VERSION ""

NS_ :

BS_:

BU_: FBD_HL IPB_App1 FBD_HM FBD_HR FBD_Miko FBD_MM FBD_Trunk FBD_VL FBD_VM FBD_VR Diagnosetool_CAN_FD_IPB_41

BO_ 352 StatusCPDData3FBD_Miko: 64 FBD_Miko
 SG_ StatusCPDData3FBD_Miko_MsgCounte : 0|8@1+ (1.0,0) [0|252] "" IPB_App1
 SG_ StatusCPDData3FBD_Miko_LinkID : 8|8@1+ (1.0,0) [0|252] "" IPB_App1
 SG_ StatusCPDData3FBD_Miko_AGCValue : 16|8@1+ (1.0,0) [0|252] "" IPB_App1
 SG_ StatusCPDData3FBD_Miko_Channel : 24|8@1+ (1.0,0) [0|252] "" IPB_App1
 SG_ StatusCPDData3FBD_Miko_CIRData00 : 32|8@1+ (1.0,0) [0|255] "" IPB_App1
 SG_ StatusCPDData3FBD_Miko_CIRData01 : 40|8@1+ (1.0,0) [0|255] "" IPB_App1
 SG_ StatusCPDData3FBD_Miko_CIRData02 : 48|8@1+ (1.0,0) [0|255] "" IPB_App1
 SG_ StatusCPDData3FBD_Miko_CIRData03 : 56|8@1+ (1.0,0) [0|255] "" IPB_App1
 SG_ StatusCPDData3FBD_Miko_CIRData04 : 64|8@1+ (1.0,0) [0|255] "" IPB_App1
 SG_ StatusCPDData3FBD_Miko_CIRData05 : 72|8@1+ (1.0,0) [0|255] "" IPB_App1
 SG_ StatusCPDData3FBD_Miko_CIRData06 : 80|8@1+ (1.0,0) [0|255] "" IPB_App1
 SG_ StatusCPDData3FBD_Miko_CIRData07 : 88|8@1+ (1.0,0) [0|255] "" IPB_App1
 SG_ StatusCPDData3FBD_Miko_CIRData08 : 96|8@1+ (1.0,0) [0|255] "" IPB_App1
 SG_ StatusCPDData3FBD_Miko_CIRData09 : 104|8@1+ (1.0,0) [0|255] "" IPB_App1
 SG_ StatusCPDData3FBD_Miko_CIRData10 : 112|8@1+ (1.0,0) [0|255] "" IPB_App1
 SG_ StatusCPDData3FBD_Miko_CIRData11 : 120|8@1+ (1.0,0) [0|255] "" IPB_App1
 SG_ StatusCPDData3FBD_Miko_CIRData12 : 128|8@1+ (1.0,0) [0|255] "" IPB_App1
 SG_ StatusCPDData3FBD_Miko_CIRData13 : 136|8@1+ (1.0,0) [0|255] "" IPB_App1
 SG_ StatusCPDData3FBD_Miko_CIRData14 : 144|8@1+ (1.0,0) [0|255] "" IPB_App1
 SG_ StatusCPDData3FBD_Miko_CIRData15 : 152|8@1+ (1.0,0) [0|255] "" IPB_App1
 SG_ StatusCPDData3FBD_Miko_CIRData16 : 160|8@1+ (1.0,0) [0|255] "" IPB_App1
 SG_ StatusCPDData3FBD_Miko_CIRData17 : 168|8@1+ (1.0,0) [0|255] "" IPB_App1
 SG_ StatusCPDData3FBD_Miko_CIRData18 : 176|8@1+ (1.0,0) [0|255] "" IPB_App1
 SG_ StatusCPDData3FBD_Miko_CIRData19 : 184|8@1+ (1.0,0) [0|255] "" IPB_App1
 SG_ StatusCPDData3FBD_Miko_CIRData20 : 192|8@1+ (1.0,0) [0|255] "" IPB_App1
 SG_ StatusCPDData3FBD_Miko_CIRData21 : 200|8@1+ (1.0,0) [0|255] "" IPB_App1
 SG_ StatusCPDData3FBD_Miko_CIRData22 : 208|8@1+ (1.0,0) [0|255] "" IPB_App1
 SG_ StatusCPDData3FBD_Miko_CIRData23 : 216|8@1+ (1.0,0) [0|255] "" IPB_App1
 SG_ StatusCPDData3FBD_Miko_CIRData24 : 224|8@1+ (1.0,0) [0|255] "" IPB_App1
 SG_ StatusCPDData3FBD_Miko_CIRData25 : 232|8@1+ (1.0,0) [0|255] "" IPB_App1
 SG_ StatusCPDData3FBD_Miko_CIRData26 : 240|8@1+ (1.0,0) [0|255] "" IPB_App1
 SG_ StatusCPDData3FBD_Miko_CIRData27 : 248|8@1+ (1.0,0) [0|255] "" IPB_App1
 SG_ StatusCPDData3FBD_Miko_CIRData28 : 256|8@1+ (1.0,0) [0|255] "" IPB_App1
 SG_ StatusCPDData3FBD_Miko_CIRData29 : 264|8@1+ (1.0,0) [0|255] "" IPB_App1
 SG_ StatusCPDData3FBD_Miko_CIRData30 : 272|8@1+ (1.0,0) [0|255] "" IPB_App1
 SG_ StatusCPDData3FBD_Miko_CIRData31 : 280|8@1+ (1.0,0) [0|255] "" IPB_App1
 SG_ StatusCPDData3FBD_Miko_CIRData32 : 288|8@1+ (1.0,0) [0|255] "" IPB_App1
 SG_ StatusCPDData3FBD_Miko_CIRData33 : 296|8@1+ (1.0,0) [0|255] "" IPB_App1
 SG_ StatusCPDData3FBD_Miko_CIRData34 : 304|8@1+ (1.0,0) [0|255] "" IPB_App1
 SG_ StatusCPDData3FBD_Miko_CIRData35 : 312|8@1+ (1.0,0) [0|255] "" IPB_App1
 SG_ StatusCPDData3FBD_Miko_CIRData36 : 320|8@1+ (1.0,0) [0|255] "" IPB_App1
 SG_ StatusCPDData3FBD_Miko_CIRData37 : 328|8@1+ (1.0,0) [0|255] "" IPB_App1
 SG_ StatusCPDData3FBD_Miko_CIRData38 : 336|8@1+ (1.0,0) [0|255] "" IPB_App1
 SG_ StatusCPDData3FBD_Miko_CIRData39 : 344|8@1+ (1.0,0) [0|255] "" IPB_App1
 SG_ StatusCPDData3FBD_Miko_CIRData40 : 352|8@1+ (1.0,0) [0|255] "" IPB_App1
 SG_ StatusCPDData3FBD_Miko_CIRData41 : 360|8@1+ (1.0,0) [0|255] "" IPB_App1
 SG_ StatusCPDData3FBD_Miko_CIRData42 : 368|8@1+ (1.0,0) [0|255] "" IPB_App1
 SG_ StatusCPDData3FBD_Miko_CIRData43 : 376|8@1+ (1.0,0) [0|255] "" IPB_App1
 SG_ StatusCPDData3FBD_Miko_CIRData44 : 384|8@1+ (1.0,0) [0|255] "" IPB_App1
 SG_ StatusCPDData3FBD_Miko_CIRData45 : 392|8@1+ (1.0,0) [0|255] "" IPB_App1
 SG_ StatusCPDData3FBD_Miko_CIRData46 : 400|8@1+ (1.0,0) [0|255] "" IPB_App1
 SG_ StatusCPDData3FBD_Miko_CIRData47 : 408|8@1+ (1.0,0) [0|255] "" IPB_App1
 SG_ StatusCPDData3FBD_Miko_CIRData48 : 416|8@1+ (1.0,0) [0|255] "" IPB_App1
 SG_ StatusCPDData3FBD_Miko_CIRData49 : 424|8@1+ (1.0,0) [0|255] "" IPB_App1
 SG_ StatusCPDData3FBD_Miko_CIRData50 : 432|8@1+ (1.0,0) [0|255] "" IPB_App1
 SG_ StatusCPDData3FBD_Miko_CIRData51 : 440|8@1+ (1.0,0) [0|255] "" IPB_App1
 SG_ StatusCPDData3FBD_Miko_CIRData52 : 448|8@1+ (1.0,0) [0|255] "" IPB_App1
 SG_ StatusCPDData3FBD_Miko_CIRData53 : 456|8@1+ (1.0,0) [0|255] "" IPB_App1
 SG_ StatusCPDData3FBD_Miko_CIRData54 : 464|8@1+ (1.0,0) [0|255] "" IPB_App1
 SG_ StatusCPDData3FBD_Miko_CIRData55 : 472|8@1+ (1.0,0) [0|255] "" IPB_App1
 SG_ StatusCPDData3FBD_Miko_CIRData56 : 480|8@1+ (1.0,0) [0|255] "" IPB_App1
 SG_ StatusCPDData3FBD_Miko_CIRData57 : 488|8@1+ (1.0,0) [0|255] "" IPB_App1
 SG_ StatusCPDData3FBD_Miko_CIRData58 : 496|8@1+ (1.0,0) [0|255] "" IPB_App1
 SG_ StatusCPDData3FBD_Miko_CIRData59 : 504|8@1+ (1.0,0) [0|255] "" IPB_App1

BO_ 835 StatusCPDData3FBD_MM: 64 FBD_MM
 SG_ StatusCPDData3FBD_MM_MsgCounter : 0|8@1+ (1.0,0) [0|252] "" IPB_App1
 SG_ StatusCPDData3FBD_MM_LinkID : 8|8@1+ (1.0,0) [0|252] "" IPB_App1
 SG_ StatusCPDData3FBD_MM_AGCValue : 16|8@1+ (1.0,0) [0|252] "" IPB_App1
 SG_ StatusCPDData3FBD_MM_Channel : 24|8@1+ (1.0,0) [0|252] "" IPB_App1
 SG_ StatusCPDData3FBD_MM_CIRData00 : 32|8@1+ (1.0,0) [0|255] "" IPB_App1
 SG_ StatusCPDData3FBD_MM_CIRData01 : 40|8@1+ (1.0,0) [0|255] "" IPB_App1
 SG_ StatusCPDData3FBD_MM_CIRData02 : 48|8@1+ (1.0,0) [0|255] "" IPB_App1
 SG_ StatusCPDData3FBD_MM_CIRData03 : 56|8@1+ (1.0,0) [0|255] "" IPB_App1
 SG_ StatusCPDData3FBD_MM_CIRData04 : 64|8@1+ (1.0,0) [0|255] "" IPB_App1
 SG_ StatusCPDData3FBD_MM_CIRData05 : 72|8@1+ (1.0,0) [0|255] "" IPB_App1
 SG_ StatusCPDData3FBD_MM_CIRData06 : 80|8@1+ (1.0,0) [0|255] "" IPB_App1
 SG_ StatusCPDData3FBD_MM_CIRData07 : 88|8@1+ (1.0,0) [0|255] "" IPB_App1
 SG_ StatusCPDData3FBD_MM_CIRData08 : 96|8@1+ (1.0,0) [0|255] "" IPB_App1
 SG_ StatusCPDData3FBD_MM_CIRData09 : 104|8@1+ (1.0,0) [0|255] "" IPB_App1
 SG_ StatusCPDData3FBD_MM_CIRData10 : 112|8@1+ (1.0,0) [0|255] "" IPB_App1
 SG_ StatusCPDData3FBD_MM_CIRData11 : 120|8@1+ (1.0,0) [0|255] "" IPB_App1
 SG_ StatusCPDData3FBD_MM_CIRData12 : 128|8@1+ (1.0,0) [0|255] "" IPB_App1
 SG_ StatusCPDData3FBD_MM_CIRData13 : 136|8@1+ (1.0,0) [0|255] "" IPB_App1
 SG_ StatusCPDData3FBD_MM_CIRData14 : 144|8@1+ (1.0,0) [0|255] "" IPB_App1
 SG_ StatusCPDData3FBD_MM_CIRData15 : 152|8@1+ (1.0,0) [0|255] "" IPB_App1
 SG_ StatusCPDData3FBD_MM_CIRData16 : 160|8@1+ (1.0,0) [0|255] "" IPB_App1
 SG_ StatusCPDData3FBD_MM_CIRData17 : 168|8@1+ (1.0,0) [0|255] "" IPB_App1
 SG_ StatusCPDData3FBD_MM_CIRData18 : 176|8@1+ (1.0,0) [0|255] "" IPB_App1
 SG_ StatusCPDData3FBD_MM_CIRData19 : 184|8@1+ (1.0,0) [0|255] "" IPB_App1
 SG_ StatusCPDData3FBD_MM_CIRData20 : 192|8@1+ (1.0,0) [0|255] "" IPB_App1
 SG_ StatusCPDData3FBD_MM_CIRData21 : 200|8@1+ (1.0,0) [0|255] "" IPB_App1
 SG_ StatusCPDData3FBD_MM_CIRData22 : 208|8@1+ (1.0,0) [0|255] "" IPB_App1
 SG_ StatusCPDData3FBD_MM_CIRData23 : 216|8@1+ (1.0,0) [0|255] "" IPB_App1
 SG_ StatusCPDData3FBD_MM_CIRData24 : 224|8@1+ (1.0,0) [0|255] "" IPB_App1
 SG_ StatusCPDData3FBD_MM_CIRData25 : 232|8@1+ (1.0,0) [0|255] "" IPB_App1
 SG_ StatusCPDData3FBD_MM_CIRData26 : 240|8@1+ (1.0,0) [0|255] "" IPB_App1
 SG_ StatusCPDData3FBD_MM_CIRData27 : 248|8@1+ (1.0,0) [0|255] "" IPB_App1
 SG_ StatusCPDData3FBD_MM_CIRData28 : 256|8@1+ (1.0,0) [0|255] "" IPB_App1
 SG_ StatusCPDData3FBD_MM_CIRData29 : 264|8@1+ (1.0,0) [0|255] "" IPB_App1
 SG_ StatusCPDData3FBD_MM_CIRData30 : 272|8@1+ (1.0,0) [0|255] "" IPB_App1
 SG_ StatusCPDData3FBD_MM_CIRData31 : 280|8@1+ (1.0,0) [0|255] "" IPB_App1
 SG_ StatusCPDData3FBD_MM_CIRData32 : 288|8@1+ (1.0,0) [0|255] "" IPB_App1
 SG_ StatusCPDData3FBD_MM_CIRData33 : 296|8@1+ (1.0,0) [0|255] "" IPB_App1
 SG_ StatusCPDData3FBD_MM_CIRData34 : 304|8@1+ (1.0,0) [0|255] "" IPB_App1
 SG_ StatusCPDData3FBD_MM_CIRData35 : 312|8@1+ (1.0,0) [0|255] "" IPB_App1
 SG_ StatusCPDData3FBD_MM_CIRData36 : 320|8@1+ (1.0,0) [0|255] "" IPB_App1
 SG_ StatusCPDData3FBD_MM_CIRData37 : 328|8@1+ (1.0,0) [0|255] "" IPB_App1
 SG_ StatusCPDData3FBD_MM_CIRData38 : 336|8@1+ (1.0,0) [0|255] "" IPB_App1
 SG_ StatusCPDData3FBD_MM_CIRData39 : 344|8@1+ (1.0,0) [0|255] "" IPB_App1
 SG_ StatusCPDData3FBD_MM_CIRData40 : 352|8@1+ (1.0,0) [0|255] "" IPB_App1
 SG_ StatusCPDData3FBD_MM_CIRData41 : 360|8@1+ (1.0,0) [0|255] "" IPB_App1
 SG_ StatusCPDData3FBD_MM_CIRData42 : 368|8@1+ (1.0,0) [0|255] "" IPB_App1
 SG_ StatusCPDData3FBD_MM_CIRData43 : 376|8@1+ (1.0,0) [0|255] "" IPB_App1
 SG_ StatusCPDData3FBD_MM_CIRData44 : 384|8@1+ (1.0,0) [0|255] "" IPB_App1
 SG_ StatusCPDData3FBD_MM_CIRData45 : 392|8@1+ (1.0,0) [0|255] "" IPB_App1
 SG_ StatusCPDData3FBD_MM_CIRData46 : 400|8@1+ (1.0,0) [0|255] "" IPB_App1
 SG_ StatusCPDData3FBD_MM_CIRData47 : 408|8@1+ (1.0,0) [0|255] "" IPB_App1
 SG_ StatusCPDData3FBD_MM_CIRData48 : 416|8@1+ (1.0,0) [0|255] "" IPB_App1
 SG_ StatusCPDData3FBD_MM_CIRData49 : 424|8@1+ (1.0,0) [0|255] "" IPB_App1
 SG_ StatusCPDData3FBD_MM_CIRData50 : 432|8@1+ (1.0,0) [0|255] "" IPB_App1
 SG_ StatusCPDData3FBD_MM_CIRData51 : 440|8@1+ (1.0,0) [0|255] "" IPB_App1
 SG_ StatusCPDData3FBD_MM_CIRData52 : 448|8@1+ (1.0,0) [0|255] "" IPB_App1
 SG_ StatusCPDData3FBD_MM_CIRData53 : 456|8@1+ (1.0,0) [0|255] "" IPB_App1
 SG_ StatusCPDData3FBD_MM_CIRData54 : 464|8@1+ (1.0,0) [0|255] "" IPB_App1
 SG_ StatusCPDData3FBD_MM_CIRData55 : 472|8@1+ (1.0,0) [0|255] "" IPB_App1
 SG_ StatusCPDData3FBD_MM_CIRData56 : 480|8@1+ (1.0,0) [0|255] "" IPB_App1
 SG_ StatusCPDData3FBD_MM_CIRData57 : 488|8@1+ (1.0,0) [0|255] "" IPB_App1
 SG_ StatusCPDData3FBD_MM_CIRData58 : 496|8@1+ (1.0,0) [0|255] "" IPB_App1
 SG_ StatusCPDData3FBD_MM_CIRData59 : 504|8@1+ (1.0,0) [0|255] "" IPB_App1

BO_ 353 StatusCPDData3FBD_Trunk: 64 FBD_Trunk
 SG_ StatusCPDData3FBD_Trunk_MsgCount : 0|8@1+ (1.0,0) [0|252] "" IPB_App1
 SG_ StatusCPDData3FBD_Trunk_LinkID : 8|8@1+ (1.0,0) [0|252] "" IPB_App1
 SG_ StatusCPDData3FBD_Trunk_AGCValue : 16|8@1+ (1.0,0) [0|252] "" IPB_App1
 SG_ StatusCPDData3FBD_Trunk_Channel : 24|8@1+ (1.0,0) [0|252] "" IPB_App1
 SG_ StatusCPDData3FBD_Trunk_CIRData0 : 32|8@1+ (1.0,0) [0|255] "" IPB_App1
 SG_ StatusCPDData3FBD_Trunk_CIRDat_2 : 40|8@1+ (1.0,0) [0|255] "" IPB_App1
 SG_ StatusCPDData3FBD_Trunk_CIRDat_3 : 48|8@1+ (1.0,0) [0|255] "" IPB_App1
 SG_ StatusCPDData3FBD_Trunk_CIRDat_4 : 56|8@1+ (1.0,0) [0|255] "" IPB_App1
 SG_ StatusCPDData3FBD_Trunk_CIRDat_5 : 64|8@1+ (1.0,0) [0|255] "" IPB_App1
 SG_ StatusCPDData3FBD_Trunk_CIRDat_6 : 72|8@1+ (1.0,0) [0|255] "" IPB_App1
 SG_ StatusCPDData3FBD_Trunk_CIRDat_7 : 80|8@1+ (1.0,0) [0|255] "" IPB_App1
 SG_ StatusCPDData3FBD_Trunk_CIRDat_8 : 88|8@1+ (1.0,0) [0|255] "" IPB_App1
 SG_ StatusCPDData3FBD_Trunk_CIRDat_9 : 96|8@1+ (1.0,0) [0|255] "" IPB_App1
 SG_ StatusCPDData3FBD_Trunk_CIRDa_10 : 104|8@1+ (1.0,0) [0|255] "" IPB_App1
 SG_ StatusCPDData3FBD_Trunk_CIRData1 : 112|8@1+ (1.0,0) [0|255] "" IPB_App1
 SG_ StatusCPDData3FBD_Trunk_CIRDa_11 : 120|8@1+ (1.0,0) [0|255] "" IPB_App1
 SG_ StatusCPDData3FBD_Trunk_CIRDa_12 : 128|8@1+ (1.0,0) [0|255] "" IPB_App1
 SG_ StatusCPDData3FBD_Trunk_CIRDa_13 : 136|8@1+ (1.0,0) [0|255] "" IPB_App1
 SG_ StatusCPDData3FBD_Trunk_CIRDa_14 : 144|8@1+ (1.0,0) [0|255] "" IPB_App1
 SG_ StatusCPDData3FBD_Trunk_CIRDa_15 : 152|8@1+ (1.0,0) [0|255] "" IPB_App1
 SG_ StatusCPDData3FBD_Trunk_CIRDa_16 : 160|8@1+ (1.0,0) [0|255] "" IPB_App1
 SG_ StatusCPDData3FBD_Trunk_CIRDa_17 : 168|8@1+ (1.0,0) [0|255] "" IPB_App1
 SG_ StatusCPDData3FBD_Trunk_CIRDa_18 : 176|8@1+ (1.0,0) [0|255] "" IPB_App1
 SG_ StatusCPDData3FBD_Trunk_CIRDa_19 : 184|8@1+ (1.0,0) [0|255] "" IPB_App1
 SG_ StatusCPDData3FBD_Trunk_CIRData2 : 192|8@1+ (1.0,0) [0|255] "" IPB_App1
 SG_ StatusCPDData3FBD_Trunk_CIRDa_20 : 200|8@1+ (1.0,0) [0|255] "" IPB_App1
 SG_ StatusCPDData3FBD_Trunk_CIRDa_21 : 208|8@1+ (1.0,0) [0|255] "" IPB_App1
 SG_ StatusCPDData3FBD_Trunk_CIRDa_22 : 216|8@1+ (1.0,0) [0|255] "" IPB_App1
 SG_ StatusCPDData3FBD_Trunk_CIRDa_23 : 224|8@1+ (1.0,0) [0|255] "" IPB_App1
 SG_ StatusCPDData3FBD_Trunk_CIRDa_24 : 232|8@1+ (1.0,0) [0|255] "" IPB_App1
 SG_ StatusCPDData3FBD_Trunk_CIRDa_25 : 240|8@1+ (1.0,0) [0|255] "" IPB_App1
 SG_ StatusCPDData3FBD_Trunk_CIRDa_26 : 248|8@1+ (1.0,0) [0|255] "" IPB_App1
 SG_ StatusCPDData3FBD_Trunk_CIRDa_27 : 256|8@1+ (1.0,0) [0|255] "" IPB_App1
 SG_ StatusCPDData3FBD_Trunk_CIRDa_28 : 264|8@1+ (1.0,0) [0|255] "" IPB_App1
 SG_ StatusCPDData3FBD_Trunk_CIRData3 : 272|8@1+ (1.0,0) [0|255] "" IPB_App1
 SG_ StatusCPDData3FBD_Trunk_CIRDa_29 : 280|8@1+ (1.0,0) [0|255] "" IPB_App1
 SG_ StatusCPDData3FBD_Trunk_CIRDa_30 : 288|8@1+ (1.0,0) [0|255] "" IPB_App1
 SG_ StatusCPDData3FBD_Trunk_CIRDa_31 : 296|8@1+ (1.0,0) [0|255] "" IPB_App1
 SG_ StatusCPDData3FBD_Trunk_CIRDa_32 : 304|8@1+ (1.0,0) [0|255] "" IPB_App1
 SG_ StatusCPDData3FBD_Trunk_CIRDa_33 : 312|8@1+ (1.0,0) [0|255] "" IPB_App1
 SG_ StatusCPDData3FBD_Trunk_CIRDa_34 : 320|8@1+ (1.0,0) [0|255] "" IPB_App1
 SG_ StatusCPDData3FBD_Trunk_CIRDa_35 : 328|8@1+ (1.0,0) [0|255] "" IPB_App1
 SG_ StatusCPDData3FBD_Trunk_CIRDa_36 : 336|8@1+ (1.0,0) [0|255] "" IPB_App1
 SG_ StatusCPDData3FBD_Trunk_CIRDa_37 : 344|8@1+ (1.0,0) [0|255] "" IPB_App1
 SG_ StatusCPDData3FBD_Trunk_CIRData4 : 352|8@1+ (1.0,0) [0|255] "" IPB_App1
 SG_ StatusCPDData3FBD_Trunk_CIRDa_38 : 360|8@1+ (1.0,0) [0|255] "" IPB_App1
 SG_ StatusCPDData3FBD_Trunk_CIRDa_39 : 368|8@1+ (1.0,0) [0|255] "" IPB_App1
 SG_ StatusCPDData3FBD_Trunk_CIRDa_40 : 376|8@1+ (1.0,0) [0|255] "" IPB_App1
 SG_ StatusCPDData3FBD_Trunk_CIRDa_41 : 384|8@1+ (1.0,0) [0|255] "" IPB_App1
 SG_ StatusCPDData3FBD_Trunk_CIRDa_42 : 392|8@1+ (1.0,0) [0|255] "" IPB_App1
 SG_ StatusCPDData3FBD_Trunk_CIRDa_43 : 400|8@1+ (1.0,0) [0|255] "" IPB_App1
 SG_ StatusCPDData3FBD_Trunk_CIRDa_44 : 408|8@1+ (1.0,0) [0|255] "" IPB_App1
 SG_ StatusCPDData3FBD_Trunk_CIRDa_45 : 416|8@1+ (1.0,0) [0|255] "" IPB_App1
 SG_ StatusCPDData3FBD_Trunk_CIRDa_46 : 424|8@1+ (1.0,0) [0|255] "" IPB_App1
 SG_ StatusCPDData3FBD_Trunk_CIRData5 : 432|8@1+ (1.0,0) [0|255] "" IPB_App1
 SG_ StatusCPDData3FBD_Trunk_CIRDa_47 : 440|8@1+ (1.0,0) [0|255] "" IPB_App1
 SG_ StatusCPDData3FBD_Trunk_CIRDa_48 : 448|8@1+ (1.0,0) [0|255] "" IPB_App1
 SG_ StatusCPDData3FBD_Trunk_CIRDa_49 : 456|8@1+ (1.0,0) [0|255] "" IPB_App1
 SG_ StatusCPDData3FBD_Trunk_CIRDa_50 : 464|8@1+ (1.0,0) [0|255] "" IPB_App1
 SG_ StatusCPDData3FBD_Trunk_CIRDa_51 : 472|8@1+ (1.0,0) [0|255] "" IPB_App1
 SG_ StatusCPDData3FBD_Trunk_CIRDa_52 : 480|8@1+ (1.0,0) [0|255] "" IPB_App1
 SG_ StatusCPDData3FBD_Trunk_CIRDa_53 : 488|8@1+ (1.0,0) [0|255] "" IPB_App1
 SG_ StatusCPDData3FBD_Trunk_CIRDa_54 : 496|8@1+ (1.0,0) [0|255] "" IPB_App1
 SG_ StatusCPDData3FBD_Trunk_CIRDa_55 : 504|8@1+ (1.0,0) [0|255] "" IPB_App1

BO_ 354 StatusCPDData3FBD_VL: 64 FBD_VL
 SG_ StatusCPDData3FBD_VL_MsgCounter : 0|8@1+ (1.0,0) [0|252] "" IPB_App1
 SG_ StatusCPDData3FBD_VL_LinkID : 8|8@1+ (1.0,0) [0|252] "" IPB_App1
 SG_ StatusCPDData3FBD_VL_AGCValue : 16|8@1+ (1.0,0) [0|252] "" IPB_App1
 SG_ StatusCPDData3FBD_VL_Channel : 24|8@1+ (1.0,0) [0|252] "" IPB_App1
 SG_ StatusCPDData3FBD_VL_CIRData00 : 32|8@1+ (1.0,0) [0|255] "" IPB_App1
 SG_ StatusCPDData3FBD_VL_CIRData01 : 40|8@1+ (1.0,0) [0|255] "" IPB_App1
 SG_ StatusCPDData3FBD_VL_CIRData02 : 48|8@1+ (1.0,0) [0|255] "" IPB_App1
 SG_ StatusCPDData3FBD_VL_CIRData03 : 56|8@1+ (1.0,0) [0|255] "" IPB_App1
 SG_ StatusCPDData3FBD_VL_CIRData04 : 64|8@1+ (1.0,0) [0|255] "" IPB_App1
 SG_ StatusCPDData3FBD_VL_CIRData05 : 72|8@1+ (1.0,0) [0|255] "" IPB_App1
 SG_ StatusCPDData3FBD_VL_CIRData06 : 80|8@1+ (1.0,0) [0|255] "" IPB_App1
 SG_ StatusCPDData3FBD_VL_CIRData07 : 88|8@1+ (1.0,0) [0|255] "" IPB_App1
 SG_ StatusCPDData3FBD_VL_CIRData08 : 96|8@1+ (1.0,0) [0|255] "" IPB_App1
 SG_ StatusCPDData3FBD_VL_CIRData09 : 104|8@1+ (1.0,0) [0|255] "" IPB_App1
 SG_ StatusCPDData3FBD_VL_CIRData10 : 112|8@1+ (1.0,0) [0|255] "" IPB_App1
 SG_ StatusCPDData3FBD_VL_CIRData11 : 120|8@1+ (1.0,0) [0|255] "" IPB_App1
 SG_ StatusCPDData3FBD_VL_CIRData12 : 128|8@1+ (1.0,0) [0|255] "" IPB_App1
 SG_ StatusCPDData3FBD_VL_CIRData13 : 136|8@1+ (1.0,0) [0|255] "" IPB_App1
 SG_ StatusCPDData3FBD_VL_CIRData14 : 144|8@1+ (1.0,0) [0|255] "" IPB_App1
 SG_ StatusCPDData3FBD_VL_CIRData15 : 152|8@1+ (1.0,0) [0|255] "" IPB_App1
 SG_ StatusCPDData3FBD_VL_CIRData16 : 160|8@1+ (1.0,0) [0|255] "" IPB_App1
 SG_ StatusCPDData3FBD_VL_CIRData17 : 168|8@1+ (1.0,0) [0|255] "" IPB_App1
 SG_ StatusCPDData3FBD_VL_CIRData18 : 176|8@1+ (1.0,0) [0|255] "" IPB_App1
 SG_ StatusCPDData3FBD_VL_CIRData19 : 184|8@1+ (1.0,0) [0|255] "" IPB_App1
 SG_ StatusCPDData3FBD_VL_CIRData20 : 192|8@1+ (1.0,0) [0|255] "" IPB_App1
 SG_ StatusCPDData3FBD_VL_CIRData21 : 200|8@1+ (1.0,0) [0|255] "" IPB_App1
 SG_ StatusCPDData3FBD_VL_CIRData22 : 208|8@1+ (1.0,0) [0|255] "" IPB_App1
 SG_ StatusCPDData3FBD_VL_CIRData23 : 216|8@1+ (1.0,0) [0|255] "" IPB_App1
 SG_ StatusCPDData3FBD_VL_CIRData24 : 224|8@1+ (1.0,0) [0|255] "" IPB_App1
 SG_ StatusCPDData3FBD_VL_CIRData25 : 232|8@1+ (1.0,0) [0|255] "" IPB_App1
 SG_ StatusCPDData3FBD_VL_CIRData26 : 240|8@1+ (1.0,0) [0|255] "" IPB_App1
 SG_ StatusCPDData3FBD_VL_CIRData27 : 248|8@1+ (1.0,0) [0|255] "" IPB_App1
 SG_ StatusCPDData3FBD_VL_CIRData28 : 256|8@1+ (1.0,0) [0|255] "" IPB_App1
 SG_ StatusCPDData3FBD_VL_CIRData29 : 264|8@1+ (1.0,0) [0|255] "" IPB_App1
 SG_ StatusCPDData3FBD_VL_CIRData30 : 272|8@1+ (1.0,0) [0|255] "" IPB_App1
 SG_ StatusCPDData3FBD_VL_CIRData31 : 280|8@1+ (1.0,0) [0|255] "" IPB_App1
 SG_ StatusCPDData3FBD_VL_CIRData32 : 288|8@1+ (1.0,0) [0|255] "" IPB_App1
 SG_ StatusCPDData3FBD_VL_CIRData33 : 296|8@1+ (1.0,0) [0|255] "" IPB_App1
 SG_ StatusCPDData3FBD_VL_CIRData34 : 304|8@1+ (1.0,0) [0|255] "" IPB_App1
 SG_ StatusCPDData3FBD_VL_CIRData35 : 312|8@1+ (1.0,0) [0|255] "" IPB_App1
 SG_ StatusCPDData3FBD_VL_CIRData36 : 320|8@1+ (1.0,0) [0|255] "" IPB_App1
 SG_ StatusCPDData3FBD_VL_CIRData37 : 328|8@1+ (1.0,0) [0|255] "" IPB_App1
 SG_ StatusCPDData3FBD_VL_CIRData38 : 336|8@1+ (1.0,0) [0|255] "" IPB_App1
 SG_ StatusCPDData3FBD_VL_CIRData39 : 344|8@1+ (1.0,0) [0|255] "" IPB_App1
 SG_ StatusCPDData3FBD_VL_CIRData40 : 352|8@1+ (1.0,0) [0|255] "" IPB_App1
 SG_ StatusCPDData3FBD_VL_CIRData41 : 360|8@1+ (1.0,0) [0|255] "" IPB_App1
 SG_ StatusCPDData3FBD_VL_CIRData42 : 368|8@1+ (1.0,0) [0|255] "" IPB_App1
 SG_ StatusCPDData3FBD_VL_CIRData43 : 376|8@1+ (1.0,0) [0|255] "" IPB_App1
 SG_ StatusCPDData3FBD_VL_CIRData44 : 384|8@1+ (1.0,0) [0|255] "" IPB_App1
 SG_ StatusCPDData3FBD_VL_CIRData45 : 392|8@1+ (1.0,0) [0|255] "" IPB_App1
 SG_ StatusCPDData3FBD_VL_CIRData46 : 400|8@1+ (1.0,0) [0|255] "" IPB_App1
 SG_ StatusCPDData3FBD_VL_CIRData47 : 408|8@1+ (1.0,0) [0|255] "" IPB_App1
 SG_ StatusCPDData3FBD_VL_CIRData48 : 416|8@1+ (1.0,0) [0|255] "" IPB_App1
 SG_ StatusCPDData3FBD_VL_CIRData49 : 424|8@1+ (1.0,0) [0|255] "" IPB_App1
 SG_ StatusCPDData3FBD_VL_CIRData50 : 432|8@1+ (1.0,0) [0|255] "" IPB_App1
 SG_ StatusCPDData3FBD_VL_CIRData51 : 440|8@1+ (1.0,0) [0|255] "" IPB_App1
 SG_ StatusCPDData3FBD_VL_CIRData52 : 448|8@1+ (1.0,0) [0|255] "" IPB_App1
 SG_ StatusCPDData3FBD_VL_CIRData53 : 456|8@1+ (1.0,0) [0|255] "" IPB_App1
 SG_ StatusCPDData3FBD_VL_CIRData54 : 464|8@1+ (1.0,0) [0|255] "" IPB_App1
 SG_ StatusCPDData3FBD_VL_CIRData55 : 472|8@1+ (1.0,0) [0|255] "" IPB_App1
 SG_ StatusCPDData3FBD_VL_CIRData56 : 480|8@1+ (1.0,0) [0|255] "" IPB_App1
 SG_ StatusCPDData3FBD_VL_CIRData57 : 488|8@1+ (1.0,0) [0|255] "" IPB_App1
 SG_ StatusCPDData3FBD_VL_CIRData58 : 496|8@1+ (1.0,0) [0|255] "" IPB_App1
 SG_ StatusCPDData3FBD_VL_CIRData59 : 504|8@1+ (1.0,0) [0|255] "" IPB_App1

BO_ 350 StatusCPDData3FBD_VM: 64 FBD_VM
 SG_ StatusCPDData3FBD_VM_MsgCounter : 0|8@1+ (1.0,0) [0|252] "" IPB_App1
 SG_ StatusCPDData3FBD_VM_LinkID : 8|8@1+ (1.0,0) [0|252] "" IPB_App1
 SG_ StatusCPDData3FBD_VM_AGCValue : 16|8@1+ (1.0,0) [0|252] "" IPB_App1
 SG_ StatusCPDData3FBD_VM_Channel : 24|8@1+ (1.0,0) [0|252] "" IPB_App1
 SG_ StatusCPDData3FBD_VM_CIRData00 : 32|8@1+ (1.0,0) [0|255] "" IPB_App1
 SG_ StatusCPDData3FBD_VM_CIRData01 : 40|8@1+ (1.0,0) [0|255] "" IPB_App1
 SG_ StatusCPDData3FBD_VM_CIRData02 : 48|8@1+ (1.0,0) [0|255] "" IPB_App1
 SG_ StatusCPDData3FBD_VM_CIRData03 : 56|8@1+ (1.0,0) [0|255] "" IPB_App1
 SG_ StatusCPDData3FBD_VM_CIRData04 : 64|8@1+ (1.0,0) [0|255] "" IPB_App1
 SG_ StatusCPDData3FBD_VM_CIRData05 : 72|8@1+ (1.0,0) [0|255] "" IPB_App1
 SG_ StatusCPDData3FBD_VM_CIRData06 : 80|8@1+ (1.0,0) [0|255] "" IPB_App1
 SG_ StatusCPDData3FBD_VM_CIRData07 : 88|8@1+ (1.0,0) [0|255] "" IPB_App1
 SG_ StatusCPDData3FBD_VM_CIRData08 : 96|8@1+ (1.0,0) [0|255] "" IPB_App1
 SG_ StatusCPDData3FBD_VM_CIRData09 : 104|8@1+ (1.0,0) [0|255] "" IPB_App1
 SG_ StatusCPDData3FBD_VM_CIRData10 : 112|8@1+ (1.0,0) [0|255] "" IPB_App1
 SG_ StatusCPDData3FBD_VM_CIRData11 : 120|8@1+ (1.0,0) [0|255] "" IPB_App1
 SG_ StatusCPDData3FBD_VM_CIRData12 : 128|8@1+ (1.0,0) [0|255] "" IPB_App1
 SG_ StatusCPDData3FBD_VM_CIRData13 : 136|8@1+ (1.0,0) [0|255] "" IPB_App1
 SG_ StatusCPDData3FBD_VM_CIRData14 : 144|8@1+ (1.0,0) [0|255] "" IPB_App1
 SG_ StatusCPDData3FBD_VM_CIRData15 : 152|8@1+ (1.0,0) [0|255] "" IPB_App1
 SG_ StatusCPDData3FBD_VM_CIRData16 : 160|8@1+ (1.0,0) [0|255] "" IPB_App1
 SG_ StatusCPDData3FBD_VM_CIRData17 : 168|8@1+ (1.0,0) [0|255] "" IPB_App1
 SG_ StatusCPDData3FBD_VM_CIRData18 : 176|8@1+ (1.0,0) [0|255] "" IPB_App1
 SG_ StatusCPDData3FBD_VM_CIRData19 : 184|8@1+ (1.0,0) [0|255] "" IPB_App1
 SG_ StatusCPDData3FBD_VM_CIRData20 : 192|8@1+ (1.0,0) [0|255] "" IPB_App1
 SG_ StatusCPDData3FBD_VM_CIRData21 : 200|8@1+ (1.0,0) [0|255] "" IPB_App1
 SG_ StatusCPDData3FBD_VM_CIRData22 : 208|8@1+ (1.0,0) [0|255] "" IPB_App1
 SG_ StatusCPDData3FBD_VM_CIRData23 : 216|8@1+ (1.0,0) [0|255] "" IPB_App1
 SG_ StatusCPDData3FBD_VM_CIRData24 : 224|8@1+ (1.0,0) [0|255] "" IPB_App1
 SG_ StatusCPDData3FBD_VM_CIRData25 : 232|8@1+ (1.0,0) [0|255] "" IPB_App1
 SG_ StatusCPDData3FBD_VM_CIRData26 : 240|8@1+ (1.0,0) [0|255] "" IPB_App1
 SG_ StatusCPDData3FBD_VM_CIRData27 : 248|8@1+ (1.0,0) [0|255] "" IPB_App1
 SG_ StatusCPDData3FBD_VM_CIRData28 : 256|8@1+ (1.0,0) [0|255] "" IPB_App1
 SG_ StatusCPDData3FBD_VM_CIRData29 : 264|8@1+ (1.0,0) [0|255] "" IPB_App1
 SG_ StatusCPDData3FBD_VM_CIRData30 : 272|8@1+ (1.0,0) [0|255] "" IPB_App1
 SG_ StatusCPDData3FBD_VM_CIRData31 : 280|8@1+ (1.0,0) [0|255] "" IPB_App1
 SG_ StatusCPDData3FBD_VM_CIRData32 : 288|8@1+ (1.0,0) [0|255] "" IPB_App1
 SG_ StatusCPDData3FBD_VM_CIRData33 : 296|8@1+ (1.0,0) [0|255] "" IPB_App1
 SG_ StatusCPDData3FBD_VM_CIRData34 : 304|8@1+ (1.0,0) [0|255] "" IPB_App1
 SG_ StatusCPDData3FBD_VM_CIRData35 : 312|8@1+ (1.0,0) [0|255] "" IPB_App1
 SG_ StatusCPDData3FBD_VM_CIRData36 : 320|8@1+ (1.0,0) [0|255] "" IPB_App1
 SG_ StatusCPDData3FBD_VM_CIRData37 : 328|8@1+ (1.0,0) [0|255] "" IPB_App1
 SG_ StatusCPDData3FBD_VM_CIRData38 : 336|8@1+ (1.0,0) [0|255] "" IPB_App1
 SG_ StatusCPDData3FBD_VM_CIRData39 : 344|8@1+ (1.0,0) [0|255] "" IPB_App1
 SG_ StatusCPDData3FBD_VM_CIRData40 : 352|8@1+ (1.0,0) [0|255] "" IPB_App1
 SG_ StatusCPDData3FBD_VM_CIRData41 : 360|8@1+ (1.0,0) [0|255] "" IPB_App1
 SG_ StatusCPDData3FBD_VM_CIRData42 : 368|8@1+ (1.0,0) [0|255] "" IPB_App1
 SG_ StatusCPDData3FBD_VM_CIRData43 : 376|8@1+ (1.0,0) [0|255] "" IPB_App1
 SG_ StatusCPDData3FBD_VM_CIRData44 : 384|8@1+ (1.0,0) [0|255] "" IPB_App1
 SG_ StatusCPDData3FBD_VM_CIRData45 : 392|8@1+ (1.0,0) [0|255] "" IPB_App1
 SG_ StatusCPDData3FBD_VM_CIRData46 : 400|8@1+ (1.0,0) [0|255] "" IPB_App1
 SG_ StatusCPDData3FBD_VM_CIRData47 : 408|8@1+ (1.0,0) [0|255] "" IPB_App1
 SG_ StatusCPDData3FBD_VM_CIRData48 : 416|8@1+ (1.0,0) [0|255] "" IPB_App1
 SG_ StatusCPDData3FBD_VM_CIRData49 : 424|8@1+ (1.0,0) [0|255] "" IPB_App1
 SG_ StatusCPDData3FBD_VM_CIRData50 : 432|8@1+ (1.0,0) [0|255] "" IPB_App1
 SG_ StatusCPDData3FBD_VM_CIRData51 : 440|8@1+ (1.0,0) [0|255] "" IPB_App1
 SG_ StatusCPDData3FBD_VM_CIRData52 : 448|8@1+ (1.0,0) [0|255] "" IPB_App1
 SG_ StatusCPDData3FBD_VM_CIRData53 : 456|8@1+ (1.0,0) [0|255] "" IPB_App1
 SG_ StatusCPDData3FBD_VM_CIRData54 : 464|8@1+ (1.0,0) [0|255] "" IPB_App1
 SG_ StatusCPDData3FBD_VM_CIRData55 : 472|8@1+ (1.0,0) [0|255] "" IPB_App1
 SG_ StatusCPDData3FBD_VM_CIRData56 : 480|8@1+ (1.0,0) [0|255] "" IPB_App1
 SG_ StatusCPDData3FBD_VM_CIRData57 : 488|8@1+ (1.0,0) [0|255] "" IPB_App1
 SG_ StatusCPDData3FBD_VM_CIRData58 : 496|8@1+ (1.0,0) [0|255] "" IPB_App1
 SG_ StatusCPDData3FBD_VM_CIRData59 : 504|8@1+ (1.0,0) [0|255] "" IPB_App1

BO_ 355 StatusCPDData3FBD_VR: 64 FBD_VR
 SG_ StatusCPDData3FBD_VR_MsgCounter : 0|8@1+ (1.0,0) [0|252] "" IPB_App1
 SG_ StatusCPDData3FBD_VR_LinkID : 8|8@1+ (1.0,0) [0|252] "" IPB_App1
 SG_ StatusCPDData3FBD_VR_AGCValue : 16|8@1+ (1.0,0) [0|252] "" IPB_App1
 SG_ StatusCPDData3FBD_VR_Channel : 24|8@1+ (1.0,0) [0|252] "" IPB_App1
 SG_ StatusCPDData3FBD_VR_CIRData00 : 32|8@1+ (1.0,0) [0|255] "" IPB_App1
 SG_ StatusCPDData3FBD_VR_CIRData01 : 40|8@1+ (1.0,0) [0|255] "" IPB_App1
 SG_ StatusCPDData3FBD_VR_CIRData02 : 48|8@1+ (1.0,0) [0|255] "" IPB_App1
 SG_ StatusCPDData3FBD_VR_CIRData03 : 56|8@1+ (1.0,0) [0|255] "" IPB_App1
 SG_ StatusCPDData3FBD_VR_CIRData04 : 64|8@1+ (1.0,0) [0|255] "" IPB_App1
 SG_ StatusCPDData3FBD_VR_CIRData05 : 72|8@1+ (1.0,0) [0|255] "" IPB_App1
 SG_ StatusCPDData3FBD_VR_CIRData06 : 80|8@1+ (1.0,0) [0|255] "" IPB_App1
 SG_ StatusCPDData3FBD_VR_CIRData07 : 88|8@1+ (1.0,0) [0|255] "" IPB_App1
 SG_ StatusCPDData3FBD_VR_CIRData08 : 96|8@1+ (1.0,0) [0|255] "" IPB_App1
 SG_ StatusCPDData3FBD_VR_CIRData09 : 104|8@1+ (1.0,0) [0|255] "" IPB_App1
 SG_ StatusCPDData3FBD_VR_CIRData10 : 112|8@1+ (1.0,0) [0|255] "" IPB_App1
 SG_ StatusCPDData3FBD_VR_CIRData11 : 120|8@1+ (1.0,0) [0|255] "" IPB_App1
 SG_ StatusCPDData3FBD_VR_CIRData12 : 128|8@1+ (1.0,0) [0|255] "" IPB_App1
 SG_ StatusCPDData3FBD_VR_CIRData13 : 136|8@1+ (1.0,0) [0|255] "" IPB_App1
 SG_ StatusCPDData3FBD_VR_CIRData14 : 144|8@1+ (1.0,0) [0|255] "" IPB_App1
 SG_ StatusCPDData3FBD_VR_CIRData15 : 152|8@1+ (1.0,0) [0|255] "" IPB_App1
 SG_ StatusCPDData3FBD_VR_CIRData16 : 160|8@1+ (1.0,0) [0|255] "" IPB_App1
 SG_ StatusCPDData3FBD_VR_CIRData17 : 168|8@1+ (1.0,0) [0|255] "" IPB_App1
 SG_ StatusCPDData3FBD_VR_CIRData18 : 176|8@1+ (1.0,0) [0|255] "" IPB_App1
 SG_ StatusCPDData3FBD_VR_CIRData19 : 184|8@1+ (1.0,0) [0|255] "" IPB_App1
 SG_ StatusCPDData3FBD_VR_CIRData20 : 192|8@1+ (1.0,0) [0|255] "" IPB_App1
 SG_ StatusCPDData3FBD_VR_CIRData21 : 200|8@1+ (1.0,0) [0|255] "" IPB_App1
 SG_ StatusCPDData3FBD_VR_CIRData22 : 208|8@1+ (1.0,0) [0|255] "" IPB_App1
 SG_ StatusCPDData3FBD_VR_CIRData23 : 216|8@1+ (1.0,0) [0|255] "" IPB_App1
 SG_ StatusCPDData3FBD_VR_CIRData24 : 224|8@1+ (1.0,0) [0|255] "" IPB_App1
 SG_ StatusCPDData3FBD_VR_CIRData25 : 232|8@1+ (1.0,0) [0|255] "" IPB_App1
 SG_ StatusCPDData3FBD_VR_CIRData26 : 240|8@1+ (1.0,0) [0|255] "" IPB_App1
 SG_ StatusCPDData3FBD_VR_CIRData27 : 248|8@1+ (1.0,0) [0|255] "" IPB_App1
 SG_ StatusCPDData3FBD_VR_CIRData28 : 256|8@1+ (1.0,0) [0|255] "" IPB_App1
 SG_ StatusCPDData3FBD_VR_CIRData29 : 264|8@1+ (1.0,0) [0|255] "" IPB_App1
 SG_ StatusCPDData3FBD_VR_CIRData30 : 272|8@1+ (1.0,0) [0|255] "" IPB_App1
 SG_ StatusCPDData3FBD_VR_CIRData31 : 280|8@1+ (1.0,0) [0|255] "" IPB_App1
 SG_ StatusCPDData3FBD_VR_CIRData32 : 288|8@1+ (1.0,0) [0|255] "" IPB_App1
 SG_ StatusCPDData3FBD_VR_CIRData33 : 296|8@1+ (1.0,0) [0|255] "" IPB_App1
 SG_ StatusCPDData3FBD_VR_CIRData34 : 304|8@1+ (1.0,0) [0|255] "" IPB_App1
 SG_ StatusCPDData3FBD_VR_CIRData35 : 312|8@1+ (1.0,0) [0|255] "" IPB_App1
 SG_ StatusCPDData3FBD_VR_CIRData36 : 320|8@1+ (1.0,0) [0|255] "" IPB_App1
 SG_ StatusCPDData3FBD_VR_CIRData37 : 328|8@1+ (1.0,0) [0|255] "" IPB_App1
 SG_ StatusCPDData3FBD_VR_CIRData38 : 336|8@1+ (1.0,0) [0|255] "" IPB_App1
 SG_ StatusCPDData3FBD_VR_CIRData39 : 344|8@1+ (1.0,0) [0|255] "" IPB_App1
 SG_ StatusCPDData3FBD_VR_CIRData40 : 352|8@1+ (1.0,0) [0|255] "" IPB_App1
 SG_ StatusCPDData3FBD_VR_CIRData41 : 360|8@1+ (1.0,0) [0|255] "" IPB_App1
 SG_ StatusCPDData3FBD_VR_CIRData42 : 368|8@1+ (1.0,0) [0|255] "" IPB_App1
 SG_ StatusCPDData3FBD_VR_CIRData43 : 376|8@1+ (1.0,0) [0|255] "" IPB_App1
 SG_ StatusCPDData3FBD_VR_CIRData44 : 384|8@1+ (1.0,0) [0|255] "" IPB_App1
 SG_ StatusCPDData3FBD_VR_CIRData45 : 392|8@1+ (1.0,0) [0|255] "" IPB_App1
 SG_ StatusCPDData3FBD_VR_CIRData46 : 400|8@1+ (1.0,0) [0|255] "" IPB_App1
 SG_ StatusCPDData3FBD_VR_CIRData47 : 408|8@1+ (1.0,0) [0|255] "" IPB_App1
 SG_ StatusCPDData3FBD_VR_CIRData48 : 416|8@1+ (1.0,0) [0|255] "" IPB_App1
 SG_ StatusCPDData3FBD_VR_CIRData49 : 424|8@1+ (1.0,0) [0|255] "" IPB_App1
 SG_ StatusCPDData3FBD_VR_CIRData50 : 432|8@1+ (1.0,0) [0|255] "" IPB_App1
 SG_ StatusCPDData3FBD_VR_CIRData51 : 440|8@1+ (1.0,0) [0|255] "" IPB_App1
 SG_ StatusCPDData3FBD_VR_CIRData52 : 448|8@1+ (1.0,0) [0|255] "" IPB_App1
 SG_ StatusCPDData3FBD_VR_CIRData53 : 456|8@1+ (1.0,0) [0|255] "" IPB_App1
 SG_ StatusCPDData3FBD_VR_CIRData54 : 464|8@1+ (1.0,0) [0|255] "" IPB_App1
 SG_ StatusCPDData3FBD_VR_CIRData55 : 472|8@1+ (1.0,0) [0|255] "" IPB_App1
 SG_ StatusCPDData3FBD_VR_CIRData56 : 480|8@1+ (1.0,0) [0|255] "" IPB_App1
 SG_ StatusCPDData3FBD_VR_CIRData57 : 488|8@1+ (1.0,0) [0|255] "" IPB_App1
 SG_ StatusCPDData3FBD_VR_CIRData58 : 496|8@1+ (1.0,0) [0|255] "" IPB_App1
 SG_ StatusCPDData3FBD_VR_CIRData59 : 504|8@1+ (1.0,0) [0|255] "" IPB_App1

BO_ 366 StatusCPDData4FBD_HL: 64 FBD_HL
 SG_ StatusCPDData4FBD_HL_MsgCounter : 0|8@1+ (1.0,0) [0|252] "" IPB_App1
 SG_ StatusCPDData4FBD_HL_LinkID : 8|8@1+ (1.0,0) [0|252] "" IPB_App1
 SG_ StatusCPDData4FBD_HL_CollisionCo : 16|8@1+ (1.0,0) [0|252] "" IPB_App1
 SG_ StatusCPDData4FBD_HL_CIRSetting : 24|8@1+ (1,0) [0|0] "" IPB_App1
 SG_ StatusCPDData4FBD_HL_CIRData60 : 32|8@1+ (1.0,0) [0|255] "" IPB_App1
 SG_ StatusCPDData4FBD_HL_CIRData61 : 40|8@1+ (1.0,0) [0|255] "" IPB_App1
 SG_ StatusCPDData4FBD_HL_CIRData62 : 48|8@1+ (1.0,0) [0|255] "" IPB_App1
 SG_ StatusCPDData4FBD_HL_CIRData63 : 56|8@1+ (1.0,0) [0|255] "" IPB_App1
 SG_ StatusCPDData4FBD_HL_CIRData64 : 64|8@1+ (1.0,0) [0|255] "" IPB_App1
 SG_ StatusCPDData4FBD_HL_CIRData65 : 72|8@1+ (1.0,0) [0|255] "" IPB_App1
 SG_ StatusCPDData4FBD_HL_CIRData66 : 80|8@1+ (1.0,0) [0|255] "" IPB_App1
 SG_ StatusCPDData4FBD_HL_CIRData67 : 88|8@1+ (1.0,0) [0|255] "" IPB_App1
 SG_ StatusCPDData4FBD_HL_CIRData68 : 96|8@1+ (1.0,0) [0|255] "" IPB_App1
 SG_ StatusCPDData4FBD_HL_CIRData69 : 104|8@1+ (1.0,0) [0|255] "" IPB_App1
 SG_ StatusCPDData4FBD_HL_CIRData70 : 112|8@1+ (1.0,0) [0|255] "" IPB_App1
 SG_ StatusCPDData4FBD_HL_CIRData71 : 120|8@1+ (1.0,0) [0|255] "" IPB_App1
 SG_ StatusCPDData4FBD_HL_CIRData72 : 128|8@1+ (1.0,0) [0|255] "" IPB_App1
 SG_ StatusCPDData4FBD_HL_CIRData73 : 136|8@1+ (1.0,0) [0|255] "" IPB_App1
 SG_ StatusCPDData4FBD_HL_CIRData74 : 144|8@1+ (1.0,0) [0|255] "" IPB_App1
 SG_ StatusCPDData4FBD_HL_CIRData75 : 152|8@1+ (1.0,0) [0|255] "" IPB_App1
 SG_ StatusCPDData4FBD_HL_CIRData76 : 160|8@1+ (1.0,0) [0|255] "" IPB_App1
 SG_ StatusCPDData4FBD_HL_CIRData77 : 168|8@1+ (1.0,0) [0|255] "" IPB_App1
 SG_ StatusCPDData4FBD_HL_CIRData78 : 176|8@1+ (1.0,0) [0|255] "" IPB_App1
 SG_ StatusCPDData4FBD_HL_CIRData79 : 184|8@1+ (1.0,0) [0|255] "" IPB_App1
 SG_ StatusCPDData4FBD_HL_CIRData80 : 192|8@1+ (1.0,0) [0|255] "" IPB_App1
 SG_ StatusCPDData4FBD_HL_CIRData81 : 200|8@1+ (1.0,0) [0|255] "" IPB_App1
 SG_ StatusCPDData4FBD_HL_CIRData82 : 208|8@1+ (1.0,0) [0|255] "" IPB_App1
 SG_ StatusCPDData4FBD_HL_CIRData83 : 216|8@1+ (1.0,0) [0|255] "" IPB_App1
 SG_ StatusCPDData4FBD_HL_CIRData84 : 224|8@1+ (1.0,0) [0|255] "" IPB_App1
 SG_ StatusCPDData4FBD_HL_CIRData85 : 232|8@1+ (1.0,0) [0|255] "" IPB_App1
 SG_ StatusCPDData4FBD_HL_CIRData86 : 240|8@1+ (1.0,0) [0|255] "" IPB_App1
 SG_ StatusCPDData4FBD_HL_CIRData87 : 248|8@1+ (1.0,0) [0|255] "" IPB_App1
 SG_ StatusCPDData4FBD_HL_CIRData88 : 256|8@1+ (1.0,0) [0|255] "" IPB_App1
 SG_ StatusCPDData4FBD_HL_CIRData89 : 264|8@1+ (1.0,0) [0|255] "" IPB_App1
 SG_ StatusCPDData4FBD_HL_CIRData90 : 272|8@1+ (1.0,0) [0|255] "" IPB_App1
 SG_ StatusCPDData4FBD_HL_CIRData91 : 280|8@1+ (1.0,0) [0|255] "" IPB_App1
 SG_ StatusCPDData4FBD_HL_CIRData92 : 288|8@1+ (1.0,0) [0|255] "" IPB_App1
 SG_ StatusCPDData4FBD_HL_CIRData93 : 296|8@1+ (1.0,0) [0|255] "" IPB_App1
 SG_ StatusCPDData4FBD_HL_CIRData94 : 304|8@1+ (1.0,0) [0|255] "" IPB_App1
 SG_ StatusCPDData4FBD_HL_CIRData95 : 312|8@1+ (1.0,0) [0|255] "" IPB_App1
 SG_ StatusCPDData4FBD_HL_CIRData96 : 320|8@1+ (1.0,0) [0|255] "" IPB_App1
 SG_ StatusCPDData4FBD_HL_CIRData97 : 328|8@1+ (1.0,0) [0|255] "" IPB_App1
 SG_ StatusCPDData4FBD_HL_CIRData98 : 336|8@1+ (1.0,0) [0|255] "" IPB_App1
 SG_ StatusCPDData4FBD_HL_CIRData99 : 344|8@1+ (1.0,0) [0|255] "" IPB_App1
 SG_ StatusCPDData4FBD_HL_CIRData100 : 352|8@1+ (1.0,0) [0|255] "" IPB_App1
 SG_ StatusCPDData4FBD_HL_CIRData101 : 360|8@1+ (1.0,0) [0|255] "" IPB_App1
 SG_ StatusCPDData4FBD_HL_CIRData102 : 368|8@1+ (1.0,0) [0|255] "" IPB_App1
 SG_ StatusCPDData4FBD_HL_CIRData103 : 376|8@1+ (1.0,0) [0|255] "" IPB_App1
 SG_ StatusCPDData4FBD_HL_CIRData104 : 384|8@1+ (1.0,0) [0|255] "" IPB_App1
 SG_ StatusCPDData4FBD_HL_CIRData105 : 392|8@1+ (1.0,0) [0|255] "" IPB_App1
 SG_ StatusCPDData4FBD_HL_CIRData106 : 400|8@1+ (1.0,0) [0|255] "" IPB_App1
 SG_ StatusCPDData4FBD_HL_CIRData107 : 408|8@1+ (1.0,0) [0|255] "" IPB_App1
 SG_ StatusCPDData4FBD_HL_CIRData108 : 416|8@1+ (1.0,0) [0|255] "" IPB_App1
 SG_ StatusCPDData4FBD_HL_CIRData109 : 424|8@1+ (1.0,0) [0|255] "" IPB_App1
 SG_ StatusCPDData4FBD_HL_CIRData110 : 432|8@1+ (1.0,0) [0|255] "" IPB_App1
 SG_ StatusCPDData4FBD_HL_CIRData111 : 440|8@1+ (1.0,0) [0|255] "" IPB_App1
 SG_ StatusCPDData4FBD_HL_CIRData112 : 448|8@1+ (1.0,0) [0|255] "" IPB_App1
 SG_ StatusCPDData4FBD_HL_CIRData113 : 456|8@1+ (1.0,0) [0|255] "" IPB_App1
 SG_ StatusCPDData4FBD_HL_CIRData114 : 464|8@1+ (1.0,0) [0|255] "" IPB_App1
 SG_ StatusCPDData4FBD_HL_CIRData115 : 472|8@1+ (1.0,0) [0|255] "" IPB_App1
 SG_ StatusCPDData4FBD_HL_CIRData116 : 480|8@1+ (1.0,0) [0|255] "" IPB_App1
 SG_ StatusCPDData4FBD_HL_CIRData117 : 488|8@1+ (1.0,0) [0|255] "" IPB_App1
 SG_ StatusCPDData4FBD_HL_CIRData118 : 496|8@1+ (1.0,0) [0|255] "" IPB_App1
 SG_ StatusCPDData4FBD_HL_CIRData119 : 504|8@1+ (1.0,0) [0|255] "" IPB_App1

BO_ 361 StatusCPDData4FBD_HM: 64 FBD_HM
 SG_ StatusCPDData4FBD_HM_MsgCounter : 0|8@1+ (1.0,0) [0|252] "" IPB_App1
 SG_ StatusCPDData4FBD_HM_LinkID : 8|8@1+ (1.0,0) [0|252] "" IPB_App1
 SG_ StatusCPDData4FBD_HM_CollisionCo : 16|8@1+ (1.0,0) [0|252] "" IPB_App1
 SG_ StatusCPDData4FBD_HM_CIRSetting : 24|8@1+ (1,0) [0|0] "" IPB_App1
 SG_ StatusCPDData4FBD_HM_CIRData60 : 32|8@1+ (1.0,0) [0|255] "" IPB_App1
 SG_ StatusCPDData4FBD_HM_CIRData61 : 40|8@1+ (1.0,0) [0|255] "" IPB_App1
 SG_ StatusCPDData4FBD_HM_CIRData62 : 48|8@1+ (1.0,0) [0|255] "" IPB_App1
 SG_ StatusCPDData4FBD_HM_CIRData63 : 56|8@1+ (1.0,0) [0|255] "" IPB_App1
 SG_ StatusCPDData4FBD_HM_CIRData64 : 64|8@1+ (1.0,0) [0|255] "" IPB_App1
 SG_ StatusCPDData4FBD_HM_CIRData65 : 72|8@1+ (1.0,0) [0|255] "" IPB_App1
 SG_ StatusCPDData4FBD_HM_CIRData66 : 80|8@1+ (1.0,0) [0|255] "" IPB_App1
 SG_ StatusCPDData4FBD_HM_CIRData67 : 88|8@1+ (1.0,0) [0|255] "" IPB_App1
 SG_ StatusCPDData4FBD_HM_CIRData68 : 96|8@1+ (1.0,0) [0|255] "" IPB_App1
 SG_ StatusCPDData4FBD_HM_CIRData69 : 104|8@1+ (1.0,0) [0|255] "" IPB_App1
 SG_ StatusCPDData4FBD_HM_CIRData70 : 112|8@1+ (1.0,0) [0|255] "" IPB_App1
 SG_ StatusCPDData4FBD_HM_CIRData71 : 120|8@1+ (1.0,0) [0|255] "" IPB_App1
 SG_ StatusCPDData4FBD_HM_CIRData72 : 128|8@1+ (1.0,0) [0|255] "" IPB_App1
 SG_ StatusCPDData4FBD_HM_CIRData73 : 136|8@1+ (1.0,0) [0|255] "" IPB_App1
 SG_ StatusCPDData4FBD_HM_CIRData74 : 144|8@1+ (1.0,0) [0|255] "" IPB_App1
 SG_ StatusCPDData4FBD_HM_CIRData75 : 152|8@1+ (1.0,0) [0|255] "" IPB_App1
 SG_ StatusCPDData4FBD_HM_CIRData76 : 160|8@1+ (1.0,0) [0|255] "" IPB_App1
 SG_ StatusCPDData4FBD_HM_CIRData77 : 168|8@1+ (1.0,0) [0|255] "" IPB_App1
 SG_ StatusCPDData4FBD_HM_CIRData78 : 176|8@1+ (1.0,0) [0|255] "" IPB_App1
 SG_ StatusCPDData4FBD_HM_CIRData79 : 184|8@1+ (1.0,0) [0|255] "" IPB_App1
 SG_ StatusCPDData4FBD_HM_CIRData80 : 192|8@1+ (1.0,0) [0|255] "" IPB_App1
 SG_ StatusCPDData4FBD_HM_CIRData81 : 200|8@1+ (1.0,0) [0|255] "" IPB_App1
 SG_ StatusCPDData4FBD_HM_CIRData82 : 208|8@1+ (1.0,0) [0|255] "" IPB_App1
 SG_ StatusCPDData4FBD_HM_CIRData83 : 216|8@1+ (1.0,0) [0|255] "" IPB_App1
 SG_ StatusCPDData4FBD_HM_CIRData84 : 224|8@1+ (1.0,0) [0|255] "" IPB_App1
 SG_ StatusCPDData4FBD_HM_CIRData85 : 232|8@1+ (1.0,0) [0|255] "" IPB_App1
 SG_ StatusCPDData4FBD_HM_CIRData86 : 240|8@1+ (1.0,0) [0|255] "" IPB_App1
 SG_ StatusCPDData4FBD_HM_CIRData87 : 248|8@1+ (1.0,0) [0|255] "" IPB_App1
 SG_ StatusCPDData4FBD_HM_CIRData88 : 256|8@1+ (1.0,0) [0|255] "" IPB_App1
 SG_ StatusCPDData4FBD_HM_CIRData89 : 264|8@1+ (1.0,0) [0|255] "" IPB_App1
 SG_ StatusCPDData4FBD_HM_CIRData90 : 272|8@1+ (1.0,0) [0|255] "" IPB_App1
 SG_ StatusCPDData4FBD_HM_CIRData91 : 280|8@1+ (1.0,0) [0|255] "" IPB_App1
 SG_ StatusCPDData4FBD_HM_CIRData92 : 288|8@1+ (1.0,0) [0|255] "" IPB_App1
 SG_ StatusCPDData4FBD_HM_CIRData93 : 296|8@1+ (1.0,0) [0|255] "" IPB_App1
 SG_ StatusCPDData4FBD_HM_CIRData94 : 304|8@1+ (1.0,0) [0|255] "" IPB_App1
 SG_ StatusCPDData4FBD_HM_CIRData95 : 312|8@1+ (1.0,0) [0|255] "" IPB_App1
 SG_ StatusCPDData4FBD_HM_CIRData96 : 320|8@1+ (1.0,0) [0|255] "" IPB_App1
 SG_ StatusCPDData4FBD_HM_CIRData97 : 328|8@1+ (1.0,0) [0|255] "" IPB_App1
 SG_ StatusCPDData4FBD_HM_CIRData98 : 336|8@1+ (1.0,0) [0|255] "" IPB_App1
 SG_ StatusCPDData4FBD_HM_CIRData99 : 344|8@1+ (1.0,0) [0|255] "" IPB_App1
 SG_ StatusCPDData4FBD_HM_CIRData100 : 352|8@1+ (1.0,0) [0|255] "" IPB_App1
 SG_ StatusCPDData4FBD_HM_CIRData101 : 360|8@1+ (1.0,0) [0|255] "" IPB_App1
 SG_ StatusCPDData4FBD_HM_CIRData102 : 368|8@1+ (1.0,0) [0|255] "" IPB_App1
 SG_ StatusCPDData4FBD_HM_CIRData103 : 376|8@1+ (1.0,0) [0|255] "" IPB_App1
 SG_ StatusCPDData4FBD_HM_CIRData104 : 384|8@1+ (1.0,0) [0|255] "" IPB_App1
 SG_ StatusCPDData4FBD_HM_CIRData105 : 392|8@1+ (1.0,0) [0|255] "" IPB_App1
 SG_ StatusCPDData4FBD_HM_CIRData106 : 400|8@1+ (1.0,0) [0|255] "" IPB_App1
 SG_ StatusCPDData4FBD_HM_CIRData107 : 408|8@1+ (1.0,0) [0|255] "" IPB_App1
 SG_ StatusCPDData4FBD_HM_CIRData108 : 416|8@1+ (1.0,0) [0|255] "" IPB_App1
 SG_ StatusCPDData4FBD_HM_CIRData109 : 424|8@1+ (1.0,0) [0|255] "" IPB_App1
 SG_ StatusCPDData4FBD_HM_CIRData110 : 432|8@1+ (1.0,0) [0|255] "" IPB_App1
 SG_ StatusCPDData4FBD_HM_CIRData111 : 440|8@1+ (1.0,0) [0|255] "" IPB_App1
 SG_ StatusCPDData4FBD_HM_CIRData112 : 448|8@1+ (1.0,0) [0|255] "" IPB_App1
 SG_ StatusCPDData4FBD_HM_CIRData113 : 456|8@1+ (1.0,0) [0|255] "" IPB_App1
 SG_ StatusCPDData4FBD_HM_CIRData114 : 464|8@1+ (1.0,0) [0|255] "" IPB_App1
 SG_ StatusCPDData4FBD_HM_CIRData115 : 472|8@1+ (1.0,0) [0|255] "" IPB_App1
 SG_ StatusCPDData4FBD_HM_CIRData116 : 480|8@1+ (1.0,0) [0|255] "" IPB_App1
 SG_ StatusCPDData4FBD_HM_CIRData117 : 488|8@1+ (1.0,0) [0|255] "" IPB_App1
 SG_ StatusCPDData4FBD_HM_CIRData118 : 496|8@1+ (1.0,0) [0|255] "" IPB_App1
 SG_ StatusCPDData4FBD_HM_CIRData119 : 504|8@1+ (1.0,0) [0|255] "" IPB_App1

BO_ 367 StatusCPDData4FBD_HR: 64 FBD_HR
 SG_ StatusCPDData4FBD_HR_MsgCounter : 0|8@1+ (1.0,0) [0|252] "" IPB_App1
 SG_ StatusCPDData4FBD_HR_LinkID : 8|8@1+ (1.0,0) [0|252] "" IPB_App1
 SG_ StatusCPDData4FBD_HR_CollisionCo : 16|8@1+ (1.0,0) [0|252] "" IPB_App1
 SG_ StatusCPDData4FBD_HR_CIRSetting : 24|8@1+ (1,0) [0|0] "" IPB_App1
 SG_ StatusCPDData4FBD_HR_CIRData60 : 32|8@1+ (1.0,0) [0|255] "" IPB_App1
 SG_ StatusCPDData4FBD_HR_CIRData61 : 40|8@1+ (1.0,0) [0|255] "" IPB_App1
 SG_ StatusCPDData4FBD_HR_CIRData62 : 48|8@1+ (1.0,0) [0|255] "" IPB_App1
 SG_ StatusCPDData4FBD_HR_CIRData63 : 56|8@1+ (1.0,0) [0|255] "" IPB_App1
 SG_ StatusCPDData4FBD_HR_CIRData64 : 64|8@1+ (1.0,0) [0|255] "" IPB_App1
 SG_ StatusCPDData4FBD_HR_CIRData65 : 72|8@1+ (1.0,0) [0|255] "" IPB_App1
 SG_ StatusCPDData4FBD_HR_CIRData66 : 80|8@1+ (1.0,0) [0|255] "" IPB_App1
 SG_ StatusCPDData4FBD_HR_CIRData67 : 88|8@1+ (1.0,0) [0|255] "" IPB_App1
 SG_ StatusCPDData4FBD_HR_CIRData68 : 96|8@1+ (1.0,0) [0|255] "" IPB_App1
 SG_ StatusCPDData4FBD_HR_CIRData69 : 104|8@1+ (1.0,0) [0|255] "" IPB_App1
 SG_ StatusCPDData4FBD_HR_CIRData70 : 112|8@1+ (1.0,0) [0|255] "" IPB_App1
 SG_ StatusCPDData4FBD_HR_CIRData71 : 120|8@1+ (1.0,0) [0|255] "" IPB_App1
 SG_ StatusCPDData4FBD_HR_CIRData72 : 128|8@1+ (1.0,0) [0|255] "" IPB_App1
 SG_ StatusCPDData4FBD_HR_CIRData73 : 136|8@1+ (1.0,0) [0|255] "" IPB_App1
 SG_ StatusCPDData4FBD_HR_CIRData74 : 144|8@1+ (1.0,0) [0|255] "" IPB_App1
 SG_ StatusCPDData4FBD_HR_CIRData75 : 152|8@1+ (1.0,0) [0|255] "" IPB_App1
 SG_ StatusCPDData4FBD_HR_CIRData76 : 160|8@1+ (1.0,0) [0|255] "" IPB_App1
 SG_ StatusCPDData4FBD_HR_CIRData77 : 168|8@1+ (1.0,0) [0|255] "" IPB_App1
 SG_ StatusCPDData4FBD_HR_CIRData78 : 176|8@1+ (1.0,0) [0|255] "" IPB_App1
 SG_ StatusCPDData4FBD_HR_CIRData79 : 184|8@1+ (1.0,0) [0|255] "" IPB_App1
 SG_ StatusCPDData4FBD_HR_CIRData80 : 192|8@1+ (1.0,0) [0|255] "" IPB_App1
 SG_ StatusCPDData4FBD_HR_CIRData81 : 200|8@1+ (1.0,0) [0|255] "" IPB_App1
 SG_ StatusCPDData4FBD_HR_CIRData82 : 208|8@1+ (1.0,0) [0|255] "" IPB_App1
 SG_ StatusCPDData4FBD_HR_CIRData83 : 216|8@1+ (1.0,0) [0|255] "" IPB_App1
 SG_ StatusCPDData4FBD_HR_CIRData84 : 224|8@1+ (1.0,0) [0|255] "" IPB_App1
 SG_ StatusCPDData4FBD_HR_CIRData85 : 232|8@1+ (1.0,0) [0|255] "" IPB_App1
 SG_ StatusCPDData4FBD_HR_CIRData86 : 240|8@1+ (1.0,0) [0|255] "" IPB_App1
 SG_ StatusCPDData4FBD_HR_CIRData87 : 248|8@1+ (1.0,0) [0|255] "" IPB_App1
 SG_ StatusCPDData4FBD_HR_CIRData88 : 256|8@1+ (1.0,0) [0|255] "" IPB_App1
 SG_ StatusCPDData4FBD_HR_CIRData89 : 264|8@1+ (1.0,0) [0|255] "" IPB_App1
 SG_ StatusCPDData4FBD_HR_CIRData90 : 272|8@1+ (1.0,0) [0|255] "" IPB_App1
 SG_ StatusCPDData4FBD_HR_CIRData91 : 280|8@1+ (1.0,0) [0|255] "" IPB_App1
 SG_ StatusCPDData4FBD_HR_CIRData92 : 288|8@1+ (1.0,0) [0|255] "" IPB_App1
 SG_ StatusCPDData4FBD_HR_CIRData93 : 296|8@1+ (1.0,0) [0|255] "" IPB_App1
 SG_ StatusCPDData4FBD_HR_CIRData94 : 304|8@1+ (1.0,0) [0|255] "" IPB_App1
 SG_ StatusCPDData4FBD_HR_CIRData95 : 312|8@1+ (1.0,0) [0|255] "" IPB_App1
 SG_ StatusCPDData4FBD_HR_CIRData96 : 320|8@1+ (1.0,0) [0|255] "" IPB_App1
 SG_ StatusCPDData4FBD_HR_CIRData97 : 328|8@1+ (1.0,0) [0|255] "" IPB_App1
 SG_ StatusCPDData4FBD_HR_CIRData98 : 336|8@1+ (1.0,0) [0|255] "" IPB_App1
 SG_ StatusCPDData4FBD_HR_CIRData99 : 344|8@1+ (1.0,0) [0|255] "" IPB_App1
 SG_ StatusCPDData4FBD_HR_CIRData100 : 352|8@1+ (1.0,0) [0|255] "" IPB_App1
 SG_ StatusCPDData4FBD_HR_CIRData101 : 360|8@1+ (1.0,0) [0|255] "" IPB_App1
 SG_ StatusCPDData4FBD_HR_CIRData102 : 368|8@1+ (1.0,0) [0|255] "" IPB_App1
 SG_ StatusCPDData4FBD_HR_CIRData103 : 376|8@1+ (1.0,0) [0|255] "" IPB_App1
 SG_ StatusCPDData4FBD_HR_CIRData104 : 384|8@1+ (1.0,0) [0|255] "" IPB_App1
 SG_ StatusCPDData4FBD_HR_CIRData105 : 392|8@1+ (1.0,0) [0|255] "" IPB_App1
 SG_ StatusCPDData4FBD_HR_CIRData106 : 400|8@1+ (1.0,0) [0|255] "" IPB_App1
 SG_ StatusCPDData4FBD_HR_CIRData107 : 408|8@1+ (1.0,0) [0|255] "" IPB_App1
 SG_ StatusCPDData4FBD_HR_CIRData108 : 416|8@1+ (1.0,0) [0|255] "" IPB_App1
 SG_ StatusCPDData4FBD_HR_CIRData109 : 424|8@1+ (1.0,0) [0|255] "" IPB_App1
 SG_ StatusCPDData4FBD_HR_CIRData110 : 432|8@1+ (1.0,0) [0|255] "" IPB_App1
 SG_ StatusCPDData4FBD_HR_CIRData111 : 440|8@1+ (1.0,0) [0|255] "" IPB_App1
 SG_ StatusCPDData4FBD_HR_CIRData112 : 448|8@1+ (1.0,0) [0|255] "" IPB_App1
 SG_ StatusCPDData4FBD_HR_CIRData113 : 456|8@1+ (1.0,0) [0|255] "" IPB_App1
 SG_ StatusCPDData4FBD_HR_CIRData114 : 464|8@1+ (1.0,0) [0|255] "" IPB_App1
 SG_ StatusCPDData4FBD_HR_CIRData115 : 472|8@1+ (1.0,0) [0|255] "" IPB_App1
 SG_ StatusCPDData4FBD_HR_CIRData116 : 480|8@1+ (1.0,0) [0|255] "" IPB_App1
 SG_ StatusCPDData4FBD_HR_CIRData117 : 488|8@1+ (1.0,0) [0|255] "" IPB_App1
 SG_ StatusCPDData4FBD_HR_CIRData118 : 496|8@1+ (1.0,0) [0|255] "" IPB_App1
 SG_ StatusCPDData4FBD_HR_CIRData119 : 504|8@1+ (1.0,0) [0|255] "" IPB_App1

BO_ 362 StatusCPDData4FBD_Miko: 64 FBD_Miko
 SG_ StatusCPDData4FBD_Miko_MsgCounte : 0|8@1+ (1.0,0) [0|252] "" IPB_App1
 SG_ StatusCPDData4FBD_Miko_LinkID : 8|8@1+ (1.0,0) [0|252] "" IPB_App1
 SG_ StatusCPDData4FBD_Miko_Collision : 16|8@1+ (1.0,0) [0|252] "" IPB_App1
 SG_ StatusCPDData4FBD_Miko_CIRSettin : 24|8@1+ (1,0) [0|0] "" IPB_App1
 SG_ StatusCPDData4FBD_Miko_CIRData60 : 32|8@1+ (1.0,0) [0|255] "" IPB_App1
 SG_ StatusCPDData4FBD_Miko_CIRData61 : 40|8@1+ (1.0,0) [0|255] "" IPB_App1
 SG_ StatusCPDData4FBD_Miko_CIRData62 : 48|8@1+ (1.0,0) [0|255] "" IPB_App1
 SG_ StatusCPDData4FBD_Miko_CIRData63 : 56|8@1+ (1.0,0) [0|255] "" IPB_App1
 SG_ StatusCPDData4FBD_Miko_CIRData64 : 64|8@1+ (1.0,0) [0|255] "" IPB_App1
 SG_ StatusCPDData4FBD_Miko_CIRData65 : 72|8@1+ (1.0,0) [0|255] "" IPB_App1
 SG_ StatusCPDData4FBD_Miko_CIRData66 : 80|8@1+ (1.0,0) [0|255] "" IPB_App1
 SG_ StatusCPDData4FBD_Miko_CIRData67 : 88|8@1+ (1.0,0) [0|255] "" IPB_App1
 SG_ StatusCPDData4FBD_Miko_CIRData68 : 96|8@1+ (1.0,0) [0|255] "" IPB_App1
 SG_ StatusCPDData4FBD_Miko_CIRData69 : 104|8@1+ (1.0,0) [0|255] "" IPB_App1
 SG_ StatusCPDData4FBD_Miko_CIRData70 : 112|8@1+ (1.0,0) [0|255] "" IPB_App1
 SG_ StatusCPDData4FBD_Miko_CIRData71 : 120|8@1+ (1.0,0) [0|255] "" IPB_App1
 SG_ StatusCPDData4FBD_Miko_CIRData72 : 128|8@1+ (1.0,0) [0|255] "" IPB_App1
 SG_ StatusCPDData4FBD_Miko_CIRData73 : 136|8@1+ (1.0,0) [0|255] "" IPB_App1
 SG_ StatusCPDData4FBD_Miko_CIRData74 : 144|8@1+ (1.0,0) [0|255] "" IPB_App1
 SG_ StatusCPDData4FBD_Miko_CIRData75 : 152|8@1+ (1.0,0) [0|255] "" IPB_App1
 SG_ StatusCPDData4FBD_Miko_CIRData76 : 160|8@1+ (1.0,0) [0|255] "" IPB_App1
 SG_ StatusCPDData4FBD_Miko_CIRData77 : 168|8@1+ (1.0,0) [0|255] "" IPB_App1
 SG_ StatusCPDData4FBD_Miko_CIRData78 : 176|8@1+ (1.0,0) [0|255] "" IPB_App1
 SG_ StatusCPDData4FBD_Miko_CIRData79 : 184|8@1+ (1.0,0) [0|255] "" IPB_App1
 SG_ StatusCPDData4FBD_Miko_CIRData80 : 192|8@1+ (1.0,0) [0|255] "" IPB_App1
 SG_ StatusCPDData4FBD_Miko_CIRData81 : 200|8@1+ (1.0,0) [0|255] "" IPB_App1
 SG_ StatusCPDData4FBD_Miko_CIRData82 : 208|8@1+ (1.0,0) [0|255] "" IPB_App1
 SG_ StatusCPDData4FBD_Miko_CIRData83 : 216|8@1+ (1.0,0) [0|255] "" IPB_App1
 SG_ StatusCPDData4FBD_Miko_CIRData84 : 224|8@1+ (1.0,0) [0|255] "" IPB_App1
 SG_ StatusCPDData4FBD_Miko_CIRData85 : 232|8@1+ (1.0,0) [0|255] "" IPB_App1
 SG_ StatusCPDData4FBD_Miko_CIRData86 : 240|8@1+ (1.0,0) [0|255] "" IPB_App1
 SG_ StatusCPDData4FBD_Miko_CIRData87 : 248|8@1+ (1.0,0) [0|255] "" IPB_App1
 SG_ StatusCPDData4FBD_Miko_CIRData88 : 256|8@1+ (1.0,0) [0|255] "" IPB_App1
 SG_ StatusCPDData4FBD_Miko_CIRData89 : 264|8@1+ (1.0,0) [0|255] "" IPB_App1
 SG_ StatusCPDData4FBD_Miko_CIRData90 : 272|8@1+ (1.0,0) [0|255] "" IPB_App1
 SG_ StatusCPDData4FBD_Miko_CIRData91 : 280|8@1+ (1.0,0) [0|255] "" IPB_App1
 SG_ StatusCPDData4FBD_Miko_CIRData92 : 288|8@1+ (1.0,0) [0|255] "" IPB_App1
 SG_ StatusCPDData4FBD_Miko_CIRData93 : 296|8@1+ (1.0,0) [0|255] "" IPB_App1
 SG_ StatusCPDData4FBD_Miko_CIRData94 : 304|8@1+ (1.0,0) [0|255] "" IPB_App1
 SG_ StatusCPDData4FBD_Miko_CIRData95 : 312|8@1+ (1.0,0) [0|255] "" IPB_App1
 SG_ StatusCPDData4FBD_Miko_CIRData96 : 320|8@1+ (1.0,0) [0|255] "" IPB_App1
 SG_ StatusCPDData4FBD_Miko_CIRData97 : 328|8@1+ (1.0,0) [0|255] "" IPB_App1
 SG_ StatusCPDData4FBD_Miko_CIRData98 : 336|8@1+ (1.0,0) [0|255] "" IPB_App1
 SG_ StatusCPDData4FBD_Miko_CIRData99 : 344|8@1+ (1.0,0) [0|255] "" IPB_App1
 SG_ StatusCPDData4FBD_Miko_CIRData10 : 352|8@1+ (1.0,0) [0|255] "" IPB_App1
 SG_ StatusCPDData4FBD_Miko_CIRData_2 : 360|8@1+ (1.0,0) [0|255] "" IPB_App1
 SG_ StatusCPDData4FBD_Miko_CIRData_3 : 368|8@1+ (1.0,0) [0|255] "" IPB_App1
 SG_ StatusCPDData4FBD_Miko_CIRData_4 : 376|8@1+ (1.0,0) [0|255] "" IPB_App1
 SG_ StatusCPDData4FBD_Miko_CIRData_5 : 384|8@1+ (1.0,0) [0|255] "" IPB_App1
 SG_ StatusCPDData4FBD_Miko_CIRData_6 : 392|8@1+ (1.0,0) [0|255] "" IPB_App1
 SG_ StatusCPDData4FBD_Miko_CIRData_7 : 400|8@1+ (1.0,0) [0|255] "" IPB_App1
 SG_ StatusCPDData4FBD_Miko_CIRData_8 : 408|8@1+ (1.0,0) [0|255] "" IPB_App1
 SG_ StatusCPDData4FBD_Miko_CIRData_9 : 416|8@1+ (1.0,0) [0|255] "" IPB_App1
 SG_ StatusCPDData4FBD_Miko_CIRDat_10 : 424|8@1+ (1.0,0) [0|255] "" IPB_App1
 SG_ StatusCPDData4FBD_Miko_CIRData11 : 432|8@1+ (1.0,0) [0|255] "" IPB_App1
 SG_ StatusCPDData4FBD_Miko_CIRDat_11 : 440|8@1+ (1.0,0) [0|255] "" IPB_App1
 SG_ StatusCPDData4FBD_Miko_CIRDat_12 : 448|8@1+ (1.0,0) [0|255] "" IPB_App1
 SG_ StatusCPDData4FBD_Miko_CIRDat_13 : 456|8@1+ (1.0,0) [0|255] "" IPB_App1
 SG_ StatusCPDData4FBD_Miko_CIRDat_14 : 464|8@1+ (1.0,0) [0|255] "" IPB_App1
 SG_ StatusCPDData4FBD_Miko_CIRDat_15 : 472|8@1+ (1.0,0) [0|255] "" IPB_App1
 SG_ StatusCPDData4FBD_Miko_CIRDat_16 : 480|8@1+ (1.0,0) [0|255] "" IPB_App1
 SG_ StatusCPDData4FBD_Miko_CIRDat_17 : 488|8@1+ (1.0,0) [0|255] "" IPB_App1
 SG_ StatusCPDData4FBD_Miko_CIRDat_18 : 496|8@1+ (1.0,0) [0|255] "" IPB_App1
 SG_ StatusCPDData4FBD_Miko_CIRDat_19 : 504|8@1+ (1.0,0) [0|255] "" IPB_App1

BO_ 836 StatusCPDData4FBD_MM: 64 FBD_MM
 SG_ StatusCPDData4FBD_MM_MsgCounter : 0|8@1+ (1.0,0) [0|252] "" IPB_App1
 SG_ StatusCPDData4FBD_MM_LinkID : 8|8@1+ (1.0,0) [0|252] "" IPB_App1
 SG_ StatusCPDData4FBD_MM_CollisionCo : 16|8@1+ (1.0,0) [0|252] "" IPB_App1
 SG_ StatusCPDData4FBD_MM_CIRSetting : 24|8@1+ (1,0) [0|0] "" IPB_App1
 SG_ StatusCPDData4FBD_MM_CIRData60 : 32|8@1+ (1.0,0) [0|255] "" IPB_App1
 SG_ StatusCPDData4FBD_MM_CIRData61 : 40|8@1+ (1.0,0) [0|255] "" IPB_App1
 SG_ StatusCPDData4FBD_MM_CIRData62 : 48|8@1+ (1.0,0) [0|255] "" IPB_App1
 SG_ StatusCPDData4FBD_MM_CIRData63 : 56|8@1+ (1.0,0) [0|255] "" IPB_App1
 SG_ StatusCPDData4FBD_MM_CIRData64 : 64|8@1+ (1.0,0) [0|255] "" IPB_App1
 SG_ StatusCPDData4FBD_MM_CIRData65 : 72|8@1+ (1.0,0) [0|255] "" IPB_App1
 SG_ StatusCPDData4FBD_MM_CIRData66 : 80|8@1+ (1.0,0) [0|255] "" IPB_App1
 SG_ StatusCPDData4FBD_MM_CIRData67 : 88|8@1+ (1.0,0) [0|255] "" IPB_App1
 SG_ StatusCPDData4FBD_MM_CIRData68 : 96|8@1+ (1.0,0) [0|255] "" IPB_App1
 SG_ StatusCPDData4FBD_MM_CIRData69 : 104|8@1+ (1.0,0) [0|255] "" IPB_App1
 SG_ StatusCPDData4FBD_MM_CIRData70 : 112|8@1+ (1.0,0) [0|255] "" IPB_App1
 SG_ StatusCPDData4FBD_MM_CIRData71 : 120|8@1+ (1.0,0) [0|255] "" IPB_App1
 SG_ StatusCPDData4FBD_MM_CIRData72 : 128|8@1+ (1.0,0) [0|255] "" IPB_App1
 SG_ StatusCPDData4FBD_MM_CIRData73 : 136|8@1+ (1.0,0) [0|255] "" IPB_App1
 SG_ StatusCPDData4FBD_MM_CIRData74 : 144|8@1+ (1.0,0) [0|255] "" IPB_App1
 SG_ StatusCPDData4FBD_MM_CIRData75 : 152|8@1+ (1.0,0) [0|255] "" IPB_App1
 SG_ StatusCPDData4FBD_MM_CIRData76 : 160|8@1+ (1.0,0) [0|255] "" IPB_App1
 SG_ StatusCPDData4FBD_MM_CIRData77 : 168|8@1+ (1.0,0) [0|255] "" IPB_App1
 SG_ StatusCPDData4FBD_MM_CIRData78 : 176|8@1+ (1.0,0) [0|255] "" IPB_App1
 SG_ StatusCPDData4FBD_MM_CIRData79 : 184|8@1+ (1.0,0) [0|255] "" IPB_App1
 SG_ StatusCPDData4FBD_MM_CIRData80 : 192|8@1+ (1.0,0) [0|255] "" IPB_App1
 SG_ StatusCPDData4FBD_MM_CIRData81 : 200|8@1+ (1.0,0) [0|255] "" IPB_App1
 SG_ StatusCPDData4FBD_MM_CIRData82 : 208|8@1+ (1.0,0) [0|255] "" IPB_App1
 SG_ StatusCPDData4FBD_MM_CIRData83 : 216|8@1+ (1.0,0) [0|255] "" IPB_App1
 SG_ StatusCPDData4FBD_MM_CIRData84 : 224|8@1+ (1.0,0) [0|255] "" IPB_App1
 SG_ StatusCPDData4FBD_MM_CIRData85 : 232|8@1+ (1.0,0) [0|255] "" IPB_App1
 SG_ StatusCPDData4FBD_MM_CIRData86 : 240|8@1+ (1.0,0) [0|255] "" IPB_App1
 SG_ StatusCPDData4FBD_MM_CIRData87 : 248|8@1+ (1.0,0) [0|255] "" IPB_App1
 SG_ StatusCPDData4FBD_MM_CIRData88 : 256|8@1+ (1.0,0) [0|255] "" IPB_App1
 SG_ StatusCPDData4FBD_MM_CIRData89 : 264|8@1+ (1.0,0) [0|255] "" IPB_App1
 SG_ StatusCPDData4FBD_MM_CIRData90 : 272|8@1+ (1.0,0) [0|255] "" IPB_App1
 SG_ StatusCPDData4FBD_MM_CIRData91 : 280|8@1+ (1.0,0) [0|255] "" IPB_App1
 SG_ StatusCPDData4FBD_MM_CIRData92 : 288|8@1+ (1.0,0) [0|255] "" IPB_App1
 SG_ StatusCPDData4FBD_MM_CIRData93 : 296|8@1+ (1.0,0) [0|255] "" IPB_App1
 SG_ StatusCPDData4FBD_MM_CIRData94 : 304|8@1+ (1.0,0) [0|255] "" IPB_App1
 SG_ StatusCPDData4FBD_MM_CIRData95 : 312|8@1+ (1.0,0) [0|255] "" IPB_App1
 SG_ StatusCPDData4FBD_MM_CIRData96 : 320|8@1+ (1.0,0) [0|255] "" IPB_App1
 SG_ StatusCPDData4FBD_MM_CIRData97 : 328|8@1+ (1.0,0) [0|255] "" IPB_App1
 SG_ StatusCPDData4FBD_MM_CIRData98 : 336|8@1+ (1.0,0) [0|255] "" IPB_App1
 SG_ StatusCPDData4FBD_MM_CIRData99 : 344|8@1+ (1.0,0) [0|255] "" IPB_App1
 SG_ StatusCPDData4FBD_MM_CIRData100 : 352|8@1+ (1.0,0) [0|255] "" IPB_App1
 SG_ StatusCPDData4FBD_MM_CIRData101 : 360|8@1+ (1.0,0) [0|255] "" IPB_App1
 SG_ StatusCPDData4FBD_MM_CIRData102 : 368|8@1+ (1.0,0) [0|255] "" IPB_App1
 SG_ StatusCPDData4FBD_MM_CIRData103 : 376|8@1+ (1.0,0) [0|255] "" IPB_App1
 SG_ StatusCPDData4FBD_MM_CIRData104 : 384|8@1+ (1.0,0) [0|255] "" IPB_App1
 SG_ StatusCPDData4FBD_MM_CIRData105 : 392|8@1+ (1.0,0) [0|255] "" IPB_App1
 SG_ StatusCPDData4FBD_MM_CIRData106 : 400|8@1+ (1.0,0) [0|255] "" IPB_App1
 SG_ StatusCPDData4FBD_MM_CIRData107 : 408|8@1+ (1.0,0) [0|255] "" IPB_App1
 SG_ StatusCPDData4FBD_MM_CIRData108 : 416|8@1+ (1.0,0) [0|255] "" IPB_App1
 SG_ StatusCPDData4FBD_MM_CIRData109 : 424|8@1+ (1.0,0) [0|255] "" IPB_App1
 SG_ StatusCPDData4FBD_MM_CIRData110 : 432|8@1+ (1.0,0) [0|255] "" IPB_App1
 SG_ StatusCPDData4FBD_MM_CIRData111 : 440|8@1+ (1.0,0) [0|255] "" IPB_App1
 SG_ StatusCPDData4FBD_MM_CIRData112 : 448|8@1+ (1.0,0) [0|255] "" IPB_App1
 SG_ StatusCPDData4FBD_MM_CIRData113 : 456|8@1+ (1.0,0) [0|255] "" IPB_App1
 SG_ StatusCPDData4FBD_MM_CIRData114 : 464|8@1+ (1.0,0) [0|255] "" IPB_App1
 SG_ StatusCPDData4FBD_MM_CIRData115 : 472|8@1+ (1.0,0) [0|255] "" IPB_App1
 SG_ StatusCPDData4FBD_MM_CIRData116 : 480|8@1+ (1.0,0) [0|255] "" IPB_App1
 SG_ StatusCPDData4FBD_MM_CIRData117 : 488|8@1+ (1.0,0) [0|255] "" IPB_App1
 SG_ StatusCPDData4FBD_MM_CIRData118 : 496|8@1+ (1.0,0) [0|255] "" IPB_App1
 SG_ StatusCPDData4FBD_MM_CIRData119 : 504|8@1+ (1.0,0) [0|255] "" IPB_App1

BO_ 363 StatusCPDData4FBD_Trunk: 64 FBD_Trunk
 SG_ StatusCPDData4FBD_Trunk_MsgCount : 0|8@1+ (1.0,0) [0|252] "" IPB_App1
 SG_ StatusCPDData4FBD_Trunk_LinkID : 8|8@1+ (1.0,0) [0|252] "" IPB_App1
 SG_ StatusCPDData4FBD_Trunk_Collisio : 16|8@1+ (1.0,0) [0|252] "" IPB_App1
 SG_ StatusCPDData4FBD_Trunk_CIRSetti : 24|8@1+ (1,0) [0|0] "" IPB_App1
 SG_ StatusCPDData4FBD_Trunk_CIRData6 : 32|8@1+ (1.0,0) [0|255] "" IPB_App1
 SG_ StatusCPDData4FBD_Trunk_CIRDat_2 : 40|8@1+ (1.0,0) [0|255] "" IPB_App1
 SG_ StatusCPDData4FBD_Trunk_CIRDat_3 : 48|8@1+ (1.0,0) [0|255] "" IPB_App1
 SG_ StatusCPDData4FBD_Trunk_CIRDat_4 : 56|8@1+ (1.0,0) [0|255] "" IPB_App1
 SG_ StatusCPDData4FBD_Trunk_CIRDat_5 : 64|8@1+ (1.0,0) [0|255] "" IPB_App1
 SG_ StatusCPDData4FBD_Trunk_CIRDat_6 : 72|8@1+ (1.0,0) [0|255] "" IPB_App1
 SG_ StatusCPDData4FBD_Trunk_CIRDat_7 : 80|8@1+ (1.0,0) [0|255] "" IPB_App1
 SG_ StatusCPDData4FBD_Trunk_CIRDat_8 : 88|8@1+ (1.0,0) [0|255] "" IPB_App1
 SG_ StatusCPDData4FBD_Trunk_CIRDat_9 : 96|8@1+ (1.0,0) [0|255] "" IPB_App1
 SG_ StatusCPDData4FBD_Trunk_CIRDa_10 : 104|8@1+ (1.0,0) [0|255] "" IPB_App1
 SG_ StatusCPDData4FBD_Trunk_CIRData7 : 112|8@1+ (1.0,0) [0|255] "" IPB_App1
 SG_ StatusCPDData4FBD_Trunk_CIRDa_11 : 120|8@1+ (1.0,0) [0|255] "" IPB_App1
 SG_ StatusCPDData4FBD_Trunk_CIRDa_12 : 128|8@1+ (1.0,0) [0|255] "" IPB_App1
 SG_ StatusCPDData4FBD_Trunk_CIRDa_13 : 136|8@1+ (1.0,0) [0|255] "" IPB_App1
 SG_ StatusCPDData4FBD_Trunk_CIRDa_14 : 144|8@1+ (1.0,0) [0|255] "" IPB_App1
 SG_ StatusCPDData4FBD_Trunk_CIRDa_15 : 152|8@1+ (1.0,0) [0|255] "" IPB_App1
 SG_ StatusCPDData4FBD_Trunk_CIRDa_16 : 160|8@1+ (1.0,0) [0|255] "" IPB_App1
 SG_ StatusCPDData4FBD_Trunk_CIRDa_17 : 168|8@1+ (1.0,0) [0|255] "" IPB_App1
 SG_ StatusCPDData4FBD_Trunk_CIRDa_18 : 176|8@1+ (1.0,0) [0|255] "" IPB_App1
 SG_ StatusCPDData4FBD_Trunk_CIRDa_19 : 184|8@1+ (1.0,0) [0|255] "" IPB_App1
 SG_ StatusCPDData4FBD_Trunk_CIRData8 : 192|8@1+ (1.0,0) [0|255] "" IPB_App1
 SG_ StatusCPDData4FBD_Trunk_CIRDa_20 : 200|8@1+ (1.0,0) [0|255] "" IPB_App1
 SG_ StatusCPDData4FBD_Trunk_CIRDa_21 : 208|8@1+ (1.0,0) [0|255] "" IPB_App1
 SG_ StatusCPDData4FBD_Trunk_CIRDa_22 : 216|8@1+ (1.0,0) [0|255] "" IPB_App1
 SG_ StatusCPDData4FBD_Trunk_CIRDa_23 : 224|8@1+ (1.0,0) [0|255] "" IPB_App1
 SG_ StatusCPDData4FBD_Trunk_CIRDa_24 : 232|8@1+ (1.0,0) [0|255] "" IPB_App1
 SG_ StatusCPDData4FBD_Trunk_CIRDa_25 : 240|8@1+ (1.0,0) [0|255] "" IPB_App1
 SG_ StatusCPDData4FBD_Trunk_CIRDa_26 : 248|8@1+ (1.0,0) [0|255] "" IPB_App1
 SG_ StatusCPDData4FBD_Trunk_CIRDa_27 : 256|8@1+ (1.0,0) [0|255] "" IPB_App1
 SG_ StatusCPDData4FBD_Trunk_CIRDa_28 : 264|8@1+ (1.0,0) [0|255] "" IPB_App1
 SG_ StatusCPDData4FBD_Trunk_CIRData9 : 272|8@1+ (1.0,0) [0|255] "" IPB_App1
 SG_ StatusCPDData4FBD_Trunk_CIRDa_29 : 280|8@1+ (1.0,0) [0|255] "" IPB_App1
 SG_ StatusCPDData4FBD_Trunk_CIRDa_30 : 288|8@1+ (1.0,0) [0|255] "" IPB_App1
 SG_ StatusCPDData4FBD_Trunk_CIRDa_31 : 296|8@1+ (1.0,0) [0|255] "" IPB_App1
 SG_ StatusCPDData4FBD_Trunk_CIRDa_32 : 304|8@1+ (1.0,0) [0|255] "" IPB_App1
 SG_ StatusCPDData4FBD_Trunk_CIRDa_33 : 312|8@1+ (1.0,0) [0|255] "" IPB_App1
 SG_ StatusCPDData4FBD_Trunk_CIRDa_34 : 320|8@1+ (1.0,0) [0|255] "" IPB_App1
 SG_ StatusCPDData4FBD_Trunk_CIRDa_35 : 328|8@1+ (1.0,0) [0|255] "" IPB_App1
 SG_ StatusCPDData4FBD_Trunk_CIRDa_36 : 336|8@1+ (1.0,0) [0|255] "" IPB_App1
 SG_ StatusCPDData4FBD_Trunk_CIRDa_37 : 344|8@1+ (1.0,0) [0|255] "" IPB_App1
 SG_ StatusCPDData4FBD_Trunk_CIRData1 : 352|8@1+ (1.0,0) [0|255] "" IPB_App1
 SG_ StatusCPDData4FBD_Trunk_CIRDa_38 : 360|8@1+ (1.0,0) [0|255] "" IPB_App1
 SG_ StatusCPDData4FBD_Trunk_CIRDa_39 : 368|8@1+ (1.0,0) [0|255] "" IPB_App1
 SG_ StatusCPDData4FBD_Trunk_CIRDa_40 : 376|8@1+ (1.0,0) [0|255] "" IPB_App1
 SG_ StatusCPDData4FBD_Trunk_CIRDa_41 : 384|8@1+ (1.0,0) [0|255] "" IPB_App1
 SG_ StatusCPDData4FBD_Trunk_CIRDa_42 : 392|8@1+ (1.0,0) [0|255] "" IPB_App1
 SG_ StatusCPDData4FBD_Trunk_CIRDa_43 : 400|8@1+ (1.0,0) [0|255] "" IPB_App1
 SG_ StatusCPDData4FBD_Trunk_CIRDa_44 : 408|8@1+ (1.0,0) [0|255] "" IPB_App1
 SG_ StatusCPDData4FBD_Trunk_CIRDa_45 : 416|8@1+ (1.0,0) [0|255] "" IPB_App1
 SG_ StatusCPDData4FBD_Trunk_CIRDa_46 : 424|8@1+ (1.0,0) [0|255] "" IPB_App1
 SG_ StatusCPDData4FBD_Trunk_CIRDa_47 : 432|8@1+ (1.0,0) [0|255] "" IPB_App1
 SG_ StatusCPDData4FBD_Trunk_CIRDa_48 : 440|8@1+ (1.0,0) [0|255] "" IPB_App1
 SG_ StatusCPDData4FBD_Trunk_CIRDa_49 : 448|8@1+ (1.0,0) [0|255] "" IPB_App1
 SG_ StatusCPDData4FBD_Trunk_CIRDa_50 : 456|8@1+ (1.0,0) [0|255] "" IPB_App1
 SG_ StatusCPDData4FBD_Trunk_CIRDa_51 : 464|8@1+ (1.0,0) [0|255] "" IPB_App1
 SG_ StatusCPDData4FBD_Trunk_CIRDa_52 : 472|8@1+ (1.0,0) [0|255] "" IPB_App1
 SG_ StatusCPDData4FBD_Trunk_CIRDa_53 : 480|8@1+ (1.0,0) [0|255] "" IPB_App1
 SG_ StatusCPDData4FBD_Trunk_CIRDa_54 : 488|8@1+ (1.0,0) [0|255] "" IPB_App1
 SG_ StatusCPDData4FBD_Trunk_CIRDa_55 : 496|8@1+ (1.0,0) [0|255] "" IPB_App1
 SG_ StatusCPDData4FBD_Trunk_CIRDa_56 : 504|8@1+ (1.0,0) [0|255] "" IPB_App1

BO_ 364 StatusCPDData4FBD_VL: 64 FBD_VL
 SG_ StatusCPDData4FBD_VL_MsgCounter : 0|8@1+ (1.0,0) [0|252] "" IPB_App1
 SG_ StatusCPDData4FBD_VL_LinkID : 8|8@1+ (1.0,0) [0|252] "" IPB_App1
 SG_ StatusCPDData4FBD_VL_CollisionCo : 16|8@1+ (1.0,0) [0|252] "" IPB_App1
 SG_ StatusCPDData4FBD_VL_CIRSetting : 24|8@1+ (1,0) [0|0] "" IPB_App1
 SG_ StatusCPDData4FBD_VL_CIRData60 : 32|8@1+ (1.0,0) [0|255] "" IPB_App1
 SG_ StatusCPDData4FBD_VL_CIRData61 : 40|8@1+ (1.0,0) [0|255] "" IPB_App1
 SG_ StatusCPDData4FBD_VL_CIRData62 : 48|8@1+ (1.0,0) [0|255] "" IPB_App1
 SG_ StatusCPDData4FBD_VL_CIRData63 : 56|8@1+ (1.0,0) [0|255] "" IPB_App1
 SG_ StatusCPDData4FBD_VL_CIRData64 : 64|8@1+ (1.0,0) [0|255] "" IPB_App1
 SG_ StatusCPDData4FBD_VL_CIRData65 : 72|8@1+ (1.0,0) [0|255] "" IPB_App1
 SG_ StatusCPDData4FBD_VL_CIRData66 : 80|8@1+ (1.0,0) [0|255] "" IPB_App1
 SG_ StatusCPDData4FBD_VL_CIRData67 : 88|8@1+ (1.0,0) [0|255] "" IPB_App1
 SG_ StatusCPDData4FBD_VL_CIRData68 : 96|8@1+ (1.0,0) [0|255] "" IPB_App1
 SG_ StatusCPDData4FBD_VL_CIRData69 : 104|8@1+ (1.0,0) [0|255] "" IPB_App1
 SG_ StatusCPDData4FBD_VL_CIRData70 : 112|8@1+ (1.0,0) [0|255] "" IPB_App1
 SG_ StatusCPDData4FBD_VL_CIRData71 : 120|8@1+ (1.0,0) [0|255] "" IPB_App1
 SG_ StatusCPDData4FBD_VL_CIRData72 : 128|8@1+ (1.0,0) [0|255] "" IPB_App1
 SG_ StatusCPDData4FBD_VL_CIRData73 : 136|8@1+ (1.0,0) [0|255] "" IPB_App1
 SG_ StatusCPDData4FBD_VL_CIRData74 : 144|8@1+ (1.0,0) [0|255] "" IPB_App1
 SG_ StatusCPDData4FBD_VL_CIRData75 : 152|8@1+ (1.0,0) [0|255] "" IPB_App1
 SG_ StatusCPDData4FBD_VL_CIRData76 : 160|8@1+ (1.0,0) [0|255] "" IPB_App1
 SG_ StatusCPDData4FBD_VL_CIRData77 : 168|8@1+ (1.0,0) [0|255] "" IPB_App1
 SG_ StatusCPDData4FBD_VL_CIRData78 : 176|8@1+ (1.0,0) [0|255] "" IPB_App1
 SG_ StatusCPDData4FBD_VL_CIRData79 : 184|8@1+ (1.0,0) [0|255] "" IPB_App1
 SG_ StatusCPDData4FBD_VL_CIRData80 : 192|8@1+ (1.0,0) [0|255] "" IPB_App1
 SG_ StatusCPDData4FBD_VL_CIRData81 : 200|8@1+ (1.0,0) [0|255] "" IPB_App1
 SG_ StatusCPDData4FBD_VL_CIRData82 : 208|8@1+ (1.0,0) [0|255] "" IPB_App1
 SG_ StatusCPDData4FBD_VL_CIRData83 : 216|8@1+ (1.0,0) [0|255] "" IPB_App1
 SG_ StatusCPDData4FBD_VL_CIRData84 : 224|8@1+ (1.0,0) [0|255] "" IPB_App1
 SG_ StatusCPDData4FBD_VL_CIRData85 : 232|8@1+ (1.0,0) [0|255] "" IPB_App1
 SG_ StatusCPDData4FBD_VL_CIRData86 : 240|8@1+ (1.0,0) [0|255] "" IPB_App1
 SG_ StatusCPDData4FBD_VL_CIRData87 : 248|8@1+ (1.0,0) [0|255] "" IPB_App1
 SG_ StatusCPDData4FBD_VL_CIRData88 : 256|8@1+ (1.0,0) [0|255] "" IPB_App1
 SG_ StatusCPDData4FBD_VL_CIRData89 : 264|8@1+ (1.0,0) [0|255] "" IPB_App1
 SG_ StatusCPDData4FBD_VL_CIRData90 : 272|8@1+ (1.0,0) [0|255] "" IPB_App1
 SG_ StatusCPDData4FBD_VL_CIRData91 : 280|8@1+ (1.0,0) [0|255] "" IPB_App1
 SG_ StatusCPDData4FBD_VL_CIRData92 : 288|8@1+ (1.0,0) [0|255] "" IPB_App1
 SG_ StatusCPDData4FBD_VL_CIRData93 : 296|8@1+ (1.0,0) [0|255] "" IPB_App1
 SG_ StatusCPDData4FBD_VL_CIRData94 : 304|8@1+ (1.0,0) [0|255] "" IPB_App1
 SG_ StatusCPDData4FBD_VL_CIRData95 : 312|8@1+ (1.0,0) [0|255] "" IPB_App1
 SG_ StatusCPDData4FBD_VL_CIRData96 : 320|8@1+ (1.0,0) [0|255] "" IPB_App1
 SG_ StatusCPDData4FBD_VL_CIRData97 : 328|8@1+ (1.0,0) [0|255] "" IPB_App1
 SG_ StatusCPDData4FBD_VL_CIRData98 : 336|8@1+ (1.0,0) [0|255] "" IPB_App1
 SG_ StatusCPDData4FBD_VL_CIRData99 : 344|8@1+ (1.0,0) [0|255] "" IPB_App1
 SG_ StatusCPDData4FBD_VL_CIRData100 : 352|8@1+ (1.0,0) [0|255] "" IPB_App1
 SG_ StatusCPDData4FBD_VL_CIRData101 : 360|8@1+ (1.0,0) [0|255] "" IPB_App1
 SG_ StatusCPDData4FBD_VL_CIRData102 : 368|8@1+ (1.0,0) [0|255] "" IPB_App1
 SG_ StatusCPDData4FBD_VL_CIRData103 : 376|8@1+ (1.0,0) [0|255] "" IPB_App1
 SG_ StatusCPDData4FBD_VL_CIRData104 : 384|8@1+ (1.0,0) [0|255] "" IPB_App1
 SG_ StatusCPDData4FBD_VL_CIRData105 : 392|8@1+ (1.0,0) [0|255] "" IPB_App1
 SG_ StatusCPDData4FBD_VL_CIRData106 : 400|8@1+ (1.0,0) [0|255] "" IPB_App1
 SG_ StatusCPDData4FBD_VL_CIRData107 : 408|8@1+ (1.0,0) [0|255] "" IPB_App1
 SG_ StatusCPDData4FBD_VL_CIRData108 : 416|8@1+ (1.0,0) [0|255] "" IPB_App1
 SG_ StatusCPDData4FBD_VL_CIRData109 : 424|8@1+ (1.0,0) [0|255] "" IPB_App1
 SG_ StatusCPDData4FBD_VL_CIRData110 : 432|8@1+ (1.0,0) [0|255] "" IPB_App1
 SG_ StatusCPDData4FBD_VL_CIRData111 : 440|8@1+ (1.0,0) [0|255] "" IPB_App1
 SG_ StatusCPDData4FBD_VL_CIRData112 : 448|8@1+ (1.0,0) [0|255] "" IPB_App1
 SG_ StatusCPDData4FBD_VL_CIRData113 : 456|8@1+ (1.0,0) [0|255] "" IPB_App1
 SG_ StatusCPDData4FBD_VL_CIRData114 : 464|8@1+ (1.0,0) [0|255] "" IPB_App1
 SG_ StatusCPDData4FBD_VL_CIRData115 : 472|8@1+ (1.0,0) [0|255] "" IPB_App1
 SG_ StatusCPDData4FBD_VL_CIRData116 : 480|8@1+ (1.0,0) [0|255] "" IPB_App1
 SG_ StatusCPDData4FBD_VL_CIRData117 : 488|8@1+ (1.0,0) [0|255] "" IPB_App1
 SG_ StatusCPDData4FBD_VL_CIRData118 : 496|8@1+ (1.0,0) [0|255] "" IPB_App1
 SG_ StatusCPDData4FBD_VL_CIRData119 : 504|8@1+ (1.0,0) [0|255] "" IPB_App1

BO_ 360 StatusCPDData4FBD_VM: 64 FBD_VM
 SG_ StatusCPDData4FBD_VM_MsgCounter : 0|8@1+ (1.0,0) [0|252] "" IPB_App1
 SG_ StatusCPDData4FBD_VM_LinkID : 8|8@1+ (1.0,0) [0|252] "" IPB_App1
 SG_ StatusCPDData4FBD_VM_CollisionCo : 16|8@1+ (1.0,0) [0|252] "" IPB_App1
 SG_ StatusCPDData4FBD_VM_CIRSetting : 24|8@1+ (1,0) [0|0] "" IPB_App1
 SG_ StatusCPDData4FBD_VM_CIRData60 : 32|8@1+ (1.0,0) [0|255] "" IPB_App1
 SG_ StatusCPDData4FBD_VM_CIRData61 : 40|8@1+ (1.0,0) [0|255] "" IPB_App1
 SG_ StatusCPDData4FBD_VM_CIRData62 : 48|8@1+ (1.0,0) [0|255] "" IPB_App1
 SG_ StatusCPDData4FBD_VM_CIRData63 : 56|8@1+ (1.0,0) [0|255] "" IPB_App1
 SG_ StatusCPDData4FBD_VM_CIRData64 : 64|8@1+ (1.0,0) [0|255] "" IPB_App1
 SG_ StatusCPDData4FBD_VM_CIRData65 : 72|8@1+ (1.0,0) [0|255] "" IPB_App1
 SG_ StatusCPDData4FBD_VM_CIRData66 : 80|8@1+ (1.0,0) [0|255] "" IPB_App1
 SG_ StatusCPDData4FBD_VM_CIRData67 : 88|8@1+ (1.0,0) [0|255] "" IPB_App1
 SG_ StatusCPDData4FBD_VM_CIRData68 : 96|8@1+ (1.0,0) [0|255] "" IPB_App1
 SG_ StatusCPDData4FBD_VM_CIRData69 : 104|8@1+ (1.0,0) [0|255] "" IPB_App1
 SG_ StatusCPDData4FBD_VM_CIRData70 : 112|8@1+ (1.0,0) [0|255] "" IPB_App1
 SG_ StatusCPDData4FBD_VM_CIRData71 : 120|8@1+ (1.0,0) [0|255] "" IPB_App1
 SG_ StatusCPDData4FBD_VM_CIRData72 : 128|8@1+ (1.0,0) [0|255] "" IPB_App1
 SG_ StatusCPDData4FBD_VM_CIRData73 : 136|8@1+ (1.0,0) [0|255] "" IPB_App1
 SG_ StatusCPDData4FBD_VM_CIRData74 : 144|8@1+ (1.0,0) [0|255] "" IPB_App1
 SG_ StatusCPDData4FBD_VM_CIRData75 : 152|8@1+ (1.0,0) [0|255] "" IPB_App1
 SG_ StatusCPDData4FBD_VM_CIRData76 : 160|8@1+ (1.0,0) [0|255] "" IPB_App1
 SG_ StatusCPDData4FBD_VM_CIRData77 : 168|8@1+ (1.0,0) [0|255] "" IPB_App1
 SG_ StatusCPDData4FBD_VM_CIRData78 : 176|8@1+ (1.0,0) [0|255] "" IPB_App1
 SG_ StatusCPDData4FBD_VM_CIRData79 : 184|8@1+ (1.0,0) [0|255] "" IPB_App1
 SG_ StatusCPDData4FBD_VM_CIRData80 : 192|8@1+ (1.0,0) [0|255] "" IPB_App1
 SG_ StatusCPDData4FBD_VM_CIRData81 : 200|8@1+ (1.0,0) [0|255] "" IPB_App1
 SG_ StatusCPDData4FBD_VM_CIRData82 : 208|8@1+ (1.0,0) [0|255] "" IPB_App1
 SG_ StatusCPDData4FBD_VM_CIRData83 : 216|8@1+ (1.0,0) [0|255] "" IPB_App1
 SG_ StatusCPDData4FBD_VM_CIRData84 : 224|8@1+ (1.0,0) [0|255] "" IPB_App1
 SG_ StatusCPDData4FBD_VM_CIRData85 : 232|8@1+ (1.0,0) [0|255] "" IPB_App1
 SG_ StatusCPDData4FBD_VM_CIRData86 : 240|8@1+ (1.0,0) [0|255] "" IPB_App1
 SG_ StatusCPDData4FBD_VM_CIRData87 : 248|8@1+ (1.0,0) [0|255] "" IPB_App1
 SG_ StatusCPDData4FBD_VM_CIRData88 : 256|8@1+ (1.0,0) [0|255] "" IPB_App1
 SG_ StatusCPDData4FBD_VM_CIRData89 : 264|8@1+ (1.0,0) [0|255] "" IPB_App1
 SG_ StatusCPDData4FBD_VM_CIRData90 : 272|8@1+ (1.0,0) [0|255] "" IPB_App1
 SG_ StatusCPDData4FBD_VM_CIRData91 : 280|8@1+ (1.0,0) [0|255] "" IPB_App1
 SG_ StatusCPDData4FBD_VM_CIRData92 : 288|8@1+ (1.0,0) [0|255] "" IPB_App1
 SG_ StatusCPDData4FBD_VM_CIRData93 : 296|8@1+ (1.0,0) [0|255] "" IPB_App1
 SG_ StatusCPDData4FBD_VM_CIRData94 : 304|8@1+ (1.0,0) [0|255] "" IPB_App1
 SG_ StatusCPDData4FBD_VM_CIRData95 : 312|8@1+ (1.0,0) [0|255] "" IPB_App1
 SG_ StatusCPDData4FBD_VM_CIRData96 : 320|8@1+ (1.0,0) [0|255] "" IPB_App1
 SG_ StatusCPDData4FBD_VM_CIRData97 : 328|8@1+ (1.0,0) [0|255] "" IPB_App1
 SG_ StatusCPDData4FBD_VM_CIRData98 : 336|8@1+ (1.0,0) [0|255] "" IPB_App1
 SG_ StatusCPDData4FBD_VM_CIRData99 : 344|8@1+ (1.0,0) [0|255] "" IPB_App1
 SG_ StatusCPDData4FBD_VM_CIRData100 : 352|8@1+ (1.0,0) [0|255] "" IPB_App1
 SG_ StatusCPDData4FBD_VM_CIRData101 : 360|8@1+ (1.0,0) [0|255] "" IPB_App1
 SG_ StatusCPDData4FBD_VM_CIRData102 : 368|8@1+ (1.0,0) [0|255] "" IPB_App1
 SG_ StatusCPDData4FBD_VM_CIRData103 : 376|8@1+ (1.0,0) [0|255] "" IPB_App1
 SG_ StatusCPDData4FBD_VM_CIRData104 : 384|8@1+ (1.0,0) [0|255] "" IPB_App1
 SG_ StatusCPDData4FBD_VM_CIRData105 : 392|8@1+ (1.0,0) [0|255] "" IPB_App1
 SG_ StatusCPDData4FBD_VM_CIRData106 : 400|8@1+ (1.0,0) [0|255] "" IPB_App1
 SG_ StatusCPDData4FBD_VM_CIRData107 : 408|8@1+ (1.0,0) [0|255] "" IPB_App1
 SG_ StatusCPDData4FBD_VM_CIRData108 : 416|8@1+ (1.0,0) [0|255] "" IPB_App1
 SG_ StatusCPDData4FBD_VM_CIRData109 : 424|8@1+ (1.0,0) [0|255] "" IPB_App1
 SG_ StatusCPDData4FBD_VM_CIRData110 : 432|8@1+ (1.0,0) [0|255] "" IPB_App1
 SG_ StatusCPDData4FBD_VM_CIRData111 : 440|8@1+ (1.0,0) [0|255] "" IPB_App1
 SG_ StatusCPDData4FBD_VM_CIRData112 : 448|8@1+ (1.0,0) [0|255] "" IPB_App1
 SG_ StatusCPDData4FBD_VM_CIRData113 : 456|8@1+ (1.0,0) [0|255] "" IPB_App1
 SG_ StatusCPDData4FBD_VM_CIRData114 : 464|8@1+ (1.0,0) [0|255] "" IPB_App1
 SG_ StatusCPDData4FBD_VM_CIRData115 : 472|8@1+ (1.0,0) [0|255] "" IPB_App1
 SG_ StatusCPDData4FBD_VM_CIRData116 : 480|8@1+ (1.0,0) [0|255] "" IPB_App1
 SG_ StatusCPDData4FBD_VM_CIRData117 : 488|8@1+ (1.0,0) [0|255] "" IPB_App1
 SG_ StatusCPDData4FBD_VM_CIRData118 : 496|8@1+ (1.0,0) [0|255] "" IPB_App1
 SG_ StatusCPDData4FBD_VM_CIRData119 : 504|8@1+ (1.0,0) [0|255] "" IPB_App1

BO_ 365 StatusCPDData4FBD_VR: 64 FBD_VR
 SG_ StatusCPDData4FBD_VR_MsgCounter : 0|8@1+ (1.0,0) [0|252] "" IPB_App1
 SG_ StatusCPDData4FBD_VR_LinkID : 8|8@1+ (1.0,0) [0|252] "" IPB_App1
 SG_ StatusCPDData4FBD_VR_CollisionCo : 16|8@1+ (1.0,0) [0|252] "" IPB_App1
 SG_ StatusCPDData4FBD_VR_CIRSetting : 24|8@1+ (1,0) [0|0] "" IPB_App1
 SG_ StatusCPDData4FBD_VR_CIRData60 : 32|8@1+ (1.0,0) [0|255] "" IPB_App1
 SG_ StatusCPDData4FBD_VR_CIRData61 : 40|8@1+ (1.0,0) [0|255] "" IPB_App1
 SG_ StatusCPDData4FBD_VR_CIRData62 : 48|8@1+ (1.0,0) [0|255] "" IPB_App1
 SG_ StatusCPDData4FBD_VR_CIRData63 : 56|8@1+ (1.0,0) [0|255] "" IPB_App1
 SG_ StatusCPDData4FBD_VR_CIRData64 : 64|8@1+ (1.0,0) [0|255] "" IPB_App1
 SG_ StatusCPDData4FBD_VR_CIRData65 : 72|8@1+ (1.0,0) [0|255] "" IPB_App1
 SG_ StatusCPDData4FBD_VR_CIRData66 : 80|8@1+ (1.0,0) [0|255] "" IPB_App1
 SG_ StatusCPDData4FBD_VR_CIRData67 : 88|8@1+ (1.0,0) [0|255] "" IPB_App1
 SG_ StatusCPDData4FBD_VR_CIRData68 : 96|8@1+ (1.0,0) [0|255] "" IPB_App1
 SG_ StatusCPDData4FBD_VR_CIRData69 : 104|8@1+ (1.0,0) [0|255] "" IPB_App1
 SG_ StatusCPDData4FBD_VR_CIRData70 : 112|8@1+ (1.0,0) [0|255] "" IPB_App1
 SG_ StatusCPDData4FBD_VR_CIRData71 : 120|8@1+ (1.0,0) [0|255] "" IPB_App1
 SG_ StatusCPDData4FBD_VR_CIRData72 : 128|8@1+ (1.0,0) [0|255] "" IPB_App1
 SG_ StatusCPDData4FBD_VR_CIRData73 : 136|8@1+ (1.0,0) [0|255] "" IPB_App1
 SG_ StatusCPDData4FBD_VR_CIRData74 : 144|8@1+ (1.0,0) [0|255] "" IPB_App1
 SG_ StatusCPDData4FBD_VR_CIRData75 : 152|8@1+ (1.0,0) [0|255] "" IPB_App1
 SG_ StatusCPDData4FBD_VR_CIRData76 : 160|8@1+ (1.0,0) [0|255] "" IPB_App1
 SG_ StatusCPDData4FBD_VR_CIRData77 : 168|8@1+ (1.0,0) [0|255] "" IPB_App1
 SG_ StatusCPDData4FBD_VR_CIRData78 : 176|8@1+ (1.0,0) [0|255] "" IPB_App1
 SG_ StatusCPDData4FBD_VR_CIRData79 : 184|8@1+ (1.0,0) [0|255] "" IPB_App1
 SG_ StatusCPDData4FBD_VR_CIRData80 : 192|8@1+ (1.0,0) [0|255] "" IPB_App1
 SG_ StatusCPDData4FBD_VR_CIRData81 : 200|8@1+ (1.0,0) [0|255] "" IPB_App1
 SG_ StatusCPDData4FBD_VR_CIRData82 : 208|8@1+ (1.0,0) [0|255] "" IPB_App1
 SG_ StatusCPDData4FBD_VR_CIRData83 : 216|8@1+ (1.0,0) [0|255] "" IPB_App1
 SG_ StatusCPDData4FBD_VR_CIRData84 : 224|8@1+ (1.0,0) [0|255] "" IPB_App1
 SG_ StatusCPDData4FBD_VR_CIRData85 : 232|8@1+ (1.0,0) [0|255] "" IPB_App1
 SG_ StatusCPDData4FBD_VR_CIRData86 : 240|8@1+ (1.0,0) [0|255] "" IPB_App1
 SG_ StatusCPDData4FBD_VR_CIRData87 : 248|8@1+ (1.0,0) [0|255] "" IPB_App1
 SG_ StatusCPDData4FBD_VR_CIRData88 : 256|8@1+ (1.0,0) [0|255] "" IPB_App1
 SG_ StatusCPDData4FBD_VR_CIRData89 : 264|8@1+ (1.0,0) [0|255] "" IPB_App1
 SG_ StatusCPDData4FBD_VR_CIRData90 : 272|8@1+ (1.0,0) [0|255] "" IPB_App1
 SG_ StatusCPDData4FBD_VR_CIRData91 : 280|8@1+ (1.0,0) [0|255] "" IPB_App1
 SG_ StatusCPDData4FBD_VR_CIRData92 : 288|8@1+ (1.0,0) [0|255] "" IPB_App1
 SG_ StatusCPDData4FBD_VR_CIRData93 : 296|8@1+ (1.0,0) [0|255] "" IPB_App1
 SG_ StatusCPDData4FBD_VR_CIRData94 : 304|8@1+ (1.0,0) [0|255] "" IPB_App1
 SG_ StatusCPDData4FBD_VR_CIRData95 : 312|8@1+ (1.0,0) [0|255] "" IPB_App1
 SG_ StatusCPDData4FBD_VR_CIRData96 : 320|8@1+ (1.0,0) [0|255] "" IPB_App1
 SG_ StatusCPDData4FBD_VR_CIRData97 : 328|8@1+ (1.0,0) [0|255] "" IPB_App1
 SG_ StatusCPDData4FBD_VR_CIRData98 : 336|8@1+ (1.0,0) [0|255] "" IPB_App1
 SG_ StatusCPDData4FBD_VR_CIRData99 : 344|8@1+ (1.0,0) [0|255] "" IPB_App1
 SG_ StatusCPDData4FBD_VR_CIRData100 : 352|8@1+ (1.0,0) [0|255] "" IPB_App1
 SG_ StatusCPDData4FBD_VR_CIRData101 : 360|8@1+ (1.0,0) [0|255] "" IPB_App1
 SG_ StatusCPDData4FBD_VR_CIRData102 : 368|8@1+ (1.0,0) [0|255] "" IPB_App1
 SG_ StatusCPDData4FBD_VR_CIRData103 : 376|8@1+ (1.0,0) [0|255] "" IPB_App1
 SG_ StatusCPDData4FBD_VR_CIRData104 : 384|8@1+ (1.0,0) [0|255] "" IPB_App1
 SG_ StatusCPDData4FBD_VR_CIRData105 : 392|8@1+ (1.0,0) [0|255] "" IPB_App1
 SG_ StatusCPDData4FBD_VR_CIRData106 : 400|8@1+ (1.0,0) [0|255] "" IPB_App1
 SG_ StatusCPDData4FBD_VR_CIRData107 : 408|8@1+ (1.0,0) [0|255] "" IPB_App1
 SG_ StatusCPDData4FBD_VR_CIRData108 : 416|8@1+ (1.0,0) [0|255] "" IPB_App1
 SG_ StatusCPDData4FBD_VR_CIRData109 : 424|8@1+ (1.0,0) [0|255] "" IPB_App1
 SG_ StatusCPDData4FBD_VR_CIRData110 : 432|8@1+ (1.0,0) [0|255] "" IPB_App1
 SG_ StatusCPDData4FBD_VR_CIRData111 : 440|8@1+ (1.0,0) [0|255] "" IPB_App1
 SG_ StatusCPDData4FBD_VR_CIRData112 : 448|8@1+ (1.0,0) [0|255] "" IPB_App1
 SG_ StatusCPDData4FBD_VR_CIRData113 : 456|8@1+ (1.0,0) [0|255] "" IPB_App1
 SG_ StatusCPDData4FBD_VR_CIRData114 : 464|8@1+ (1.0,0) [0|255] "" IPB_App1
 SG_ StatusCPDData4FBD_VR_CIRData115 : 472|8@1+ (1.0,0) [0|255] "" IPB_App1
 SG_ StatusCPDData4FBD_VR_CIRData116 : 480|8@1+ (1.0,0) [0|255] "" IPB_App1
 SG_ StatusCPDData4FBD_VR_CIRData117 : 488|8@1+ (1.0,0) [0|255] "" IPB_App1
 SG_ StatusCPDData4FBD_VR_CIRData118 : 496|8@1+ (1.0,0) [0|255] "" IPB_App1
 SG_ StatusCPDData4FBD_VR_CIRData119 : 504|8@1+ (1.0,0) [0|255] "" IPB_App1

BO_ 196 StatusCSRangingFBD_HL: 24 FBD_HL
 SG_ StatusCSRangingFBD_HL_SessionID : 0|8@1+ (1.0,0) [0|252] "" IPB_App1
 SG_ StatusCSRangingFBD_HL_IRKListInd : 8|8@1+ (1.0,0) [0|252] "" IPB_App1
 SG_ StatusCSRangingFBD_HL_Distance : 16|16@1+ (1.0,0) [0|65532] "cm" IPB_App1
 SG_ StatusCSRangingFBD_HL_ProcedureC : 32|16@1+ (1.0,0) [0|65532] "" IPB_App1
 SG_ StatusCSRangingFBD_HL_Quality : 48|8@1+ (1.0,0) [0|252] "" IPB_App1
 SG_ StatusCSRangingFBD_HL_RoundTripT : 56|16@1+ (1.0,0) [0|65532] "cm" IPB_App1
 SG_ StatusCSRangingFBD_HL_IV00 : 72|8@1+ (1.0,0) [0|255] "" IPB_App1
 SG_ StatusCSRangingFBD_HL_IV01 : 80|8@1+ (1.0,0) [0|255] "" IPB_App1
 SG_ StatusCSRangingFBD_HL_IV02 : 88|8@1+ (1.0,0) [0|255] "" IPB_App1
 SG_ StatusCSRangingFBD_HL_IV03 : 96|8@1+ (1.0,0) [0|255] "" IPB_App1
 SG_ StatusCSRangingFBD_HL_Sign00 : 104|8@1+ (1.0,0) [0|255] "" IPB_App1
 SG_ StatusCSRangingFBD_HL_Sign01 : 112|8@1+ (1.0,0) [0|255] "" IPB_App1
 SG_ StatusCSRangingFBD_HL_Sign02 : 120|8@1+ (1.0,0) [0|255] "" IPB_App1
 SG_ StatusCSRangingFBD_HL_Sign03 : 128|8@1+ (1.0,0) [0|255] "" IPB_App1
 SG_ StatusCSRangingFBD_HL_Sign04 : 136|8@1+ (1.0,0) [0|255] "" IPB_App1
 SG_ StatusCSRangingFBD_HL_Sign05 : 144|8@1+ (1.0,0) [0|255] "" IPB_App1
 SG_ StatusCSRangingFBD_HL_Sign06 : 152|8@1+ (1.0,0) [0|255] "" IPB_App1
 SG_ StatusCSRangingFBD_HL_Sign07 : 160|8@1+ (1.0,0) [0|255] "" IPB_App1
 SG_ StatusCSRangingFBD_HL_Status1 : 168|8@1+ (1.0,0) [0|252] "" IPB_App1
 SG_ StatusCSRangingFBD_HL_Status2 : 176|8@1+ (1.0,0) [0|252] "" IPB_App1
 SG_ StatusCSRangingFBD_HL_NADM : 184|8@1+ (1,0) [0|0] "" IPB_App1

BO_ 191 StatusCSRangingFBD_HM: 24 FBD_HM
 SG_ StatusCSRangingFBD_HM_SessionID : 0|8@1+ (1.0,0) [0|252] "" IPB_App1
 SG_ StatusCSRangingFBD_HM_IRKListInd : 8|8@1+ (1.0,0) [0|252] "" IPB_App1
 SG_ StatusCSRangingFBD_HM_Distance : 16|16@1+ (1.0,0) [0|65532] "cm" IPB_App1
 SG_ StatusCSRangingFBD_HM_ProcedureC : 32|16@1+ (1.0,0) [0|65532] "" IPB_App1
 SG_ StatusCSRangingFBD_HM_Quality : 48|8@1+ (1.0,0) [0|252] "" IPB_App1
 SG_ StatusCSRangingFBD_HM_RoundTripT : 56|16@1+ (1.0,0) [0|65532] "cm" IPB_App1
 SG_ StatusCSRangingFBD_HM_IV00 : 72|8@1+ (1.0,0) [0|255] "" IPB_App1
 SG_ StatusCSRangingFBD_HM_IV01 : 80|8@1+ (1.0,0) [0|255] "" IPB_App1
 SG_ StatusCSRangingFBD_HM_IV02 : 88|8@1+ (1.0,0) [0|255] "" IPB_App1
 SG_ StatusCSRangingFBD_HM_IV03 : 96|8@1+ (1.0,0) [0|255] "" IPB_App1
 SG_ StatusCSRangingFBD_HM_Sign00 : 104|8@1+ (1.0,0) [0|255] "" IPB_App1
 SG_ StatusCSRangingFBD_HM_Sign01 : 112|8@1+ (1.0,0) [0|255] "" IPB_App1
 SG_ StatusCSRangingFBD_HM_Sign02 : 120|8@1+ (1.0,0) [0|255] "" IPB_App1
 SG_ StatusCSRangingFBD_HM_Sign03 : 128|8@1+ (1.0,0) [0|255] "" IPB_App1
 SG_ StatusCSRangingFBD_HM_Sign04 : 136|8@1+ (1.0,0) [0|255] "" IPB_App1
 SG_ StatusCSRangingFBD_HM_Sign05 : 144|8@1+ (1.0,0) [0|255] "" IPB_App1
 SG_ StatusCSRangingFBD_HM_Sign06 : 152|8@1+ (1.0,0) [0|255] "" IPB_App1
 SG_ StatusCSRangingFBD_HM_Sign07 : 160|8@1+ (1.0,0) [0|255] "" IPB_App1
 SG_ StatusCSRangingFBD_HM_Status1 : 168|8@1+ (1.0,0) [0|252] "" IPB_App1
 SG_ StatusCSRangingFBD_HM_Status2 : 176|8@1+ (1.0,0) [0|252] "" IPB_App1
 SG_ StatusCSRangingFBD_HM_NADM : 184|8@1+ (1,0) [0|0] "" IPB_App1

BO_ 197 StatusCSRangingFBD_HR: 24 FBD_HR
 SG_ StatusCSRangingFBD_HR_SessionID : 0|8@1+ (1.0,0) [0|252] "" IPB_App1
 SG_ StatusCSRangingFBD_HR_IRKListInd : 8|8@1+ (1.0,0) [0|252] "" IPB_App1
 SG_ StatusCSRangingFBD_HR_Distance : 16|16@1+ (1.0,0) [0|65532] "cm" IPB_App1
 SG_ StatusCSRangingFBD_HR_ProcedureC : 32|16@1+ (1.0,0) [0|65532] "" IPB_App1
 SG_ StatusCSRangingFBD_HR_Quality : 48|8@1+ (1.0,0) [0|252] "" IPB_App1
 SG_ StatusCSRangingFBD_HR_RoundTripT : 56|16@1+ (1.0,0) [0|65532] "cm" IPB_App1
 SG_ StatusCSRangingFBD_HR_IV00 : 72|8@1+ (1.0,0) [0|255] "" IPB_App1
 SG_ StatusCSRangingFBD_HR_IV01 : 80|8@1+ (1.0,0) [0|255] "" IPB_App1
 SG_ StatusCSRangingFBD_HR_IV02 : 88|8@1+ (1.0,0) [0|255] "" IPB_App1
 SG_ StatusCSRangingFBD_HR_IV03 : 96|8@1+ (1.0,0) [0|255] "" IPB_App1
 SG_ StatusCSRangingFBD_HR_Sign00 : 104|8@1+ (1.0,0) [0|255] "" IPB_App1
 SG_ StatusCSRangingFBD_HR_Sign01 : 112|8@1+ (1.0,0) [0|255] "" IPB_App1
 SG_ StatusCSRangingFBD_HR_Sign02 : 120|8@1+ (1.0,0) [0|255] "" IPB_App1
 SG_ StatusCSRangingFBD_HR_Sign03 : 128|8@1+ (1.0,0) [0|255] "" IPB_App1
 SG_ StatusCSRangingFBD_HR_Sign04 : 136|8@1+ (1.0,0) [0|255] "" IPB_App1
 SG_ StatusCSRangingFBD_HR_Sign05 : 144|8@1+ (1.0,0) [0|255] "" IPB_App1
 SG_ StatusCSRangingFBD_HR_Sign06 : 152|8@1+ (1.0,0) [0|255] "" IPB_App1
 SG_ StatusCSRangingFBD_HR_Sign07 : 160|8@1+ (1.0,0) [0|255] "" IPB_App1
 SG_ StatusCSRangingFBD_HR_Status1 : 168|8@1+ (1.0,0) [0|252] "" IPB_App1
 SG_ StatusCSRangingFBD_HR_Status2 : 176|8@1+ (1.0,0) [0|252] "" IPB_App1
 SG_ StatusCSRangingFBD_HR_NADM : 184|8@1+ (1,0) [0|0] "" IPB_App1

BO_ 192 StatusCSRangingFBD_Miko: 24 FBD_Miko
 SG_ StatusCSRangingFBD_Miko_SessionI : 0|8@1+ (1.0,0) [0|252] "" IPB_App1
 SG_ StatusCSRangingFBD_Miko_IRKListI : 8|8@1+ (1.0,0) [0|252] "" IPB_App1
 SG_ StatusCSRangingFBD_Miko_Distance : 16|16@1+ (1.0,0) [0|65532] "cm" IPB_App1
 SG_ StatusCSRangingFBD_Miko_Procedur : 32|16@1+ (1.0,0) [0|65532] "" IPB_App1
 SG_ StatusCSRangingFBD_Miko_Quality : 48|8@1+ (1.0,0) [0|252] "" IPB_App1
 SG_ StatusCSRangingFBD_Miko_RoundTri : 56|16@1+ (1.0,0) [0|65532] "cm" IPB_App1
 SG_ StatusCSRangingFBD_Miko_IV00 : 72|8@1+ (1.0,0) [0|255] "" IPB_App1
 SG_ StatusCSRangingFBD_Miko_IV01 : 80|8@1+ (1.0,0) [0|255] "" IPB_App1
 SG_ StatusCSRangingFBD_Miko_IV02 : 88|8@1+ (1.0,0) [0|255] "" IPB_App1
 SG_ StatusCSRangingFBD_Miko_IV03 : 96|8@1+ (1.0,0) [0|255] "" IPB_App1
 SG_ StatusCSRangingFBD_Miko_Sign00 : 104|8@1+ (1.0,0) [0|255] "" IPB_App1
 SG_ StatusCSRangingFBD_Miko_Sign01 : 112|8@1+ (1.0,0) [0|255] "" IPB_App1
 SG_ StatusCSRangingFBD_Miko_Sign02 : 120|8@1+ (1.0,0) [0|255] "" IPB_App1
 SG_ StatusCSRangingFBD_Miko_Sign03 : 128|8@1+ (1.0,0) [0|255] "" IPB_App1
 SG_ StatusCSRangingFBD_Miko_Sign04 : 136|8@1+ (1.0,0) [0|255] "" IPB_App1
 SG_ StatusCSRangingFBD_Miko_Sign05 : 144|8@1+ (1.0,0) [0|255] "" IPB_App1
 SG_ StatusCSRangingFBD_Miko_Sign06 : 152|8@1+ (1.0,0) [0|255] "" IPB_App1
 SG_ StatusCSRangingFBD_Miko_Sign07 : 160|8@1+ (1.0,0) [0|255] "" IPB_App1
 SG_ StatusCSRangingFBD_Miko_Status1 : 168|8@1+ (1.0,0) [0|252] "" IPB_App1
 SG_ StatusCSRangingFBD_Miko_Status2 : 176|8@1+ (1.0,0) [0|252] "" IPB_App1
 SG_ StatusCSRangingFBD_Miko_NADM : 184|8@1+ (1,0) [0|0] "" IPB_App1

BO_ 198 StatusCSRangingFBD_MM: 24 FBD_MM
 SG_ StatusCSRangingFBD_MM_SessionID : 0|8@1+ (1.0,0) [0|252] "" IPB_App1
 SG_ StatusCSRangingFBD_MM_IRKListInd : 8|8@1+ (1.0,0) [0|252] "" IPB_App1
 SG_ StatusCSRangingFBD_MM_Distance : 16|16@1+ (1.0,0) [0|65532] "cm" IPB_App1
 SG_ StatusCSRangingFBD_MM_ProcedureC : 32|16@1+ (1.0,0) [0|65532] "" IPB_App1
 SG_ StatusCSRangingFBD_MM_Quality : 48|8@1+ (1.0,0) [0|252] "" IPB_App1
 SG_ StatusCSRangingFBD_MM_RoundTripT : 56|16@1+ (1.0,0) [0|65532] "cm" IPB_App1
 SG_ StatusCSRangingFBD_MM_IV00 : 72|8@1+ (1.0,0) [0|255] "" IPB_App1
 SG_ StatusCSRangingFBD_MM_IV01 : 80|8@1+ (1.0,0) [0|255] "" IPB_App1
 SG_ StatusCSRangingFBD_MM_IV02 : 88|8@1+ (1.0,0) [0|255] "" IPB_App1
 SG_ StatusCSRangingFBD_MM_IV03 : 96|8@1+ (1.0,0) [0|255] "" IPB_App1
 SG_ StatusCSRangingFBD_MM_Sign00 : 104|8@1+ (1.0,0) [0|255] "" IPB_App1
 SG_ StatusCSRangingFBD_MM_Sign01 : 112|8@1+ (1.0,0) [0|255] "" IPB_App1
 SG_ StatusCSRangingFBD_MM_Sign02 : 120|8@1+ (1.0,0) [0|255] "" IPB_App1
 SG_ StatusCSRangingFBD_MM_Sign03 : 128|8@1+ (1.0,0) [0|255] "" IPB_App1
 SG_ StatusCSRangingFBD_MM_Sign04 : 136|8@1+ (1.0,0) [0|255] "" IPB_App1
 SG_ StatusCSRangingFBD_MM_Sign05 : 144|8@1+ (1.0,0) [0|255] "" IPB_App1
 SG_ StatusCSRangingFBD_MM_Sign06 : 152|8@1+ (1.0,0) [0|255] "" IPB_App1
 SG_ StatusCSRangingFBD_MM_Sign07 : 160|8@1+ (1.0,0) [0|255] "" IPB_App1
 SG_ StatusCSRangingFBD_MM_Status1 : 168|8@1+ (1.0,0) [0|252] "" IPB_App1
 SG_ StatusCSRangingFBD_MM_Status2 : 176|8@1+ (1.0,0) [0|252] "" IPB_App1
 SG_ StatusCSRangingFBD_MM_NADM : 184|8@1+ (1,0) [0|0] "" IPB_App1

BO_ 193 StatusCSRangingFBD_Trunk: 24 FBD_Trunk
 SG_ StatusCSRangingFBD_Trunk_Session : 0|8@1+ (1.0,0) [0|252] "" IPB_App1
 SG_ StatusCSRangingFBD_Trunk_IRKList : 8|8@1+ (1.0,0) [0|252] "" IPB_App1
 SG_ StatusCSRangingFBD_Trunk_Distanc : 16|16@1+ (1.0,0) [0|65532] "cm" IPB_App1
 SG_ StatusCSRangingFBD_Trunk_Procedu : 32|16@1+ (1.0,0) [0|65532] "" IPB_App1
 SG_ StatusCSRangingFBD_Trunk_Quality : 48|8@1+ (1.0,0) [0|252] "" IPB_App1
 SG_ StatusCSRangingFBD_Trunk_RoundTr : 56|16@1+ (1.0,0) [0|65532] "cm" IPB_App1
 SG_ StatusCSRangingFBD_Trunk_IV00 : 72|8@1+ (1.0,0) [0|255] "" IPB_App1
 SG_ StatusCSRangingFBD_Trunk_IV01 : 80|8@1+ (1.0,0) [0|255] "" IPB_App1
 SG_ StatusCSRangingFBD_Trunk_IV02 : 88|8@1+ (1.0,0) [0|255] "" IPB_App1
 SG_ StatusCSRangingFBD_Trunk_IV03 : 96|8@1+ (1.0,0) [0|255] "" IPB_App1
 SG_ StatusCSRangingFBD_Trunk_Sign00 : 104|8@1+ (1.0,0) [0|255] "" IPB_App1
 SG_ StatusCSRangingFBD_Trunk_Sign01 : 112|8@1+ (1.0,0) [0|255] "" IPB_App1
 SG_ StatusCSRangingFBD_Trunk_Sign02 : 120|8@1+ (1.0,0) [0|255] "" IPB_App1
 SG_ StatusCSRangingFBD_Trunk_Sign03 : 128|8@1+ (1.0,0) [0|255] "" IPB_App1
 SG_ StatusCSRangingFBD_Trunk_Sign04 : 136|8@1+ (1.0,0) [0|255] "" IPB_App1
 SG_ StatusCSRangingFBD_Trunk_Sign05 : 144|8@1+ (1.0,0) [0|255] "" IPB_App1
 SG_ StatusCSRangingFBD_Trunk_Sign06 : 152|8@1+ (1.0,0) [0|255] "" IPB_App1
 SG_ StatusCSRangingFBD_Trunk_Sign07 : 160|8@1+ (1.0,0) [0|255] "" IPB_App1
 SG_ StatusCSRangingFBD_Trunk_Status1 : 168|8@1+ (1.0,0) [0|252] "" IPB_App1
 SG_ StatusCSRangingFBD_Trunk_Status2 : 176|8@1+ (1.0,0) [0|252] "" IPB_App1
 SG_ StatusCSRangingFBD_Trunk_NADM : 184|8@1+ (1,0) [0|0] "" IPB_App1

BO_ 194 StatusCSRangingFBD_VL: 24 FBD_VL
 SG_ StatusCSRangingFBD_VL_SessionID : 0|8@1+ (1.0,0) [0|252] "" IPB_App1
 SG_ StatusCSRangingFBD_VL_IRKListInd : 8|8@1+ (1.0,0) [0|252] "" IPB_App1
 SG_ StatusCSRangingFBD_VL_Distance : 16|16@1+ (1.0,0) [0|65532] "cm" IPB_App1
 SG_ StatusCSRangingFBD_VL_ProcedureC : 32|16@1+ (1.0,0) [0|65532] "" IPB_App1
 SG_ StatusCSRangingFBD_VL_Quality : 48|8@1+ (1.0,0) [0|252] "" IPB_App1
 SG_ StatusCSRangingFBD_VL_RoundTripT : 56|16@1+ (1.0,0) [0|65532] "cm" IPB_App1
 SG_ StatusCSRangingFBD_VL_IV00 : 72|8@1+ (1.0,0) [0|255] "" IPB_App1
 SG_ StatusCSRangingFBD_VL_IV01 : 80|8@1+ (1.0,0) [0|255] "" IPB_App1
 SG_ StatusCSRangingFBD_VL_IV02 : 88|8@1+ (1.0,0) [0|255] "" IPB_App1
 SG_ StatusCSRangingFBD_VL_IV03 : 96|8@1+ (1.0,0) [0|255] "" IPB_App1
 SG_ StatusCSRangingFBD_VL_Sign00 : 104|8@1+ (1.0,0) [0|255] "" IPB_App1
 SG_ StatusCSRangingFBD_VL_Sign01 : 112|8@1+ (1.0,0) [0|255] "" IPB_App1
 SG_ StatusCSRangingFBD_VL_Sign02 : 120|8@1+ (1.0,0) [0|255] "" IPB_App1
 SG_ StatusCSRangingFBD_VL_Sign03 : 128|8@1+ (1.0,0) [0|255] "" IPB_App1
 SG_ StatusCSRangingFBD_VL_Sign04 : 136|8@1+ (1.0,0) [0|255] "" IPB_App1
 SG_ StatusCSRangingFBD_VL_Sign05 : 144|8@1+ (1.0,0) [0|255] "" IPB_App1
 SG_ StatusCSRangingFBD_VL_Sign06 : 152|8@1+ (1.0,0) [0|255] "" IPB_App1
 SG_ StatusCSRangingFBD_VL_Sign07 : 160|8@1+ (1.0,0) [0|255] "" IPB_App1
 SG_ StatusCSRangingFBD_VL_Status1 : 168|8@1+ (1.0,0) [0|252] "" IPB_App1
 SG_ StatusCSRangingFBD_VL_Status2 : 176|8@1+ (1.0,0) [0|252] "" IPB_App1
 SG_ StatusCSRangingFBD_VL_NADM : 184|8@1+ (1,0) [0|0] "" IPB_App1

BO_ 190 StatusCSRangingFBD_VM: 24 FBD_VM
 SG_ StatusCSRangingFBD_VM_SessionID : 0|8@1+ (1.0,0) [0|252] "" IPB_App1
 SG_ StatusCSRangingFBD_VM_IRKListInd : 8|8@1+ (1.0,0) [0|252] "" IPB_App1
 SG_ StatusCSRangingFBD_VM_Distance : 16|16@1+ (1.0,0) [0|65532] "cm" IPB_App1
 SG_ StatusCSRangingFBD_VM_ProcedureC : 32|16@1+ (1.0,0) [0|65532] "" IPB_App1
 SG_ StatusCSRangingFBD_VM_Quality : 48|8@1+ (1.0,0) [0|252] "" IPB_App1
 SG_ StatusCSRangingFBD_VM_RoundTripT : 56|16@1+ (1.0,0) [0|65532] "cm" IPB_App1
 SG_ StatusCSRangingFBD_VM_IV00 : 72|8@1+ (1.0,0) [0|255] "" IPB_App1
 SG_ StatusCSRangingFBD_VM_IV01 : 80|8@1+ (1.0,0) [0|255] "" IPB_App1
 SG_ StatusCSRangingFBD_VM_IV02 : 88|8@1+ (1.0,0) [0|255] "" IPB_App1
 SG_ StatusCSRangingFBD_VM_IV03 : 96|8@1+ (1.0,0) [0|255] "" IPB_App1
 SG_ StatusCSRangingFBD_VM_Sign00 : 104|8@1+ (1.0,0) [0|255] "" IPB_App1
 SG_ StatusCSRangingFBD_VM_Sign01 : 112|8@1+ (1.0,0) [0|255] "" IPB_App1
 SG_ StatusCSRangingFBD_VM_Sign02 : 120|8@1+ (1.0,0) [0|255] "" IPB_App1
 SG_ StatusCSRangingFBD_VM_Sign03 : 128|8@1+ (1.0,0) [0|255] "" IPB_App1
 SG_ StatusCSRangingFBD_VM_Sign04 : 136|8@1+ (1.0,0) [0|255] "" IPB_App1
 SG_ StatusCSRangingFBD_VM_Sign05 : 144|8@1+ (1.0,0) [0|255] "" IPB_App1
 SG_ StatusCSRangingFBD_VM_Sign06 : 152|8@1+ (1.0,0) [0|255] "" IPB_App1
 SG_ StatusCSRangingFBD_VM_Sign07 : 160|8@1+ (1.0,0) [0|255] "" IPB_App1
 SG_ StatusCSRangingFBD_VM_Status1 : 168|8@1+ (1.0,0) [0|252] "" IPB_App1
 SG_ StatusCSRangingFBD_VM_Status2 : 176|8@1+ (1.0,0) [0|252] "" IPB_App1
 SG_ StatusCSRangingFBD_VM_NADM : 184|8@1+ (1,0) [0|0] "" IPB_App1

BO_ 195 StatusCSRangingFBD_VR: 24 FBD_VR
 SG_ StatusCSRangingFBD_VR_SessionID : 0|8@1+ (1.0,0) [0|252] "" IPB_App1
 SG_ StatusCSRangingFBD_VR_IRKListInd : 8|8@1+ (1.0,0) [0|252] "" IPB_App1
 SG_ StatusCSRangingFBD_VR_Distance : 16|16@1+ (1.0,0) [0|65532] "cm" IPB_App1
 SG_ StatusCSRangingFBD_VR_ProcedureC : 32|16@1+ (1.0,0) [0|65532] "" IPB_App1
 SG_ StatusCSRangingFBD_VR_Quality : 48|8@1+ (1.0,0) [0|252] "" IPB_App1
 SG_ StatusCSRangingFBD_VR_RoundTripT : 56|16@1+ (1.0,0) [0|65532] "cm" IPB_App1
 SG_ StatusCSRangingFBD_VR_IV00 : 72|8@1+ (1.0,0) [0|255] "" IPB_App1
 SG_ StatusCSRangingFBD_VR_IV01 : 80|8@1+ (1.0,0) [0|255] "" IPB_App1
 SG_ StatusCSRangingFBD_VR_IV02 : 88|8@1+ (1.0,0) [0|255] "" IPB_App1
 SG_ StatusCSRangingFBD_VR_IV03 : 96|8@1+ (1.0,0) [0|255] "" IPB_App1
 SG_ StatusCSRangingFBD_VR_Sign00 : 104|8@1+ (1.0,0) [0|255] "" IPB_App1
 SG_ StatusCSRangingFBD_VR_Sign01 : 112|8@1+ (1.0,0) [0|255] "" IPB_App1
 SG_ StatusCSRangingFBD_VR_Sign02 : 120|8@1+ (1.0,0) [0|255] "" IPB_App1
 SG_ StatusCSRangingFBD_VR_Sign03 : 128|8@1+ (1.0,0) [0|255] "" IPB_App1
 SG_ StatusCSRangingFBD_VR_Sign04 : 136|8@1+ (1.0,0) [0|255] "" IPB_App1
 SG_ StatusCSRangingFBD_VR_Sign05 : 144|8@1+ (1.0,0) [0|255] "" IPB_App1
 SG_ StatusCSRangingFBD_VR_Sign06 : 152|8@1+ (1.0,0) [0|255] "" IPB_App1
 SG_ StatusCSRangingFBD_VR_Sign07 : 160|8@1+ (1.0,0) [0|255] "" IPB_App1
 SG_ StatusCSRangingFBD_VR_Status1 : 168|8@1+ (1.0,0) [0|252] "" IPB_App1
 SG_ StatusCSRangingFBD_VR_Status2 : 176|8@1+ (1.0,0) [0|252] "" IPB_App1
 SG_ StatusCSRangingFBD_VR_NADM : 184|8@1+ (1,0) [0|0] "" IPB_App1

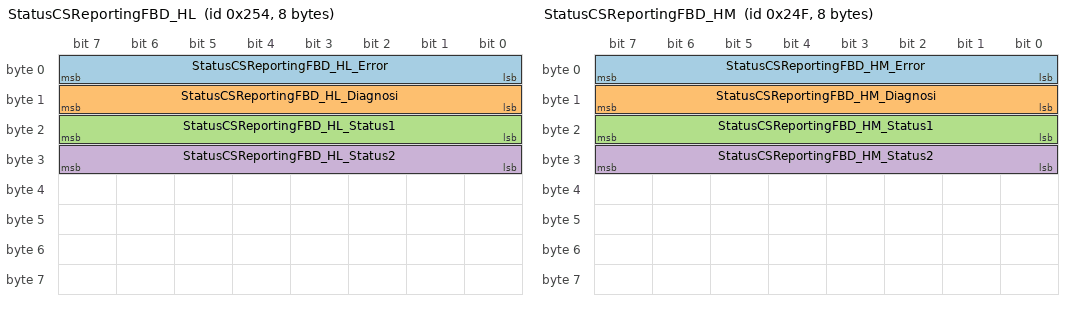
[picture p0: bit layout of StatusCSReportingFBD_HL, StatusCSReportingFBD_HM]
BO_ 596 StatusCSReportingFBD_HL: 8 FBD_HL
 SG_ StatusCSReportingFBD_HL_Error : 0|8@1+ (1,0) [0|0] "" IPB_App1
 SG_ StatusCSReportingFBD_HL_Diagnosi : 8|8@1+ (1.0,0) [0|252] "" IPB_App1
 SG_ StatusCSReportingFBD_HL_Status1 : 16|8@1+ (1.0,0) [0|252] "" IPB_App1
 SG_ StatusCSReportingFBD_HL_Status2 : 24|8@1+ (1.0,0) [0|252] "" IPB_App1

BO_ 591 StatusCSReportingFBD_HM: 8 FBD_HM
 SG_ StatusCSReportingFBD_HM_Error : 0|8@1+ (1,0) [0|0] "" IPB_App1
 SG_ StatusCSReportingFBD_HM_Diagnosi : 8|8@1+ (1.0,0) [0|252] "" IPB_App1
 SG_ StatusCSReportingFBD_HM_Status1 : 16|8@1+ (1.0,0) [0|252] "" IPB_App1
 SG_ StatusCSReportingFBD_HM_Status2 : 24|8@1+ (1.0,0) [0|252] "" IPB_App1

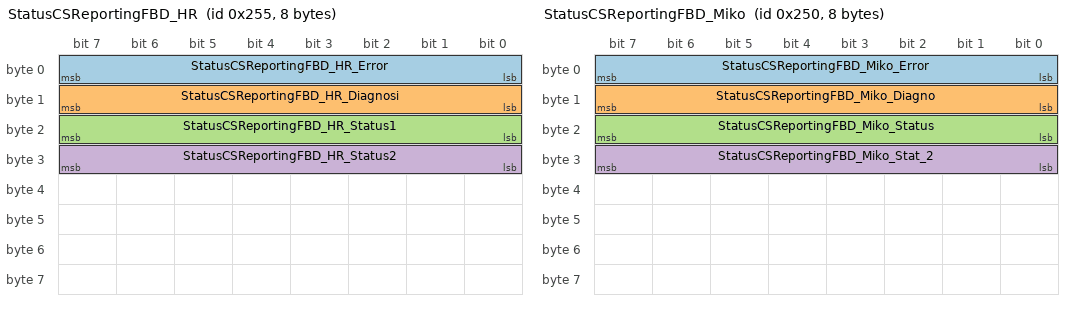
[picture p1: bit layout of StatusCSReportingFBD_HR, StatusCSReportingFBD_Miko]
BO_ 597 StatusCSReportingFBD_HR: 8 FBD_HR
 SG_ StatusCSReportingFBD_HR_Error : 0|8@1+ (1,0) [0|0] "" IPB_App1
 SG_ StatusCSReportingFBD_HR_Diagnosi : 8|8@1+ (1.0,0) [0|252] "" IPB_App1
 SG_ StatusCSReportingFBD_HR_Status1 : 16|8@1+ (1.0,0) [0|252] "" IPB_App1
 SG_ StatusCSReportingFBD_HR_Status2 : 24|8@1+ (1.0,0) [0|252] "" IPB_App1

BO_ 592 StatusCSReportingFBD_Miko: 8 FBD_Miko
 SG_ StatusCSReportingFBD_Miko_Error : 0|8@1+ (1,0) [0|0] "" IPB_App1
 SG_ StatusCSReportingFBD_Miko_Diagno : 8|8@1+ (1.0,0) [0|252] "" IPB_App1
 SG_ StatusCSReportingFBD_Miko_Status : 16|8@1+ (1.0,0) [0|252] "" IPB_App1
 SG_ StatusCSReportingFBD_Miko_Stat_2 : 24|8@1+ (1.0,0) [0|252] "" IPB_App1

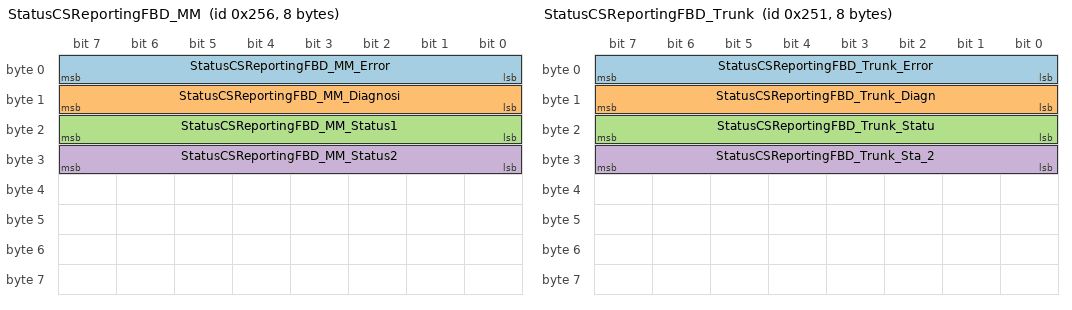
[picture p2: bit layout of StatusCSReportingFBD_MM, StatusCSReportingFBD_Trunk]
BO_ 598 StatusCSReportingFBD_MM: 8 FBD_MM
 SG_ StatusCSReportingFBD_MM_Error : 0|8@1+ (1,0) [0|0] "" IPB_App1
 SG_ StatusCSReportingFBD_MM_Diagnosi : 8|8@1+ (1.0,0) [0|252] "" IPB_App1
 SG_ StatusCSReportingFBD_MM_Status1 : 16|8@1+ (1.0,0) [0|252] "" IPB_App1
 SG_ StatusCSReportingFBD_MM_Status2 : 24|8@1+ (1.0,0) [0|252] "" IPB_App1

BO_ 593 StatusCSReportingFBD_Trunk: 8 FBD_Trunk
 SG_ StatusCSReportingFBD_Trunk_Error : 0|8@1+ (1,0) [0|0] "" IPB_App1
 SG_ StatusCSReportingFBD_Trunk_Diagn : 8|8@1+ (1.0,0) [0|252] "" IPB_App1
 SG_ StatusCSReportingFBD_Trunk_Statu : 16|8@1+ (1.0,0) [0|252] "" IPB_App1
 SG_ StatusCSReportingFBD_Trunk_Sta_2 : 24|8@1+ (1.0,0) [0|252] "" IPB_App1

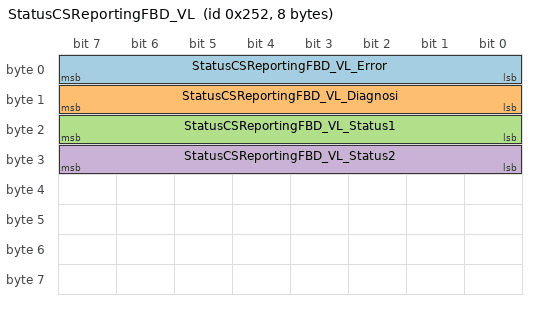
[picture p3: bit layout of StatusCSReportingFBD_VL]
BO_ 594 StatusCSReportingFBD_VL: 8 FBD_VL
 SG_ StatusCSReportingFBD_VL_Error : 0|8@1+ (1,0) [0|0] "" IPB_App1
 SG_ StatusCSReportingFBD_VL_Diagnosi : 8|8@1+ (1.0,0) [0|252] "" IPB_App1
 SG_ StatusCSReportingFBD_VL_Status1 : 16|8@1+ (1.0,0) [0|252] "" IPB_App1
 SG_ StatusCSReportingFBD_VL_Status2 : 24|8@1+ (1.0,0) [0|252] "" IPB_App1

CM_ SG_ 352 StatusCPDData3FBD_Miko_MsgCounte "contains counter";
CM_ SG_ 352 StatusCPDData3FBD_Miko_LinkID "contains link ID";
CM_ SG_ 352 StatusCPDData3FBD_Miko_AGCValue "contains AGC value";
CM_ SG_ 352 StatusCPDData3FBD_Miko_Channel "contains channel";
CM_ SG_ 352 StatusCPDData3FBD_Miko_CIRData00 "contains CPD data to tap 1 - real part MSB";
CM_ SG_ 352 StatusCPDData3FBD_Miko_CIRData01 "contains CPD data to tap 1 - real part LSB";
CM_ SG_ 352 StatusCPDData3FBD_Miko_CIRData02 "contains CPD data to tap 1 - imaginary part MSB";
CM_ SG_ 352 StatusCPDData3FBD_Miko_CIRData03 "contains CPD data to tap 1 - imaginary part LSB";
CM_ SG_ 352 StatusCPDData3FBD_Miko_CIRData04 "contains CPD data to tap 2 - real part MSB";
CM_ SG_ 352 StatusCPDData3FBD_Miko_CIRData05 "contains CPD data to tap 2 - real part LSB";
CM_ SG_ 352 StatusCPDData3FBD_Miko_CIRData06 "contains CPD data to tap 2 - imaginary part MSB";
CM_ SG_ 352 StatusCPDData3FBD_Miko_CIRData07 "contains CPD data to tap 2 - imaginary part LSB";
CM_ SG_ 352 StatusCPDData3FBD_Miko_CIRData08 "contains CPD data to tap 3 - real part MSB";
CM_ SG_ 352 StatusCPDData3FBD_Miko_CIRData09 "contains CPD data to tap 3 - real part LSB";
CM_ SG_ 352 StatusCPDData3FBD_Miko_CIRData10 "contains CPD data to tap 3 - imaginary part MSB";
CM_ SG_ 352 StatusCPDData3FBD_Miko_CIRData11 "contains CPD data to tap 3 - imaginary part LSB";
CM_ SG_ 352 StatusCPDData3FBD_Miko_CIRData12 "contains CPD data to tap 4 - real part MSB";
CM_ SG_ 352 StatusCPDData3FBD_Miko_CIRData13 "contains CPD data to tap 4 - real part LSB";
CM_ SG_ 352 StatusCPDData3FBD_Miko_CIRData14 "contains CPD data to tap 4 - imaginary part MSB";
CM_ SG_ 352 StatusCPDData3FBD_Miko_CIRData15 "contains CPD data to tap 4 - imaginary part LSB";
CM_ SG_ 352 StatusCPDData3FBD_Miko_CIRData16 "contains CPD data to tap 5 - real part MSB";
CM_ SG_ 352 StatusCPDData3FBD_Miko_CIRData17 "contains CPD data to tap 5 - real part LSB";
CM_ SG_ 352 StatusCPDData3FBD_Miko_CIRData18 "contains CPD data to tap 5 - imaginary part MSB";
CM_ SG_ 352 StatusCPDData3FBD_Miko_CIRData19 "contains CPD data to tap 5 - imaginary part LSB";
CM_ SG_ 352 StatusCPDData3FBD_Miko_CIRData20 "contains CPD data to tap 6 - real part MSB";
CM_ SG_ 352 StatusCPDData3FBD_Miko_CIRData21 "contains CPD data to tap 6 - real part LSB";
CM_ SG_ 352 StatusCPDData3FBD_Miko_CIRData22 "contains CPD data to tap 6 - imaginary part MSB";
CM_ SG_ 352 StatusCPDData3FBD_Miko_CIRData23 "contains CPD data to tap 6 - imaginary part LSB";
CM_ SG_ 352 StatusCPDData3FBD_Miko_CIRData24 "contains CPD data to tap 7 - real part MSB";
CM_ SG_ 352 StatusCPDData3FBD_Miko_CIRData25 "contains CPD data to tap 7 - real part LSB";
CM_ SG_ 352 StatusCPDData3FBD_Miko_CIRData26 "contains CPD data to tap 7 - imaginary part MSB";
CM_ SG_ 352 StatusCPDData3FBD_Miko_CIRData27 "contains CPD data to tap 7 - imaginary part LSB";
CM_ SG_ 352 StatusCPDData3FBD_Miko_CIRData28 "contains CPD data to tap 8 - real part MSB";
CM_ SG_ 352 StatusCPDData3FBD_Miko_CIRData29 "contains CPD data to tap 8 - real part LSB";
CM_ SG_ 352 StatusCPDData3FBD_Miko_CIRData30 "contains CPD data to tap 8 - imaginary part MSB";
CM_ SG_ 352 StatusCPDData3FBD_Miko_CIRData31 "contains CPD data to tap 8 - imaginary part LSB";
CM_ SG_ 352 StatusCPDData3FBD_Miko_CIRData32 "contains CPD data to tap 9 - real part MSB";
CM_ SG_ 352 StatusCPDData3FBD_Miko_CIRData33 "contains CPD data to tap 9 - real part LSB";
CM_ SG_ 352 StatusCPDData3FBD_Miko_CIRData34 "contains CPD data to tap 9 - imaginary part MSB";
CM_ SG_ 352 StatusCPDData3FBD_Miko_CIRData35 "contains CPD data to tap 9 - imaginary part LSB";
CM_ SG_ 352 StatusCPDData3FBD_Miko_CIRData36 "contains CPD data to tap 10 - real part MSB";
CM_ SG_ 352 StatusCPDData3FBD_Miko_CIRData37 "contains CPD data to tap 10 - real part LSB";
CM_ SG_ 352 StatusCPDData3FBD_Miko_CIRData38 "contains CPD data to tap 10 - imaginary part MSB";
CM_ SG_ 352 StatusCPDData3FBD_Miko_CIRData39 "contains CPD data to tap 10 - imaginary part LSB";
CM_ SG_ 352 StatusCPDData3FBD_Miko_CIRData40 "contains CPD data to tap 11 - real part MSB";
CM_ SG_ 352 StatusCPDData3FBD_Miko_CIRData41 "contains CPD data to tap 11 - real part LSB";
CM_ SG_ 352 StatusCPDData3FBD_Miko_CIRData42 "contains CPD data to tap 11 - imaginary part MSB";
CM_ SG_ 352 StatusCPDData3FBD_Miko_CIRData43 "contains CPD data to tap 11 - imaginary part LSB";
CM_ SG_ 352 StatusCPDData3FBD_Miko_CIRData44 "contains CPD data to tap 12 - real part MSB";
CM_ SG_ 352 StatusCPDData3FBD_Miko_CIRData45 "contains CPD data to tap 12 - real part LSB";
CM_ SG_ 352 StatusCPDData3FBD_Miko_CIRData46 "contains CPD data to tap 12 - imaginary part MSB";
CM_ SG_ 352 StatusCPDData3FBD_Miko_CIRData47 "contains CPD data to tap 12 - imaginary part LSB";
CM_ SG_ 352 StatusCPDData3FBD_Miko_CIRData48 "contains CPD data to tap 13 - real part MSB";
CM_ SG_ 352 StatusCPDData3FBD_Miko_CIRData49 "contains CPD data to tap 13 - real part LSB";
CM_ SG_ 352 StatusCPDData3FBD_Miko_CIRData50 "contains CPD data to tap 13 - imaginary part MSB";
CM_ SG_ 352 StatusCPDData3FBD_Miko_CIRData51 "contains CPD data to tap 13 - imaginary part LSB";
CM_ SG_ 352 StatusCPDData3FBD_Miko_CIRData52 "contains CPD data to tap 14 - real part MSB";
CM_ SG_ 352 StatusCPDData3FBD_Miko_CIRData53 "contains CPD data to tap 14 - real part LSB";
CM_ SG_ 352 StatusCPDData3FBD_Miko_CIRData54 "contains CPD data to tap 14 - imaginary part MSB";
CM_ SG_ 352 StatusCPDData3FBD_Miko_CIRData55 "contains CPD data to tap 14 - imaginary part LSB";
CM_ SG_ 352 StatusCPDData3FBD_Miko_CIRData56 "contains CPD data to tap 15 - real part MSB";
CM_ SG_ 352 StatusCPDData3FBD_Miko_CIRData57 "contains CPD data to tap 15 - real part LSB";
CM_ SG_ 352 StatusCPDData3FBD_Miko_CIRData58 "contains CPD data to tap 15 - imaginary part MSB";
CM_ SG_ 352 StatusCPDData3FBD_Miko_CIRData59 "contains CPD data to tap 15 - imaginary part LSB";
CM_ SG_ 835 StatusCPDData3FBD_MM_MsgCounter "contains counter";
CM_ SG_ 835 StatusCPDData3FBD_MM_LinkID "contains link ID";
CM_ SG_ 835 StatusCPDData3FBD_MM_AGCValue "contains AGC value";
CM_ SG_ 835 StatusCPDData3FBD_MM_Channel "contains channel";
CM_ SG_ 835 StatusCPDData3FBD_MM_CIRData00 "contains CPD data to tap 1 - real part MSB";
CM_ SG_ 835 StatusCPDData3FBD_MM_CIRData01 "contains CPD data to tap 1 - real part LSB";
CM_ SG_ 835 StatusCPDData3FBD_MM_CIRData02 "contains CPD data to tap 1 - imaginary part MSB";
CM_ SG_ 835 StatusCPDData3FBD_MM_CIRData03 "contains CPD data to tap 1 - imaginary part LSB";
CM_ SG_ 835 StatusCPDData3FBD_MM_CIRData04 "contains CPD data to tap 2 - real part MSB";
CM_ SG_ 835 StatusCPDData3FBD_MM_CIRData05 "contains CPD data to tap 2 - real part LSB";
CM_ SG_ 835 StatusCPDData3FBD_MM_CIRData06 "contains CPD data to tap 2 - imaginary part MSB";
CM_ SG_ 835 StatusCPDData3FBD_MM_CIRData07 "contains CPD data to tap 2 - imaginary part LSB";
CM_ SG_ 835 StatusCPDData3FBD_MM_CIRData08 "contains CPD data to tap 3 - real part MSB";
CM_ SG_ 835 StatusCPDData3FBD_MM_CIRData09 "contains CPD data to tap 3 - real part LSB";
CM_ SG_ 835 StatusCPDData3FBD_MM_CIRData10 "contains CPD data to tap 3 - imaginary part MSB";
CM_ SG_ 835 StatusCPDData3FBD_MM_CIRData11 "contains CPD data to tap 3 - imaginary part LSB";
CM_ SG_ 835 StatusCPDData3FBD_MM_CIRData12 "contains CPD data to tap 4 - real part MSB";
CM_ SG_ 835 StatusCPDData3FBD_MM_CIRData13 "contains CPD data to tap 4 - real part LSB";
CM_ SG_ 835 StatusCPDData3FBD_MM_CIRData14 "contains CPD data to tap 4 - imaginary part MSB";
CM_ SG_ 835 StatusCPDData3FBD_MM_CIRData15 "contains CPD data to tap 4 - imaginary part LSB";
CM_ SG_ 835 StatusCPDData3FBD_MM_CIRData16 "contains CPD data to tap 5 - real part MSB";
CM_ SG_ 835 StatusCPDData3FBD_MM_CIRData17 "contains CPD data to tap 5 - real part LSB";
CM_ SG_ 835 StatusCPDData3FBD_MM_CIRData18 "contains CPD data to tap 5 - imaginary part MSB";
CM_ SG_ 835 StatusCPDData3FBD_MM_CIRData19 "contains CPD data to tap 5 - imaginary part LSB";
CM_ SG_ 835 StatusCPDData3FBD_MM_CIRData20 "contains CPD data to tap 6 - real part MSB";
CM_ SG_ 835 StatusCPDData3FBD_MM_CIRData21 "contains CPD data to tap 6 - real part LSB";
CM_ SG_ 835 StatusCPDData3FBD_MM_CIRData22 "contains CPD data to tap 6 - imaginary part MSB";
CM_ SG_ 835 StatusCPDData3FBD_MM_CIRData23 "contains CPD data to tap 6 - imaginary part LSB";
CM_ SG_ 835 StatusCPDData3FBD_MM_CIRData24 "contains CPD data to tap 7 - real part MSB";
CM_ SG_ 835 StatusCPDData3FBD_MM_CIRData25 "contains CPD data to tap 7 - real part LSB";
CM_ SG_ 835 StatusCPDData3FBD_MM_CIRData26 "contains CPD data to tap 7 - imaginary part MSB";
CM_ SG_ 835 StatusCPDData3FBD_MM_CIRData27 "contains CPD data to tap 7 - imaginary part LSB";
CM_ SG_ 835 StatusCPDData3FBD_MM_CIRData28 "contains CPD data to tap 8 - real part MSB";
CM_ SG_ 835 StatusCPDData3FBD_MM_CIRData29 "contains CPD data to tap 8 - real part LSB";
CM_ SG_ 835 StatusCPDData3FBD_MM_CIRData30 "contains CPD data to tap 8 - imaginary part MSB";
CM_ SG_ 835 StatusCPDData3FBD_MM_CIRData31 "contains CPD data to tap 8 - imaginary part LSB";
CM_ SG_ 835 StatusCPDData3FBD_MM_CIRData32 "contains CPD data to tap 9 - real part MSB";
CM_ SG_ 835 StatusCPDData3FBD_MM_CIRData33 "contains CPD data to tap 9 - real part LSB";
CM_ SG_ 835 StatusCPDData3FBD_MM_CIRData34 "contains CPD data to tap 9 - imaginary part MSB";
CM_ SG_ 835 StatusCPDData3FBD_MM_CIRData35 "contains CPD data to tap 9 - imaginary part LSB";
CM_ SG_ 835 StatusCPDData3FBD_MM_CIRData36 "contains CPD data to tap 10 - real part MSB";
CM_ SG_ 835 StatusCPDData3FBD_MM_CIRData37 "contains CPD data to tap 10 - real part LSB";
CM_ SG_ 835 StatusCPDData3FBD_MM_CIRData38 "contains CPD data to tap 10 - imaginary part MSB";
CM_ SG_ 835 StatusCPDData3FBD_MM_CIRData39 "contains CPD data to tap 10 - imaginary part LSB";
CM_ SG_ 835 StatusCPDData3FBD_MM_CIRData40 "contains CPD data to tap 11 - real part MSB";
CM_ SG_ 835 StatusCPDData3FBD_MM_CIRData41 "contains CPD data to tap 11 - real part LSB";
CM_ SG_ 835 StatusCPDData3FBD_MM_CIRData42 "contains CPD data to tap 11 - imaginary part MSB";
CM_ SG_ 835 StatusCPDData3FBD_MM_CIRData43 "contains CPD data to tap 11 - imaginary part LSB";
CM_ SG_ 835 StatusCPDData3FBD_MM_CIRData44 "contains CPD data to tap 12 - real part MSB";
CM_ SG_ 835 StatusCPDData3FBD_MM_CIRData45 "contains CPD data to tap 12 - real part LSB";
CM_ SG_ 835 StatusCPDData3FBD_MM_CIRData46 "contains CPD data to tap 12 - imaginary part MSB";
CM_ SG_ 835 StatusCPDData3FBD_MM_CIRData47 "contains CPD data to tap 12 - imaginary part LSB";
CM_ SG_ 835 StatusCPDData3FBD_MM_CIRData48 "contains CPD data to tap 13 - real part MSB";
CM_ SG_ 835 StatusCPDData3FBD_MM_CIRData49 "contains CPD data to tap 13 - real part LSB";
CM_ SG_ 835 StatusCPDData3FBD_MM_CIRData50 "contains CPD data to tap 13 - imaginary part MSB";
CM_ SG_ 835 StatusCPDData3FBD_MM_CIRData51 "contains CPD data to tap 13 - imaginary part LSB";
CM_ SG_ 835 StatusCPDData3FBD_MM_CIRData52 "contains CPD data to tap 14 - real part MSB";
CM_ SG_ 835 StatusCPDData3FBD_MM_CIRData53 "contains CPD data to tap 14 - real part LSB";
CM_ SG_ 835 StatusCPDData3FBD_MM_CIRData54 "contains CPD data to tap 14 - imaginary part MSB";
CM_ SG_ 835 StatusCPDData3FBD_MM_CIRData55 "contains CPD data to tap 14 - imaginary part LSB";
CM_ SG_ 835 StatusCPDData3FBD_MM_CIRData56 "contains CPD data to tap 15 - real part MSB";
CM_ SG_ 835 StatusCPDData3FBD_MM_CIRData57 "contains CPD data to tap 15 - real part LSB";
CM_ SG_ 835 StatusCPDData3FBD_MM_CIRData58 "contains CPD data to tap 15 - imaginary part MSB";
CM_ SG_ 835 StatusCPDData3FBD_MM_CIRData59 "contains CPD data to tap 15 - imaginary part LSB";
CM_ SG_ 353 StatusCPDData3FBD_Trunk_MsgCount "contains counter";
CM_ SG_ 353 StatusCPDData3FBD_Trunk_LinkID "contains link ID";
CM_ SG_ 353 StatusCPDData3FBD_Trunk_AGCValue "contains AGC value";
CM_ SG_ 353 StatusCPDData3FBD_Trunk_Channel "contains channel";
CM_ SG_ 353 StatusCPDData3FBD_Trunk_CIRData0 "contains CPD data to tap 1 - real part MSB";
CM_ SG_ 353 StatusCPDData3FBD_Trunk_CIRDat_2 "contains CPD data to tap 1 - real part LSB";
CM_ SG_ 353 StatusCPDData3FBD_Trunk_CIRDat_3 "contains CPD data to tap 1 - imaginary part MSB";
CM_ SG_ 353 StatusCPDData3FBD_Trunk_CIRDat_4 "contains CPD data to tap 1 - imaginary part LSB";
CM_ SG_ 353 StatusCPDData3FBD_Trunk_CIRDat_5 "contains CPD data to tap 2 - real part MSB";
CM_ SG_ 353 StatusCPDData3FBD_Trunk_CIRDat_6 "contains CPD data to tap 2 - real part LSB";
CM_ SG_ 353 StatusCPDData3FBD_Trunk_CIRDat_7 "contains CPD data to tap 2 - imaginary part MSB";
CM_ SG_ 353 StatusCPDData3FBD_Trunk_CIRDat_8 "contains CPD data to tap 2 - imaginary part LSB";
CM_ SG_ 353 StatusCPDData3FBD_Trunk_CIRDat_9 "contains CPD data to tap 3 - real part MSB";
CM_ SG_ 353 StatusCPDData3FBD_Trunk_CIRDa_10 "contains CPD data to tap 3 - real part LSB";
CM_ SG_ 353 StatusCPDData3FBD_Trunk_CIRData1 "contains CPD data to tap 3 - imaginary part MSB";
CM_ SG_ 353 StatusCPDData3FBD_Trunk_CIRDa_11 "contains CPD data to tap 3 - imaginary part LSB";
CM_ SG_ 353 StatusCPDData3FBD_Trunk_CIRDa_12 "contains CPD data to tap 4 - real part MSB";
CM_ SG_ 353 StatusCPDData3FBD_Trunk_CIRDa_13 "contains CPD data to tap 4 - real part LSB";
CM_ SG_ 353 StatusCPDData3FBD_Trunk_CIRDa_14 "contains CPD data to tap 4 - imaginary part MSB";
CM_ SG_ 353 StatusCPDData3FBD_Trunk_CIRDa_15 "contains CPD data to tap 4 - imaginary part LSB";
CM_ SG_ 353 StatusCPDData3FBD_Trunk_CIRDa_16 "contains CPD data to tap 5 - real part MSB";
CM_ SG_ 353 StatusCPDData3FBD_Trunk_CIRDa_17 "contains CPD data to tap 5 - real part LSB";
CM_ SG_ 353 StatusCPDData3FBD_Trunk_CIRDa_18 "contains CPD data to tap 5 - imaginary part MSB";
CM_ SG_ 353 StatusCPDData3FBD_Trunk_CIRDa_19 "contains CPD data to tap 5 - imaginary part LSB";
CM_ SG_ 353 StatusCPDData3FBD_Trunk_CIRData2 "contains CPD data to tap 6 - real part MSB";
CM_ SG_ 353 StatusCPDData3FBD_Trunk_CIRDa_20 "contains CPD data to tap 6 - real part LSB";
CM_ SG_ 353 StatusCPDData3FBD_Trunk_CIRDa_21 "contains CPD data to tap 6 - imaginary part MSB";
CM_ SG_ 353 StatusCPDData3FBD_Trunk_CIRDa_22 "contains CPD data to tap 6 - imaginary part LSB";
CM_ SG_ 353 StatusCPDData3FBD_Trunk_CIRDa_23 "contains CPD data to tap 7 - real part MSB";
CM_ SG_ 353 StatusCPDData3FBD_Trunk_CIRDa_24 "contains CPD data to tap 7 - real part LSB";
CM_ SG_ 353 StatusCPDData3FBD_Trunk_CIRDa_25 "contains CPD data to tap 7 - imaginary part MSB";
CM_ SG_ 353 StatusCPDData3FBD_Trunk_CIRDa_26 "contains CPD data to tap 7 - imaginary part LSB";
CM_ SG_ 353 StatusCPDData3FBD_Trunk_CIRDa_27 "contains CPD data to tap 8 - real part MSB";
CM_ SG_ 353 StatusCPDData3FBD_Trunk_CIRDa_28 "contains CPD data to tap 8 - real part LSB";
CM_ SG_ 353 StatusCPDData3FBD_Trunk_CIRData3 "contains CPD data to tap 8 - imaginary part MSB";
CM_ SG_ 353 StatusCPDData3FBD_Trunk_CIRDa_29 "contains CPD data to tap 8 - imaginary part LSB";
CM_ SG_ 353 StatusCPDData3FBD_Trunk_CIRDa_30 "contains CPD data to tap 9 - real part MSB";
CM_ SG_ 353 StatusCPDData3FBD_Trunk_CIRDa_31 "contains CPD data to tap 9 - real part LSB";
CM_ SG_ 353 StatusCPDData3FBD_Trunk_CIRDa_32 "contains CPD data to tap 9 - imaginary part MSB";
CM_ SG_ 353 StatusCPDData3FBD_Trunk_CIRDa_33 "contains CPD data to tap 9 - imaginary part LSB";
CM_ SG_ 353 StatusCPDData3FBD_Trunk_CIRDa_34 "contains CPD data to tap 10 - real part MSB";
CM_ SG_ 353 StatusCPDData3FBD_Trunk_CIRDa_35 "contains CPD data to tap 10 - real part LSB";
CM_ SG_ 353 StatusCPDData3FBD_Trunk_CIRDa_36 "contains CPD data to tap 10 - imaginary part MSB";
CM_ SG_ 353 StatusCPDData3FBD_Trunk_CIRDa_37 "contains CPD data to tap 10 - imaginary part LSB";
CM_ SG_ 353 StatusCPDData3FBD_Trunk_CIRData4 "contains CPD data to tap 11 - real part MSB";
CM_ SG_ 353 StatusCPDData3FBD_Trunk_CIRDa_38 "contains CPD data to tap 11 - real part LSB";
CM_ SG_ 353 StatusCPDData3FBD_Trunk_CIRDa_39 "contains CPD data to tap 11 - imaginary part MSB";
CM_ SG_ 353 StatusCPDData3FBD_Trunk_CIRDa_40 "contains CPD data to tap 11 - imaginary part LSB";
CM_ SG_ 353 StatusCPDData3FBD_Trunk_CIRDa_41 "contains CPD data to tap 12 - real part MSB";
CM_ SG_ 353 StatusCPDData3FBD_Trunk_CIRDa_42 "contains CPD data to tap 12 - real part LSB";
CM_ SG_ 353 StatusCPDData3FBD_Trunk_CIRDa_43 "contains CPD data to tap 12 - imaginary part MSB";
CM_ SG_ 353 StatusCPDData3FBD_Trunk_CIRDa_44 "contains CPD data to tap 12 - imaginary part LSB";
CM_ SG_ 353 StatusCPDData3FBD_Trunk_CIRDa_45 "contains CPD data to tap 13 - real part MSB";
CM_ SG_ 353 StatusCPDData3FBD_Trunk_CIRDa_46 "contains CPD data to tap 13 - real part LSB";
CM_ SG_ 353 StatusCPDData3FBD_Trunk_CIRData5 "contains CPD data to tap 13 - imaginary part MSB";
CM_ SG_ 353 StatusCPDData3FBD_Trunk_CIRDa_47 "contains CPD data to tap 13 - imaginary part LSB";
CM_ SG_ 353 StatusCPDData3FBD_Trunk_CIRDa_48 "contains CPD data to tap 14 - real part MSB";
CM_ SG_ 353 StatusCPDData3FBD_Trunk_CIRDa_49 "contains CPD data to tap 14 - real part LSB";
CM_ SG_ 353 StatusCPDData3FBD_Trunk_CIRDa_50 "contains CPD data to tap 14 - imaginary part MSB";
CM_ SG_ 353 StatusCPDData3FBD_Trunk_CIRDa_51 "contains CPD data to tap 14 - imaginary part LSB";
CM_ SG_ 353 StatusCPDData3FBD_Trunk_CIRDa_52 "contains CPD data to tap 15 - real part MSB";
CM_ SG_ 353 StatusCPDData3FBD_Trunk_CIRDa_53 "contains CPD data to tap 15 - real part LSB";
CM_ SG_ 353 StatusCPDData3FBD_Trunk_CIRDa_54 "contains CPD data to tap 15 - imaginary part MSB";
CM_ SG_ 353 StatusCPDData3FBD_Trunk_CIRDa_55 "contains CPD data to tap 15 - imaginary part LSB";
CM_ SG_ 354 StatusCPDData3FBD_VL_MsgCounter "contains counter";
CM_ SG_ 354 StatusCPDData3FBD_VL_LinkID "contains link ID";
CM_ SG_ 354 StatusCPDData3FBD_VL_AGCValue "contains AGC value";
CM_ SG_ 354 StatusCPDData3FBD_VL_Channel "contains channel";
CM_ SG_ 354 StatusCPDData3FBD_VL_CIRData00 "contains CPD data to tap 1 - real part MSB";
CM_ SG_ 354 StatusCPDData3FBD_VL_CIRData01 "contains CPD data to tap 1 - real part LSB";
CM_ SG_ 354 StatusCPDData3FBD_VL_CIRData02 "contains CPD data to tap 1 - imaginary part MSB";
CM_ SG_ 354 StatusCPDData3FBD_VL_CIRData03 "contains CPD data to tap 1 - imaginary part LSB";
CM_ SG_ 354 StatusCPDData3FBD_VL_CIRData04 "contains CPD data to tap 2 - real part MSB";
CM_ SG_ 354 StatusCPDData3FBD_VL_CIRData05 "contains CPD data to tap 2 - real part LSB";
CM_ SG_ 354 StatusCPDData3FBD_VL_CIRData06 "contains CPD data to tap 2 - imaginary part MSB";
CM_ SG_ 354 StatusCPDData3FBD_VL_CIRData07 "contains CPD data to tap 2 - imaginary part LSB";
CM_ SG_ 354 StatusCPDData3FBD_VL_CIRData08 "contains CPD data to tap 3 - real part MSB";
CM_ SG_ 354 StatusCPDData3FBD_VL_CIRData09 "contains CPD data to tap 3 - real part LSB";
CM_ SG_ 354 StatusCPDData3FBD_VL_CIRData10 "contains CPD data to tap 3 - imaginary part MSB";
CM_ SG_ 354 StatusCPDData3FBD_VL_CIRData11 "contains CPD data to tap 3 - imaginary part LSB";
CM_ SG_ 354 StatusCPDData3FBD_VL_CIRData12 "contains CPD data to tap 4 - real part MSB";
CM_ SG_ 354 StatusCPDData3FBD_VL_CIRData13 "contains CPD data to tap 4 - real part LSB";
CM_ SG_ 354 StatusCPDData3FBD_VL_CIRData14 "contains CPD data to tap 4 - imaginary part MSB";
CM_ SG_ 354 StatusCPDData3FBD_VL_CIRData15 "contains CPD data to tap 4 - imaginary part LSB";
CM_ SG_ 354 StatusCPDData3FBD_VL_CIRData16 "contains CPD data to tap 5 - real part MSB";
CM_ SG_ 354 StatusCPDData3FBD_VL_CIRData17 "contains CPD data to tap 5 - real part LSB";
CM_ SG_ 354 StatusCPDData3FBD_VL_CIRData18 "contains CPD data to tap 5 - imaginary part MSB";
CM_ SG_ 354 StatusCPDData3FBD_VL_CIRData19 "contains CPD data to tap 5 - imaginary part LSB";
CM_ SG_ 354 StatusCPDData3FBD_VL_CIRData20 "contains CPD data to tap 6 - real part MSB";
CM_ SG_ 354 StatusCPDData3FBD_VL_CIRData21 "contains CPD data to tap 6 - real part LSB";
CM_ SG_ 354 StatusCPDData3FBD_VL_CIRData22 "contains CPD data to tap 6 - imaginary part MSB";
CM_ SG_ 354 StatusCPDData3FBD_VL_CIRData23 "contains CPD data to tap 6 - imaginary part LSB";
CM_ SG_ 354 StatusCPDData3FBD_VL_CIRData24 "contains CPD data to tap 7 - real part MSB";
CM_ SG_ 354 StatusCPDData3FBD_VL_CIRData25 "contains CPD data to tap 7 - real part LSB";
CM_ SG_ 354 StatusCPDData3FBD_VL_CIRData26 "contains CPD data to tap 7 - imaginary part MSB";
CM_ SG_ 354 StatusCPDData3FBD_VL_CIRData27 "contains CPD data to tap 7 - imaginary part LSB";
CM_ SG_ 354 StatusCPDData3FBD_VL_CIRData28 "contains CPD data to tap 8 - real part MSB";
CM_ SG_ 354 StatusCPDData3FBD_VL_CIRData29 "contains CPD data to tap 8 - real part LSB";
CM_ SG_ 354 StatusCPDData3FBD_VL_CIRData30 "contains CPD data to tap 8 - imaginary part MSB";
CM_ SG_ 354 StatusCPDData3FBD_VL_CIRData31 "contains CPD data to tap 8 - imaginary part LSB";
CM_ SG_ 354 StatusCPDData3FBD_VL_CIRData32 "contains CPD data to tap 9 - real part MSB";
CM_ SG_ 354 StatusCPDData3FBD_VL_CIRData33 "contains CPD data to tap 9 - real part LSB";
CM_ SG_ 354 StatusCPDData3FBD_VL_CIRData34 "contains CPD data to tap 9 - imaginary part MSB";
CM_ SG_ 354 StatusCPDData3FBD_VL_CIRData35 "contains CPD data to tap 9 - imaginary part LSB";
CM_ SG_ 354 StatusCPDData3FBD_VL_CIRData36 "contains CPD data to tap 10 - real part MSB";
CM_ SG_ 354 StatusCPDData3FBD_VL_CIRData37 "contains CPD data to tap 10 - real part LSB";
CM_ SG_ 354 StatusCPDData3FBD_VL_CIRData38 "contains CPD data to tap 10 - imaginary part MSB";
CM_ SG_ 354 StatusCPDData3FBD_VL_CIRData39 "contains CPD data to tap 10 - imaginary part LSB";
CM_ SG_ 354 StatusCPDData3FBD_VL_CIRData40 "contains CPD data to tap 11 - real part MSB";
CM_ SG_ 354 StatusCPDData3FBD_VL_CIRData41 "contains CPD data to tap 11 - real part LSB";
CM_ SG_ 354 StatusCPDData3FBD_VL_CIRData42 "contains CPD data to tap 11 - imaginary part MSB";
CM_ SG_ 354 StatusCPDData3FBD_VL_CIRData43 "contains CPD data to tap 11 - imaginary part LSB";
CM_ SG_ 354 StatusCPDData3FBD_VL_CIRData44 "contains CPD data to tap 12 - real part MSB";
CM_ SG_ 354 StatusCPDData3FBD_VL_CIRData45 "contains CPD data to tap 12 - real part LSB";
CM_ SG_ 354 StatusCPDData3FBD_VL_CIRData46 "contains CPD data to tap 12 - imaginary part MSB";
CM_ SG_ 354 StatusCPDData3FBD_VL_CIRData47 "contains CPD data to tap 12 - imaginary part LSB";
CM_ SG_ 354 StatusCPDData3FBD_VL_CIRData48 "contains CPD data to tap 13 - real part MSB";
CM_ SG_ 354 StatusCPDData3FBD_VL_CIRData49 "contains CPD data to tap 13 - real part LSB";
CM_ SG_ 354 StatusCPDData3FBD_VL_CIRData50 "contains CPD data to tap 13 - imaginary part MSB";
CM_ SG_ 354 StatusCPDData3FBD_VL_CIRData51 "contains CPD data to tap 13 - imaginary part LSB";
CM_ SG_ 354 StatusCPDData3FBD_VL_CIRData52 "contains CPD data to tap 14 - real part MSB";
CM_ SG_ 354 StatusCPDData3FBD_VL_CIRData53 "contains CPD data to tap 14 - real part LSB";
CM_ SG_ 354 StatusCPDData3FBD_VL_CIRData54 "contains CPD data to tap 14 - imaginary part MSB";
CM_ SG_ 354 StatusCPDData3FBD_VL_CIRData55 "contains CPD data to tap 14 - imaginary part LSB";
CM_ SG_ 354 StatusCPDData3FBD_VL_CIRData56 "contains CPD data to tap 15 - real part MSB";
CM_ SG_ 354 StatusCPDData3FBD_VL_CIRData57 "contains CPD data to tap 15 - real part LSB";
CM_ SG_ 354 StatusCPDData3FBD_VL_CIRData58 "contains CPD data to tap 15 - imaginary part MSB";
CM_ SG_ 354 StatusCPDData3FBD_VL_CIRData59 "contains CPD data to tap 15 - imaginary part LSB";
CM_ SG_ 350 StatusCPDData3FBD_VM_MsgCounter "contains counter";
CM_ SG_ 350 StatusCPDData3FBD_VM_LinkID "contains link ID";
CM_ SG_ 350 StatusCPDData3FBD_VM_AGCValue "contains AGC value";
CM_ SG_ 350 StatusCPDData3FBD_VM_Channel "contains channel";
CM_ SG_ 350 StatusCPDData3FBD_VM_CIRData00 "contains CPD data to tap 1 - real part MSB";
CM_ SG_ 350 StatusCPDData3FBD_VM_CIRData01 "contains CPD data to tap 1 - real part LSB";
CM_ SG_ 350 StatusCPDData3FBD_VM_CIRData02 "contains CPD data to tap 1 - imaginary part MSB";
CM_ SG_ 350 StatusCPDData3FBD_VM_CIRData03 "contains CPD data to tap 1 - imaginary part LSB";
CM_ SG_ 350 StatusCPDData3FBD_VM_CIRData04 "contains CPD data to tap 2 - real part MSB";
CM_ SG_ 350 StatusCPDData3FBD_VM_CIRData05 "contains CPD data to tap 2 - real part LSB";
CM_ SG_ 350 StatusCPDData3FBD_VM_CIRData06 "contains CPD data to tap 2 - imaginary part MSB";
CM_ SG_ 350 StatusCPDData3FBD_VM_CIRData07 "contains CPD data to tap 2 - imaginary part LSB";
CM_ SG_ 350 StatusCPDData3FBD_VM_CIRData08 "contains CPD data to tap 3 - real part MSB";
CM_ SG_ 350 StatusCPDData3FBD_VM_CIRData09 "contains CPD data to tap 3 - real part LSB";
CM_ SG_ 350 StatusCPDData3FBD_VM_CIRData10 "contains CPD data to tap 3 - imaginary part MSB";
CM_ SG_ 350 StatusCPDData3FBD_VM_CIRData11 "contains CPD data to tap 3 - imaginary part LSB";
CM_ SG_ 350 StatusCPDData3FBD_VM_CIRData12 "contains CPD data to tap 4 - real part MSB";
CM_ SG_ 350 StatusCPDData3FBD_VM_CIRData13 "contains CPD data to tap 4 - real part LSB";
CM_ SG_ 350 StatusCPDData3FBD_VM_CIRData14 "contains CPD data to tap 4 - imaginary part MSB";
CM_ SG_ 350 StatusCPDData3FBD_VM_CIRData15 "contains CPD data to tap 4 - imaginary part LSB";
CM_ SG_ 350 StatusCPDData3FBD_VM_CIRData16 "contains CPD data to tap 5 - real part MSB";
CM_ SG_ 350 StatusCPDData3FBD_VM_CIRData17 "contains CPD data to tap 5 - real part LSB";
CM_ SG_ 350 StatusCPDData3FBD_VM_CIRData18 "contains CPD data to tap 5 - imaginary part MSB";
CM_ SG_ 350 StatusCPDData3FBD_VM_CIRData19 "contains CPD data to tap 5 - imaginary part LSB";
CM_ SG_ 350 StatusCPDData3FBD_VM_CIRData20 "contains CPD data to tap 6 - real part MSB";
CM_ SG_ 350 StatusCPDData3FBD_VM_CIRData21 "contains CPD data to tap 6 - real part LSB";
CM_ SG_ 350 StatusCPDData3FBD_VM_CIRData22 "contains CPD data to tap 6 - imaginary part MSB";
CM_ SG_ 350 StatusCPDData3FBD_VM_CIRData23 "contains CPD data to tap 6 - imaginary part LSB";
CM_ SG_ 350 StatusCPDData3FBD_VM_CIRData24 "contains CPD data to tap 7 - real part MSB";
CM_ SG_ 350 StatusCPDData3FBD_VM_CIRData25 "contains CPD data to tap 7 - real part LSB";
CM_ SG_ 350 StatusCPDData3FBD_VM_CIRData26 "contains CPD data to tap 7 - imaginary part MSB";
CM_ SG_ 350 StatusCPDData3FBD_VM_CIRData27 "contains CPD data to tap 7 - imaginary part LSB";
CM_ SG_ 350 StatusCPDData3FBD_VM_CIRData28 "contains CPD data to tap 8 - real part MSB";
CM_ SG_ 350 StatusCPDData3FBD_VM_CIRData29 "contains CPD data to tap 8 - real part LSB";
CM_ SG_ 350 StatusCPDData3FBD_VM_CIRData30 "contains CPD data to tap 8 - imaginary part MSB";
CM_ SG_ 350 StatusCPDData3FBD_VM_CIRData31 "contains CPD data to tap 8 - imaginary part LSB";
CM_ SG_ 350 StatusCPDData3FBD_VM_CIRData32 "contains CPD data to tap 9 - real part MSB";
CM_ SG_ 350 StatusCPDData3FBD_VM_CIRData33 "contains CPD data to tap 9 - real part LSB";
CM_ SG_ 350 StatusCPDData3FBD_VM_CIRData34 "contains CPD data to tap 9 - imaginary part MSB";
CM_ SG_ 350 StatusCPDData3FBD_VM_CIRData35 "contains CPD data to tap 9 - imaginary part LSB";
CM_ SG_ 350 StatusCPDData3FBD_VM_CIRData36 "contains CPD data to tap 10 - real part MSB";
CM_ SG_ 350 StatusCPDData3FBD_VM_CIRData37 "contains CPD data to tap 10 - real part LSB";
CM_ SG_ 350 StatusCPDData3FBD_VM_CIRData38 "contains CPD data to tap 10 - imaginary part MSB";
CM_ SG_ 350 StatusCPDData3FBD_VM_CIRData39 "contains CPD data to tap 10 - imaginary part LSB";
CM_ SG_ 350 StatusCPDData3FBD_VM_CIRData40 "contains CPD data to tap 11 - real part MSB";
CM_ SG_ 350 StatusCPDData3FBD_VM_CIRData41 "contains CPD data to tap 11 - real part LSB";
CM_ SG_ 350 StatusCPDData3FBD_VM_CIRData42 "contains CPD data to tap 11 - imaginary part MSB";
CM_ SG_ 350 StatusCPDData3FBD_VM_CIRData43 "contains CPD data to tap 11 - imaginary part LSB";
CM_ SG_ 350 StatusCPDData3FBD_VM_CIRData44 "contains CPD data to tap 12 - real part MSB";
CM_ SG_ 350 StatusCPDData3FBD_VM_CIRData45 "contains CPD data to tap 12 - real part LSB";
CM_ SG_ 350 StatusCPDData3FBD_VM_CIRData46 "contains CPD data to tap 12 - imaginary part MSB";
CM_ SG_ 350 StatusCPDData3FBD_VM_CIRData47 "contains CPD data to tap 12 - imaginary part LSB";
CM_ SG_ 350 StatusCPDData3FBD_VM_CIRData48 "contains CPD data to tap 13 - real part MSB";
CM_ SG_ 350 StatusCPDData3FBD_VM_CIRData49 "contains CPD data to tap 13 - real part LSB";
CM_ SG_ 350 StatusCPDData3FBD_VM_CIRData50 "contains CPD data to tap 13 - imaginary part MSB";
CM_ SG_ 350 StatusCPDData3FBD_VM_CIRData51 "contains CPD data to tap 13 - imaginary part LSB";
CM_ SG_ 350 StatusCPDData3FBD_VM_CIRData52 "contains CPD data to tap 14 - real part MSB";
CM_ SG_ 350 StatusCPDData3FBD_VM_CIRData53 "contains CPD data to tap 14 - real part LSB";
CM_ SG_ 350 StatusCPDData3FBD_VM_CIRData54 "contains CPD data to tap 14 - imaginary part MSB";
CM_ SG_ 350 StatusCPDData3FBD_VM_CIRData55 "contains CPD data to tap 14 - imaginary part LSB";
CM_ SG_ 350 StatusCPDData3FBD_VM_CIRData56 "contains CPD data to tap 15 - real part MSB";
CM_ SG_ 350 StatusCPDData3FBD_VM_CIRData57 "contains CPD data to tap 15 - real part LSB";
CM_ SG_ 350 StatusCPDData3FBD_VM_CIRData58 "contains CPD data to tap 15 - imaginary part MSB";
CM_ SG_ 350 StatusCPDData3FBD_VM_CIRData59 "contains CPD data to tap 15 - imaginary part LSB";
CM_ SG_ 355 StatusCPDData3FBD_VR_MsgCounter "contains counter";
CM_ SG_ 355 StatusCPDData3FBD_VR_LinkID "contains link ID";
CM_ SG_ 355 StatusCPDData3FBD_VR_AGCValue "contains AGC value";
CM_ SG_ 355 StatusCPDData3FBD_VR_Channel "contains channel";
CM_ SG_ 355 StatusCPDData3FBD_VR_CIRData00 "contains CPD data to tap 1 - real part MSB";
CM_ SG_ 355 StatusCPDData3FBD_VR_CIRData01 "contains CPD data to tap 1 - real part LSB";
CM_ SG_ 355 StatusCPDData3FBD_VR_CIRData02 "contains CPD data to tap 1 - imaginary part MSB";
CM_ SG_ 355 StatusCPDData3FBD_VR_CIRData03 "contains CPD data to tap 1 - imaginary part LSB";
CM_ SG_ 355 StatusCPDData3FBD_VR_CIRData04 "contains CPD data to tap 2 - real part MSB";
CM_ SG_ 355 StatusCPDData3FBD_VR_CIRData05 "contains CPD data to tap 2 - real part LSB";
CM_ SG_ 355 StatusCPDData3FBD_VR_CIRData06 "contains CPD data to tap 2 - imaginary part MSB";
CM_ SG_ 355 StatusCPDData3FBD_VR_CIRData07 "contains CPD data to tap 2 - imaginary part LSB";
CM_ SG_ 355 StatusCPDData3FBD_VR_CIRData08 "contains CPD data to tap 3 - real part MSB";
CM_ SG_ 355 StatusCPDData3FBD_VR_CIRData09 "contains CPD data to tap 3 - real part LSB";
CM_ SG_ 355 StatusCPDData3FBD_VR_CIRData10 "contains CPD data to tap 3 - imaginary part MSB";
CM_ SG_ 355 StatusCPDData3FBD_VR_CIRData11 "contains CPD data to tap 3 - imaginary part LSB";
CM_ SG_ 355 StatusCPDData3FBD_VR_CIRData12 "contains CPD data to tap 4 - real part MSB";
CM_ SG_ 355 StatusCPDData3FBD_VR_CIRData13 "contains CPD data to tap 4 - real part LSB";
CM_ SG_ 355 StatusCPDData3FBD_VR_CIRData14 "contains CPD data to tap 4 - imaginary part MSB";
CM_ SG_ 355 StatusCPDData3FBD_VR_CIRData15 "contains CPD data to tap 4 - imaginary part LSB";
CM_ SG_ 355 StatusCPDData3FBD_VR_CIRData16 "contains CPD data to tap 5 - real part MSB";
CM_ SG_ 355 StatusCPDData3FBD_VR_CIRData17 "contains CPD data to tap 5 - real part LSB";
CM_ SG_ 355 StatusCPDData3FBD_VR_CIRData18 "contains CPD data to tap 5 - imaginary part MSB";
CM_ SG_ 355 StatusCPDData3FBD_VR_CIRData19 "contains CPD data to tap 5 - imaginary part LSB";
CM_ SG_ 355 StatusCPDData3FBD_VR_CIRData20 "contains CPD data to tap 6 - real part MSB";
CM_ SG_ 355 StatusCPDData3FBD_VR_CIRData21 "contains CPD data to tap 6 - real part LSB";
CM_ SG_ 355 StatusCPDData3FBD_VR_CIRData22 "contains CPD data to tap 6 - imaginary part MSB";
CM_ SG_ 355 StatusCPDData3FBD_VR_CIRData23 "contains CPD data to tap 6 - imaginary part LSB";
CM_ SG_ 355 StatusCPDData3FBD_VR_CIRData24 "contains CPD data to tap 7 - real part MSB";
CM_ SG_ 355 StatusCPDData3FBD_VR_CIRData25 "contains CPD data to tap 7 - real part LSB";
CM_ SG_ 355 StatusCPDData3FBD_VR_CIRData26 "contains CPD data to tap 7 - imaginary part MSB";
CM_ SG_ 355 StatusCPDData3FBD_VR_CIRData27 "contains CPD data to tap 7 - imaginary part LSB";
CM_ SG_ 355 StatusCPDData3FBD_VR_CIRData28 "contains CPD data to tap 8 - real part MSB";
CM_ SG_ 355 StatusCPDData3FBD_VR_CIRData29 "contains CPD data to tap 8 - real part LSB";
CM_ SG_ 355 StatusCPDData3FBD_VR_CIRData30 "contains CPD data to tap 8 - imaginary part MSB";
CM_ SG_ 355 StatusCPDData3FBD_VR_CIRData31 "contains CPD data to tap 8 - imaginary part LSB";
CM_ SG_ 355 StatusCPDData3FBD_VR_CIRData32 "contains CPD data to tap 9 - real part MSB";
CM_ SG_ 355 StatusCPDData3FBD_VR_CIRData33 "contains CPD data to tap 9 - real part LSB";
CM_ SG_ 355 StatusCPDData3FBD_VR_CIRData34 "contains CPD data to tap 9 - imaginary part MSB";
CM_ SG_ 355 StatusCPDData3FBD_VR_CIRData35 "contains CPD data to tap 9 - imaginary part LSB";
CM_ SG_ 355 StatusCPDData3FBD_VR_CIRData36 "contains CPD data to tap 10 - real part MSB";
CM_ SG_ 355 StatusCPDData3FBD_VR_CIRData37 "contains CPD data to tap 10 - real part LSB";
CM_ SG_ 355 StatusCPDData3FBD_VR_CIRData38 "contains CPD data to tap 10 - imaginary part MSB";
CM_ SG_ 355 StatusCPDData3FBD_VR_CIRData39 "contains CPD data to tap 10 - imaginary part LSB";
CM_ SG_ 355 StatusCPDData3FBD_VR_CIRData40 "contains CPD data to tap 11 - real part MSB";
CM_ SG_ 355 StatusCPDData3FBD_VR_CIRData41 "contains CPD data to tap 11 - real part LSB";
CM_ SG_ 355 StatusCPDData3FBD_VR_CIRData42 "contains CPD data to tap 11 - imaginary part MSB";
CM_ SG_ 355 StatusCPDData3FBD_VR_CIRData43 "contains CPD data to tap 11 - imaginary part LSB";
CM_ SG_ 355 StatusCPDData3FBD_VR_CIRData44 "contains CPD data to tap 12 - real part MSB";
CM_ SG_ 355 StatusCPDData3FBD_VR_CIRData45 "contains CPD data to tap 12 - real part LSB";
CM_ SG_ 355 StatusCPDData3FBD_VR_CIRData46 "contains CPD data to tap 12 - imaginary part MSB";
CM_ SG_ 355 StatusCPDData3FBD_VR_CIRData47 "contains CPD data to tap 12 - imaginary part LSB";
CM_ SG_ 355 StatusCPDData3FBD_VR_CIRData48 "contains CPD data to tap 13 - real part MSB";
CM_ SG_ 355 StatusCPDData3FBD_VR_CIRData49 "contains CPD data to tap 13 - real part LSB";
CM_ SG_ 355 StatusCPDData3FBD_VR_CIRData50 "contains CPD data to tap 13 - imaginary part MSB";
CM_ SG_ 355 StatusCPDData3FBD_VR_CIRData51 "contains CPD data to tap 13 - imaginary part LSB";
CM_ SG_ 355 StatusCPDData3FBD_VR_CIRData52 "contains CPD data to tap 14 - real part MSB";
CM_ SG_ 355 StatusCPDData3FBD_VR_CIRData53 "contains CPD data to tap 14 - real part LSB";
CM_ SG_ 355 StatusCPDData3FBD_VR_CIRData54 "contains CPD data to tap 14 - imaginary part MSB";
CM_ SG_ 355 StatusCPDData3FBD_VR_CIRData55 "contains CPD data to tap 14 - imaginary part LSB";
CM_ SG_ 355 StatusCPDData3FBD_VR_CIRData56 "contains CPD data to tap 15 - real part MSB";
CM_ SG_ 355 StatusCPDData3FBD_VR_CIRData57 "contains CPD data to tap 15 - real part LSB";
CM_ SG_ 355 StatusCPDData3FBD_VR_CIRData58 "contains CPD data to tap 15 - imaginary part MSB";
CM_ SG_ 355 StatusCPDData3FBD_VR_CIRData59 "contains CPD data to tap 15 - imaginary part LSB";
CM_ SG_ 366 StatusCPDData4FBD_HL_MsgCounter "contains counter";
CM_ SG_ 366 StatusCPDData4FBD_HL_LinkID "contains link ID";
CM_ SG_ 366 StatusCPDData4FBD_HL_CollisionCo "contains collision counter";
CM_ SG_ 366 StatusCPDData4FBD_HL_CIRSetting "contains CIR Settings";
CM_ SG_ 366 StatusCPDData4FBD_HL_CIRData60 "contains CPD data to tap 16 - real part MSB";
CM_ SG_ 366 StatusCPDData4FBD_HL_CIRData61 "contains CPD data to tap 16 - real part LSB";
CM_ SG_ 366 StatusCPDData4FBD_HL_CIRData62 "contains CPD data to tap 16 - imaginary part MSB";
CM_ SG_ 366 StatusCPDData4FBD_HL_CIRData63 "contains CPD data to tap 16 - imaginary part LSB";
CM_ SG_ 366 StatusCPDData4FBD_HL_CIRData64 "contains CPD data to tap 17 - real part MSB";
CM_ SG_ 366 StatusCPDData4FBD_HL_CIRData65 "contains CPD data to tap 17 - real part LSB";
CM_ SG_ 366 StatusCPDData4FBD_HL_CIRData66 "contains CPD data to tap 17 - imaginary part MSB";
CM_ SG_ 366 StatusCPDData4FBD_HL_CIRData67 "contains CPD data to tap 17 - imaginary part LSB";
CM_ SG_ 366 StatusCPDData4FBD_HL_CIRData68 "contains CPD data to tap 18 - real part MSB";
CM_ SG_ 366 StatusCPDData4FBD_HL_CIRData69 "contains CPD data to tap 18 - real part LSB";
CM_ SG_ 366 StatusCPDData4FBD_HL_CIRData70 "contains CPD data to tap 18 - imaginary part MSB";
CM_ SG_ 366 StatusCPDData4FBD_HL_CIRData71 "contains CPD data to tap 18 - imaginary part LSB";
CM_ SG_ 366 StatusCPDData4FBD_HL_CIRData72 "contains CPD data to tap 19 - real part MSB";
CM_ SG_ 366 StatusCPDData4FBD_HL_CIRData73 "contains CPD data to tap 19 - real part LSB";
CM_ SG_ 366 StatusCPDData4FBD_HL_CIRData74 "contains CPD data to tap 19 - imaginary part MSB";
CM_ SG_ 366 StatusCPDData4FBD_HL_CIRData75 "contains CPD data to tap 19 - imaginary part LSB";
CM_ SG_ 366 StatusCPDData4FBD_HL_CIRData76 "contains CPD data to tap 20 - real part MSB";
CM_ SG_ 366 StatusCPDData4FBD_HL_CIRData77 "contains CPD data to tap 20 - real part LSB";
CM_ SG_ 366 StatusCPDData4FBD_HL_CIRData78 "contains CPD data to tap 20 - imaginary part MSB";
CM_ SG_ 366 StatusCPDData4FBD_HL_CIRData79 "contains CPD data to tap 20 - imaginary part LSB";
CM_ SG_ 366 StatusCPDData4FBD_HL_CIRData80 "contains CPD data to tap 21 - real part MSB";
CM_ SG_ 366 StatusCPDData4FBD_HL_CIRData81 "contains CPD data to tap 21 - real part LSB";
CM_ SG_ 366 StatusCPDData4FBD_HL_CIRData82 "contains CPD data to tap 21 - imaginary part MSB";
CM_ SG_ 366 StatusCPDData4FBD_HL_CIRData83 "contains CPD data to tap 21 - imaginary part LSB";
CM_ SG_ 366 StatusCPDData4FBD_HL_CIRData84 "contains CPD data to tap 22 - real part MSB";
CM_ SG_ 366 StatusCPDData4FBD_HL_CIRData85 "contains CPD data to tap 22 - real part LSB";
CM_ SG_ 366 StatusCPDData4FBD_HL_CIRData86 "contains CPD data to tap 22 - imaginary part MSB";
CM_ SG_ 366 StatusCPDData4FBD_HL_CIRData87 "contains CPD data to tap 22 - imaginary part LSB";
CM_ SG_ 366 StatusCPDData4FBD_HL_CIRData88 "contains CPD data to tap 23 - real part MSB";
CM_ SG_ 366 StatusCPDData4FBD_HL_CIRData89 "contains CPD data to tap 23 - real part LSB";
CM_ SG_ 366 StatusCPDData4FBD_HL_CIRData90 "contains CPD data to tap 23 - imaginary part MSB";
CM_ SG_ 366 StatusCPDData4FBD_HL_CIRData91 "contains CPD data to tap 23 - imaginary part LSB";
CM_ SG_ 366 StatusCPDData4FBD_HL_CIRData92 "contains CPD data to tap 24 - real part MSB";
CM_ SG_ 366 StatusCPDData4FBD_HL_CIRData93 "contains CPD data to tap 24 - real part LSB";
CM_ SG_ 366 StatusCPDData4FBD_HL_CIRData94 "contains CPD data to tap 24 - imaginary part MSB";
CM_ SG_ 366 StatusCPDData4FBD_HL_CIRData95 "contains CPD data to tap 24 - imaginary part LSB";
CM_ SG_ 366 StatusCPDData4FBD_HL_CIRData96 "contains CPD data to tap 25 - real part MSB";
CM_ SG_ 366 StatusCPDData4FBD_HL_CIRData97 "contains CPD data to tap 25 - real part LSB";
CM_ SG_ 366 StatusCPDData4FBD_HL_CIRData98 "contains CPD data to tap 25 - imaginary part MSB";
CM_ SG_ 366 StatusCPDData4FBD_HL_CIRData99 "contains CPD data to tap 25 - imaginary part LSB";
CM_ SG_ 366 StatusCPDData4FBD_HL_CIRData100 "contains CPD data to tap 26 - real part MSB";
CM_ SG_ 366 StatusCPDData4FBD_HL_CIRData101 "contains CPD data to tap 26 - real part LSB";
CM_ SG_ 366 StatusCPDData4FBD_HL_CIRData102 "contains CPD data to tap 26 - imaginary part MSB";
CM_ SG_ 366 StatusCPDData4FBD_HL_CIRData103 "contains CPD data to tap 26 - imaginary part LSB";
CM_ SG_ 366 StatusCPDData4FBD_HL_CIRData104 "contains CPD data to tap 27 - real part MSB";
CM_ SG_ 366 StatusCPDData4FBD_HL_CIRData105 "contains CPD data to tap 27 - real part LSB";
CM_ SG_ 366 StatusCPDData4FBD_HL_CIRData106 "contains CPD data to tap 27 - imaginary part MSB";
CM_ SG_ 366 StatusCPDData4FBD_HL_CIRData107 "contains CPD data to tap 27 - imaginary part LSB";
CM_ SG_ 366 StatusCPDData4FBD_HL_CIRData108 "contains CPD data to tap 28 - real part MSB";
CM_ SG_ 366 StatusCPDData4FBD_HL_CIRData109 "contains CPD data to tap 28 - real part LSB";
CM_ SG_ 366 StatusCPDData4FBD_HL_CIRData110 "contains CPD data to tap 28 - imaginary part MSB";
CM_ SG_ 366 StatusCPDData4FBD_HL_CIRData111 "contains CPD data to tap 28 - imaginary part LSB";
CM_ SG_ 366 StatusCPDData4FBD_HL_CIRData112 "contains CPD data to tap 29 - real part MSB";
CM_ SG_ 366 StatusCPDData4FBD_HL_CIRData113 "contains CPD data to tap 29 - real part LSB";
CM_ SG_ 366 StatusCPDData4FBD_HL_CIRData114 "contains CPD data to tap 29 - imaginary part MSB";
CM_ SG_ 366 StatusCPDData4FBD_HL_CIRData115 "contains CPD data to tap 29 - imaginary part LSB";
CM_ SG_ 366 StatusCPDData4FBD_HL_CIRData116 "contains CPD data to tap 30 - real part MSB";
CM_ SG_ 366 StatusCPDData4FBD_HL_CIRData117 "contains CPD data to tap 30 - real part LSB";
CM_ SG_ 366 StatusCPDData4FBD_HL_CIRData118 "contains CPD data to tap 30 - imaginary part MSB";
CM_ SG_ 366 StatusCPDData4FBD_HL_CIRData119 "contains CPD data to tap 30 - imaginary part LSB";
CM_ SG_ 361 StatusCPDData4FBD_HM_MsgCounter "contains counter";
CM_ SG_ 361 StatusCPDData4FBD_HM_LinkID "contains link ID";
CM_ SG_ 361 StatusCPDData4FBD_HM_CollisionCo "contains collision counter";
CM_ SG_ 361 StatusCPDData4FBD_HM_CIRSetting "contains CIR Settings";
CM_ SG_ 361 StatusCPDData4FBD_HM_CIRData60 "contains CPD data to tap 16 - real part MSB";
CM_ SG_ 361 StatusCPDData4FBD_HM_CIRData61 "contains CPD data to tap 16 - real part LSB";
CM_ SG_ 361 StatusCPDData4FBD_HM_CIRData62 "contains CPD data to tap 16 - imaginary part MSB";
CM_ SG_ 361 StatusCPDData4FBD_HM_CIRData63 "contains CPD data to tap 16 - imaginary part LSB";
CM_ SG_ 361 StatusCPDData4FBD_HM_CIRData64 "contains CPD data to tap 17 - real part MSB";
CM_ SG_ 361 StatusCPDData4FBD_HM_CIRData65 "contains CPD data to tap 17 - real part LSB";
CM_ SG_ 361 StatusCPDData4FBD_HM_CIRData66 "contains CPD data to tap 17 - imaginary part MSB";
CM_ SG_ 361 StatusCPDData4FBD_HM_CIRData67 "contains CPD data to tap 17 - imaginary part LSB";
CM_ SG_ 361 StatusCPDData4FBD_HM_CIRData68 "contains CPD data to tap 18 - real part MSB";
CM_ SG_ 361 StatusCPDData4FBD_HM_CIRData69 "contains CPD data to tap 18 - real part LSB";
CM_ SG_ 361 StatusCPDData4FBD_HM_CIRData70 "contains CPD data to tap 18 - imaginary part MSB";
CM_ SG_ 361 StatusCPDData4FBD_HM_CIRData71 "contains CPD data to tap 18 - imaginary part LSB";
CM_ SG_ 361 StatusCPDData4FBD_HM_CIRData72 "contains CPD data to tap 19 - real part MSB";
CM_ SG_ 361 StatusCPDData4FBD_HM_CIRData73 "contains CPD data to tap 19 - real part LSB";
CM_ SG_ 361 StatusCPDData4FBD_HM_CIRData74 "contains CPD data to tap 19 - imaginary part MSB";
CM_ SG_ 361 StatusCPDData4FBD_HM_CIRData75 "contains CPD data to tap 19 - imaginary part LSB";
CM_ SG_ 361 StatusCPDData4FBD_HM_CIRData76 "contains CPD data to tap 20 - real part MSB";
CM_ SG_ 361 StatusCPDData4FBD_HM_CIRData77 "contains CPD data to tap 20 - real part LSB";
CM_ SG_ 361 StatusCPDData4FBD_HM_CIRData78 "contains CPD data to tap 20 - imaginary part MSB";
CM_ SG_ 361 StatusCPDData4FBD_HM_CIRData79 "contains CPD data to tap 20 - imaginary part LSB";
CM_ SG_ 361 StatusCPDData4FBD_HM_CIRData80 "contains CPD data to tap 21 - real part MSB";
CM_ SG_ 361 StatusCPDData4FBD_HM_CIRData81 "contains CPD data to tap 21 - real part LSB";
CM_ SG_ 361 StatusCPDData4FBD_HM_CIRData82 "contains CPD data to tap 21 - imaginary part MSB";
CM_ SG_ 361 StatusCPDData4FBD_HM_CIRData83 "contains CPD data to tap 21 - imaginary part LSB";
CM_ SG_ 361 StatusCPDData4FBD_HM_CIRData84 "contains CPD data to tap 22 - real part MSB";
CM_ SG_ 361 StatusCPDData4FBD_HM_CIRData85 "contains CPD data to tap 22 - real part LSB";
CM_ SG_ 361 StatusCPDData4FBD_HM_CIRData86 "contains CPD data to tap 22 - imaginary part MSB";
CM_ SG_ 361 StatusCPDData4FBD_HM_CIRData87 "contains CPD data to tap 22 - imaginary part LSB";
CM_ SG_ 361 StatusCPDData4FBD_HM_CIRData88 "contains CPD data to tap 23 - real part MSB";
CM_ SG_ 361 StatusCPDData4FBD_HM_CIRData89 "contains CPD data to tap 23 - real part LSB";
CM_ SG_ 361 StatusCPDData4FBD_HM_CIRData90 "contains CPD data to tap 23 - imaginary part MSB";
CM_ SG_ 361 StatusCPDData4FBD_HM_CIRData91 "contains CPD data to tap 23 - imaginary part LSB";
CM_ SG_ 361 StatusCPDData4FBD_HM_CIRData92 "contains CPD data to tap 24 - real part MSB";
CM_ SG_ 361 StatusCPDData4FBD_HM_CIRData93 "contains CPD data to tap 24 - real part LSB";
CM_ SG_ 361 StatusCPDData4FBD_HM_CIRData94 "contains CPD data to tap 24 - imaginary part MSB";
CM_ SG_ 361 StatusCPDData4FBD_HM_CIRData95 "contains CPD data to tap 24 - imaginary part LSB";
CM_ SG_ 361 StatusCPDData4FBD_HM_CIRData96 "contains CPD data to tap 25 - real part MSB";
CM_ SG_ 361 StatusCPDData4FBD_HM_CIRData97 "contains CPD data to tap 25 - real part LSB";
CM_ SG_ 361 StatusCPDData4FBD_HM_CIRData98 "contains CPD data to tap 25 - imaginary part MSB";
CM_ SG_ 361 StatusCPDData4FBD_HM_CIRData99 "contains CPD data to tap 25 - imaginary part LSB";
CM_ SG_ 361 StatusCPDData4FBD_HM_CIRData100 "contains CPD data to tap 26 - real part MSB";
CM_ SG_ 361 StatusCPDData4FBD_HM_CIRData101 "contains CPD data to tap 26 - real part LSB";
CM_ SG_ 361 StatusCPDData4FBD_HM_CIRData102 "contains CPD data to tap 26 - imaginary part MSB";
CM_ SG_ 361 StatusCPDData4FBD_HM_CIRData103 "contains CPD data to tap 26 - imaginary part LSB";
CM_ SG_ 361 StatusCPDData4FBD_HM_CIRData104 "contains CPD data to tap 27 - real part MSB";
CM_ SG_ 361 StatusCPDData4FBD_HM_CIRData105 "contains CPD data to tap 27 - real part LSB";
CM_ SG_ 361 StatusCPDData4FBD_HM_CIRData106 "contains CPD data to tap 27 - imaginary part MSB";
CM_ SG_ 361 StatusCPDData4FBD_HM_CIRData107 "contains CPD data to tap 27 - imaginary part LSB";
CM_ SG_ 361 StatusCPDData4FBD_HM_CIRData108 "contains CPD data to tap 28 - real part MSB";
CM_ SG_ 361 StatusCPDData4FBD_HM_CIRData109 "contains CPD data to tap 28 - real part LSB";
CM_ SG_ 361 StatusCPDData4FBD_HM_CIRData110 "contains CPD data to tap 28 - imaginary part MSB";
CM_ SG_ 361 StatusCPDData4FBD_HM_CIRData111 "contains CPD data to tap 28 - imaginary part LSB";
CM_ SG_ 361 StatusCPDData4FBD_HM_CIRData112 "contains CPD data to tap 29 - real part MSB";
CM_ SG_ 361 StatusCPDData4FBD_HM_CIRData113 "contains CPD data to tap 29 - real part LSB";
CM_ SG_ 361 StatusCPDData4FBD_HM_CIRData114 "contains CPD data to tap 29 - imaginary part MSB";
CM_ SG_ 361 StatusCPDData4FBD_HM_CIRData115 "contains CPD data to tap 29 - imaginary part LSB";
CM_ SG_ 361 StatusCPDData4FBD_HM_CIRData116 "contains CPD data to tap 30 - real part MSB";
CM_ SG_ 361 StatusCPDData4FBD_HM_CIRData117 "contains CPD data to tap 30 - real part LSB";
CM_ SG_ 361 StatusCPDData4FBD_HM_CIRData118 "contains CPD data to tap 30 - imaginary part MSB";
CM_ SG_ 361 StatusCPDData4FBD_HM_CIRData119 "contains CPD data to tap 30 - imaginary part LSB";
CM_ SG_ 367 StatusCPDData4FBD_HR_MsgCounter "contains counter";
CM_ SG_ 367 StatusCPDData4FBD_HR_LinkID "contains link ID";
CM_ SG_ 367 StatusCPDData4FBD_HR_CollisionCo "contains collision counter";
CM_ SG_ 367 StatusCPDData4FBD_HR_CIRSetting "contains CIR Settings";
CM_ SG_ 367 StatusCPDData4FBD_HR_CIRData60 "contains CPD data to tap 16 - real part MSB";
CM_ SG_ 367 StatusCPDData4FBD_HR_CIRData61 "contains CPD data to tap 16 - real part LSB";
CM_ SG_ 367 StatusCPDData4FBD_HR_CIRData62 "contains CPD data to tap 16 - imaginary part MSB";
CM_ SG_ 367 StatusCPDData4FBD_HR_CIRData63 "contains CPD data to tap 16 - imaginary part LSB";
CM_ SG_ 367 StatusCPDData4FBD_HR_CIRData64 "contains CPD data to tap 17 - real part MSB";
CM_ SG_ 367 StatusCPDData4FBD_HR_CIRData65 "contains CPD data to tap 17 - real part LSB";
CM_ SG_ 367 StatusCPDData4FBD_HR_CIRData66 "contains CPD data to tap 17 - imaginary part MSB";
CM_ SG_ 367 StatusCPDData4FBD_HR_CIRData67 "contains CPD data to tap 17 - imaginary part LSB";
CM_ SG_ 367 StatusCPDData4FBD_HR_CIRData68 "contains CPD data to tap 18 - real part MSB";
CM_ SG_ 367 StatusCPDData4FBD_HR_CIRData69 "contains CPD data to tap 18 - real part LSB";
CM_ SG_ 367 StatusCPDData4FBD_HR_CIRData70 "contains CPD data to tap 18 - imaginary part MSB";
CM_ SG_ 367 StatusCPDData4FBD_HR_CIRData71 "contains CPD data to tap 18 - imaginary part LSB";
CM_ SG_ 367 StatusCPDData4FBD_HR_CIRData72 "contains CPD data to tap 19 - real part MSB";
CM_ SG_ 367 StatusCPDData4FBD_HR_CIRData73 "contains CPD data to tap 19 - real part LSB";
CM_ SG_ 367 StatusCPDData4FBD_HR_CIRData74 "contains CPD data to tap 19 - imaginary part MSB";
CM_ SG_ 367 StatusCPDData4FBD_HR_CIRData75 "contains CPD data to tap 19 - imaginary part LSB";
CM_ SG_ 367 StatusCPDData4FBD_HR_CIRData76 "contains CPD data to tap 20 - real part MSB";
CM_ SG_ 367 StatusCPDData4FBD_HR_CIRData77 "contains CPD data to tap 20 - real part LSB";
CM_ SG_ 367 StatusCPDData4FBD_HR_CIRData78 "contains CPD data to tap 20 - imaginary part MSB";
CM_ SG_ 367 StatusCPDData4FBD_HR_CIRData79 "contains CPD data to tap 20 - imaginary part LSB";
CM_ SG_ 367 StatusCPDData4FBD_HR_CIRData80 "contains CPD data to tap 21 - real part MSB";
CM_ SG_ 367 StatusCPDData4FBD_HR_CIRData81 "contains CPD data to tap 21 - real part LSB";
CM_ SG_ 367 StatusCPDData4FBD_HR_CIRData82 "contains CPD data to tap 21 - imaginary part MSB";
CM_ SG_ 367 StatusCPDData4FBD_HR_CIRData83 "contains CPD data to tap 21 - imaginary part LSB";
CM_ SG_ 367 StatusCPDData4FBD_HR_CIRData84 "contains CPD data to tap 22 - real part MSB";
CM_ SG_ 367 StatusCPDData4FBD_HR_CIRData85 "contains CPD data to tap 22 - real part LSB";
CM_ SG_ 367 StatusCPDData4FBD_HR_CIRData86 "contains CPD data to tap 22 - imaginary part MSB";
CM_ SG_ 367 StatusCPDData4FBD_HR_CIRData87 "contains CPD data to tap 22 - imaginary part LSB";
CM_ SG_ 367 StatusCPDData4FBD_HR_CIRData88 "contains CPD data to tap 23 - real part MSB";
CM_ SG_ 367 StatusCPDData4FBD_HR_CIRData89 "contains CPD data to tap 23 - real part LSB";
CM_ SG_ 367 StatusCPDData4FBD_HR_CIRData90 "contains CPD data to tap 23 - imaginary part MSB";
CM_ SG_ 367 StatusCPDData4FBD_HR_CIRData91 "contains CPD data to tap 23 - imaginary part LSB";
CM_ SG_ 367 StatusCPDData4FBD_HR_CIRData92 "contains CPD data to tap 24 - real part MSB";
CM_ SG_ 367 StatusCPDData4FBD_HR_CIRData93 "contains CPD data to tap 24 - real part LSB";
CM_ SG_ 367 StatusCPDData4FBD_HR_CIRData94 "contains CPD data to tap 24 - imaginary part MSB";
CM_ SG_ 367 StatusCPDData4FBD_HR_CIRData95 "contains CPD data to tap 24 - imaginary part LSB";
CM_ SG_ 367 StatusCPDData4FBD_HR_CIRData96 "contains CPD data to tap 25 - real part MSB";
CM_ SG_ 367 StatusCPDData4FBD_HR_CIRData97 "contains CPD data to tap 25 - real part LSB";
CM_ SG_ 367 StatusCPDData4FBD_HR_CIRData98 "contains CPD data to tap 25 - imaginary part MSB";
CM_ SG_ 367 StatusCPDData4FBD_HR_CIRData99 "contains CPD data to tap 25 - imaginary part LSB";
CM_ SG_ 367 StatusCPDData4FBD_HR_CIRData100 "contains CPD data to tap 26 - real part MSB";
CM_ SG_ 367 StatusCPDData4FBD_HR_CIRData101 "contains CPD data to tap 26 - real part LSB";
CM_ SG_ 367 StatusCPDData4FBD_HR_CIRData102 "contains CPD data to tap 26 - imaginary part MSB";
CM_ SG_ 367 StatusCPDData4FBD_HR_CIRData103 "contains CPD data to tap 26 - imaginary part LSB";
CM_ SG_ 367 StatusCPDData4FBD_HR_CIRData104 "contains CPD data to tap 27 - real part MSB";
CM_ SG_ 367 StatusCPDData4FBD_HR_CIRData105 "contains CPD data to tap 27 - real part LSB";
CM_ SG_ 367 StatusCPDData4FBD_HR_CIRData106 "contains CPD data to tap 27 - imaginary part MSB";
CM_ SG_ 367 StatusCPDData4FBD_HR_CIRData107 "contains CPD data to tap 27 - imaginary part LSB";
CM_ SG_ 367 StatusCPDData4FBD_HR_CIRData108 "contains CPD data to tap 28 - real part MSB";
CM_ SG_ 367 StatusCPDData4FBD_HR_CIRData109 "contains CPD data to tap 28 - real part LSB";
CM_ SG_ 367 StatusCPDData4FBD_HR_CIRData110 "contains CPD data to tap 28 - imaginary part MSB";
CM_ SG_ 367 StatusCPDData4FBD_HR_CIRData111 "contains CPD data to tap 28 - imaginary part LSB";
CM_ SG_ 367 StatusCPDData4FBD_HR_CIRData112 "contains CPD data to tap 29 - real part MSB";
CM_ SG_ 367 StatusCPDData4FBD_HR_CIRData113 "contains CPD data to tap 29 - real part LSB";
CM_ SG_ 367 StatusCPDData4FBD_HR_CIRData114 "contains CPD data to tap 29 - imaginary part MSB";
CM_ SG_ 367 StatusCPDData4FBD_HR_CIRData115 "contains CPD data to tap 29 - imaginary part LSB";
CM_ SG_ 367 StatusCPDData4FBD_HR_CIRData116 "contains CPD data to tap 30 - real part MSB";
CM_ SG_ 367 StatusCPDData4FBD_HR_CIRData117 "contains CPD data to tap 30 - real part LSB";
CM_ SG_ 367 StatusCPDData4FBD_HR_CIRData118 "contains CPD data to tap 30 - imaginary part MSB";
CM_ SG_ 367 StatusCPDData4FBD_HR_CIRData119 "contains CPD data to tap 30 - imaginary part LSB";
CM_ SG_ 362 StatusCPDData4FBD_Miko_MsgCounte "contains counter";
CM_ SG_ 362 StatusCPDData4FBD_Miko_LinkID "contains link ID";
CM_ SG_ 362 StatusCPDData4FBD_Miko_Collision "contains collision counter";
CM_ SG_ 362 StatusCPDData4FBD_Miko_CIRSettin "contains CIR Settings";
CM_ SG_ 362 StatusCPDData4FBD_Miko_CIRData60 "contains CPD data to tap 16 - real part MSB";
CM_ SG_ 362 StatusCPDData4FBD_Miko_CIRData61 "contains CPD data to tap 16 - real part LSB";
CM_ SG_ 362 StatusCPDData4FBD_Miko_CIRData62 "contains CPD data to tap 16 - imaginary part MSB";
CM_ SG_ 362 StatusCPDData4FBD_Miko_CIRData63 "contains CPD data to tap 16 - imaginary part LSB";
CM_ SG_ 362 StatusCPDData4FBD_Miko_CIRData64 "contains CPD data to tap 17 - real part MSB";
CM_ SG_ 362 StatusCPDData4FBD_Miko_CIRData65 "contains CPD data to tap 17 - real part LSB";
CM_ SG_ 362 StatusCPDData4FBD_Miko_CIRData66 "contains CPD data to tap 17 - imaginary part MSB";
CM_ SG_ 362 StatusCPDData4FBD_Miko_CIRData67 "contains CPD data to tap 17 - imaginary part LSB";
CM_ SG_ 362 StatusCPDData4FBD_Miko_CIRData68 "contains CPD data to tap 18 - real part MSB";
CM_ SG_ 362 StatusCPDData4FBD_Miko_CIRData69 "contains CPD data to tap 18 - real part LSB";
CM_ SG_ 362 StatusCPDData4FBD_Miko_CIRData70 "contains CPD data to tap 18 - imaginary part MSB";
CM_ SG_ 362 StatusCPDData4FBD_Miko_CIRData71 "contains CPD data to tap 18 - imaginary part LSB";
CM_ SG_ 362 StatusCPDData4FBD_Miko_CIRData72 "contains CPD data to tap 19 - real part MSB";
CM_ SG_ 362 StatusCPDData4FBD_Miko_CIRData73 "contains CPD data to tap 19 - real part LSB";
CM_ SG_ 362 StatusCPDData4FBD_Miko_CIRData74 "contains CPD data to tap 19 - imaginary part MSB";
CM_ SG_ 362 StatusCPDData4FBD_Miko_CIRData75 "contains CPD data to tap 19 - imaginary part LSB";
CM_ SG_ 362 StatusCPDData4FBD_Miko_CIRData76 "contains CPD data to tap 20 - real part MSB";
CM_ SG_ 362 StatusCPDData4FBD_Miko_CIRData77 "contains CPD data to tap 20 - real part LSB";
CM_ SG_ 362 StatusCPDData4FBD_Miko_CIRData78 "contains CPD data to tap 20 - imaginary part MSB";
CM_ SG_ 362 StatusCPDData4FBD_Miko_CIRData79 "contains CPD data to tap 20 - imaginary part LSB";
CM_ SG_ 362 StatusCPDData4FBD_Miko_CIRData80 "contains CPD data to tap 21 - real part MSB";
CM_ SG_ 362 StatusCPDData4FBD_Miko_CIRData81 "contains CPD data to tap 21 - real part LSB";
CM_ SG_ 362 StatusCPDData4FBD_Miko_CIRData82 "contains CPD data to tap 21 - imaginary part MSB";
CM_ SG_ 362 StatusCPDData4FBD_Miko_CIRData83 "contains CPD data to tap 21 - imaginary part LSB";
CM_ SG_ 362 StatusCPDData4FBD_Miko_CIRData84 "contains CPD data to tap 22 - real part MSB";
CM_ SG_ 362 StatusCPDData4FBD_Miko_CIRData85 "contains CPD data to tap 22 - real part LSB";
CM_ SG_ 362 StatusCPDData4FBD_Miko_CIRData86 "contains CPD data to tap 22 - imaginary part MSB";
CM_ SG_ 362 StatusCPDData4FBD_Miko_CIRData87 "contains CPD data to tap 22 - imaginary part LSB";
CM_ SG_ 362 StatusCPDData4FBD_Miko_CIRData88 "contains CPD data to tap 23 - real part MSB";
CM_ SG_ 362 StatusCPDData4FBD_Miko_CIRData89 "contains CPD data to tap 23 - real part LSB";
CM_ SG_ 362 StatusCPDData4FBD_Miko_CIRData90 "contains CPD data to tap 23 - imaginary part MSB";
CM_ SG_ 362 StatusCPDData4FBD_Miko_CIRData91 "contains CPD data to tap 23 - imaginary part LSB";
CM_ SG_ 362 StatusCPDData4FBD_Miko_CIRData92 "contains CPD data to tap 24 - real part MSB";
CM_ SG_ 362 StatusCPDData4FBD_Miko_CIRData93 "contains CPD data to tap 24 - real part LSB";
CM_ SG_ 362 StatusCPDData4FBD_Miko_CIRData94 "contains CPD data to tap 24 - imaginary part MSB";
CM_ SG_ 362 StatusCPDData4FBD_Miko_CIRData95 "contains CPD data to tap 24 - imaginary part LSB";
CM_ SG_ 362 StatusCPDData4FBD_Miko_CIRData96 "contains CPD data to tap 25 - real part MSB";
CM_ SG_ 362 StatusCPDData4FBD_Miko_CIRData97 "contains CPD data to tap 25 - real part LSB";
CM_ SG_ 362 StatusCPDData4FBD_Miko_CIRData98 "contains CPD data to tap 25 - imaginary part MSB";
CM_ SG_ 362 StatusCPDData4FBD_Miko_CIRData99 "contains CPD data to tap 25 - imaginary part LSB";
CM_ SG_ 362 StatusCPDData4FBD_Miko_CIRData10 "contains CPD data to tap 26 - real part MSB";
CM_ SG_ 362 StatusCPDData4FBD_Miko_CIRData_2 "contains CPD data to tap 26 - real part LSB";
CM_ SG_ 362 StatusCPDData4FBD_Miko_CIRData_3 "contains CPD data to tap 26 - imaginary part MSB";
CM_ SG_ 362 StatusCPDData4FBD_Miko_CIRData_4 "contains CPD data to tap 26 - imaginary part LSB";
CM_ SG_ 362 StatusCPDData4FBD_Miko_CIRData_5 "contains CPD data to tap 27 - real part MSB";
CM_ SG_ 362 StatusCPDData4FBD_Miko_CIRData_6 "contains CPD data to tap 27 - real part LSB";
CM_ SG_ 362 StatusCPDData4FBD_Miko_CIRData_7 "contains CPD data to tap 27 - imaginary part MSB";
CM_ SG_ 362 StatusCPDData4FBD_Miko_CIRData_8 "contains CPD data to tap 27 - imaginary part LSB";
CM_ SG_ 362 StatusCPDData4FBD_Miko_CIRData_9 "contains CPD data to tap 28 - real part MSB";
CM_ SG_ 362 StatusCPDData4FBD_Miko_CIRDat_10 "contains CPD data to tap 28 - real part LSB";
CM_ SG_ 362 StatusCPDData4FBD_Miko_CIRData11 "contains CPD data to tap 28 - imaginary part MSB";
CM_ SG_ 362 StatusCPDData4FBD_Miko_CIRDat_11 "contains CPD data to tap 28 - imaginary part LSB";
CM_ SG_ 362 StatusCPDData4FBD_Miko_CIRDat_12 "contains CPD data to tap 29 - real part MSB";
CM_ SG_ 362 StatusCPDData4FBD_Miko_CIRDat_13 "contains CPD data to tap 29 - real part LSB";
CM_ SG_ 362 StatusCPDData4FBD_Miko_CIRDat_14 "contains CPD data to tap 29 - imaginary part MSB";
CM_ SG_ 362 StatusCPDData4FBD_Miko_CIRDat_15 "contains CPD data to tap 29 - imaginary part LSB";
CM_ SG_ 362 StatusCPDData4FBD_Miko_CIRDat_16 "contains CPD data to tap 30 - real part MSB";
CM_ SG_ 362 StatusCPDData4FBD_Miko_CIRDat_17 "contains CPD data to tap 30 - real part LSB";
CM_ SG_ 362 StatusCPDData4FBD_Miko_CIRDat_18 "contains CPD data to tap 30 - imaginary part MSB";
CM_ SG_ 362 StatusCPDData4FBD_Miko_CIRDat_19 "contains CPD data to tap 30 - imaginary part LSB";
CM_ SG_ 836 StatusCPDData4FBD_MM_MsgCounter "contains counter";
CM_ SG_ 836 StatusCPDData4FBD_MM_LinkID "contains link ID";
CM_ SG_ 836 StatusCPDData4FBD_MM_CollisionCo "contains collision counter";
CM_ SG_ 836 StatusCPDData4FBD_MM_CIRSetting "contains CIR Settings";
CM_ SG_ 836 StatusCPDData4FBD_MM_CIRData60 "contains CPD data to tap 16 - real part MSB";
CM_ SG_ 836 StatusCPDData4FBD_MM_CIRData61 "contains CPD data to tap 16 - real part LSB";
CM_ SG_ 836 StatusCPDData4FBD_MM_CIRData62 "contains CPD data to tap 16 - imaginary part MSB";
CM_ SG_ 836 StatusCPDData4FBD_MM_CIRData63 "contains CPD data to tap 16 - imaginary part LSB";
CM_ SG_ 836 StatusCPDData4FBD_MM_CIRData64 "contains CPD data to tap 17 - real part MSB";
CM_ SG_ 836 StatusCPDData4FBD_MM_CIRData65 "contains CPD data to tap 17 - real part LSB";
CM_ SG_ 836 StatusCPDData4FBD_MM_CIRData66 "contains CPD data to tap 17 - imaginary part MSB";
CM_ SG_ 836 StatusCPDData4FBD_MM_CIRData67 "contains CPD data to tap 17 - imaginary part LSB";
CM_ SG_ 836 StatusCPDData4FBD_MM_CIRData68 "contains CPD data to tap 18 - real part MSB";
CM_ SG_ 836 StatusCPDData4FBD_MM_CIRData69 "contains CPD data to tap 18 - real part LSB";
CM_ SG_ 836 StatusCPDData4FBD_MM_CIRData70 "contains CPD data to tap 18 - imaginary part MSB";
CM_ SG_ 836 StatusCPDData4FBD_MM_CIRData71 "contains CPD data to tap 18 - imaginary part LSB";
CM_ SG_ 836 StatusCPDData4FBD_MM_CIRData72 "contains CPD data to tap 19 - real part MSB";
CM_ SG_ 836 StatusCPDData4FBD_MM_CIRData73 "contains CPD data to tap 19 - real part LSB";
CM_ SG_ 836 StatusCPDData4FBD_MM_CIRData74 "contains CPD data to tap 19 - imaginary part MSB";
CM_ SG_ 836 StatusCPDData4FBD_MM_CIRData75 "contains CPD data to tap 19 - imaginary part LSB";
CM_ SG_ 836 StatusCPDData4FBD_MM_CIRData76 "contains CPD data to tap 20 - real part MSB";
CM_ SG_ 836 StatusCPDData4FBD_MM_CIRData77 "contains CPD data to tap 20 - real part LSB";
CM_ SG_ 836 StatusCPDData4FBD_MM_CIRData78 "contains CPD data to tap 20 - imaginary part MSB";
CM_ SG_ 836 StatusCPDData4FBD_MM_CIRData79 "contains CPD data to tap 20 - imaginary part LSB";
CM_ SG_ 836 StatusCPDData4FBD_MM_CIRData80 "contains CPD data to tap 21 - real part MSB";
CM_ SG_ 836 StatusCPDData4FBD_MM_CIRData81 "contains CPD data to tap 21 - real part LSB";
CM_ SG_ 836 StatusCPDData4FBD_MM_CIRData82 "contains CPD data to tap 21 - imaginary part MSB";
CM_ SG_ 836 StatusCPDData4FBD_MM_CIRData83 "contains CPD data to tap 21 - imaginary part LSB";
CM_ SG_ 836 StatusCPDData4FBD_MM_CIRData84 "contains CPD data to tap 22 - real part MSB";
CM_ SG_ 836 StatusCPDData4FBD_MM_CIRData85 "contains CPD data to tap 22 - real part LSB";
CM_ SG_ 836 StatusCPDData4FBD_MM_CIRData86 "contains CPD data to tap 22 - imaginary part MSB";
CM_ SG_ 836 StatusCPDData4FBD_MM_CIRData87 "contains CPD data to tap 22 - imaginary part LSB";
CM_ SG_ 836 StatusCPDData4FBD_MM_CIRData88 "contains CPD data to tap 23 - real part MSB";
CM_ SG_ 836 StatusCPDData4FBD_MM_CIRData89 "contains CPD data to tap 23 - real part LSB";
CM_ SG_ 836 StatusCPDData4FBD_MM_CIRData90 "contains CPD data to tap 23 - imaginary part MSB";
CM_ SG_ 836 StatusCPDData4FBD_MM_CIRData91 "contains CPD data to tap 23 - imaginary part LSB";
CM_ SG_ 836 StatusCPDData4FBD_MM_CIRData92 "contains CPD data to tap 24 - real part MSB";
CM_ SG_ 836 StatusCPDData4FBD_MM_CIRData93 "contains CPD data to tap 24 - real part LSB";
CM_ SG_ 836 StatusCPDData4FBD_MM_CIRData94 "contains CPD data to tap 24 - imaginary part MSB";
CM_ SG_ 836 StatusCPDData4FBD_MM_CIRData95 "contains CPD data to tap 24 - imaginary part LSB";
CM_ SG_ 836 StatusCPDData4FBD_MM_CIRData96 "contains CPD data to tap 25 - real part MSB";
CM_ SG_ 836 StatusCPDData4FBD_MM_CIRData97 "contains CPD data to tap 25 - real part LSB";
CM_ SG_ 836 StatusCPDData4FBD_MM_CIRData98 "contains CPD data to tap 25 - imaginary part MSB";
CM_ SG_ 836 StatusCPDData4FBD_MM_CIRData99 "contains CPD data to tap 25 - imaginary part LSB";
CM_ SG_ 836 StatusCPDData4FBD_MM_CIRData100 "contains CPD data to tap 26 - real part MSB";
CM_ SG_ 836 StatusCPDData4FBD_MM_CIRData101 "contains CPD data to tap 26 - real part LSB";
CM_ SG_ 836 StatusCPDData4FBD_MM_CIRData102 "contains CPD data to tap 26 - imaginary part MSB";
CM_ SG_ 836 StatusCPDData4FBD_MM_CIRData103 "contains CPD data to tap 26 - imaginary part LSB";
CM_ SG_ 836 StatusCPDData4FBD_MM_CIRData104 "contains CPD data to tap 27 - real part MSB";
CM_ SG_ 836 StatusCPDData4FBD_MM_CIRData105 "contains CPD data to tap 27 - real part LSB";
CM_ SG_ 836 StatusCPDData4FBD_MM_CIRData106 "contains CPD data to tap 27 - imaginary part MSB";
CM_ SG_ 836 StatusCPDData4FBD_MM_CIRData107 "contains CPD data to tap 27 - imaginary part LSB";
CM_ SG_ 836 StatusCPDData4FBD_MM_CIRData108 "contains CPD data to tap 28 - real part MSB";
CM_ SG_ 836 StatusCPDData4FBD_MM_CIRData109 "contains CPD data to tap 28 - real part LSB";
CM_ SG_ 836 StatusCPDData4FBD_MM_CIRData110 "contains CPD data to tap 28 - imaginary part MSB";
CM_ SG_ 836 StatusCPDData4FBD_MM_CIRData111 "contains CPD data to tap 28 - imaginary part LSB";
CM_ SG_ 836 StatusCPDData4FBD_MM_CIRData112 "contains CPD data to tap 29 - real part MSB";
CM_ SG_ 836 StatusCPDData4FBD_MM_CIRData113 "contains CPD data to tap 29 - real part LSB";
CM_ SG_ 836 StatusCPDData4FBD_MM_CIRData114 "contains CPD data to tap 29 - imaginary part MSB";
CM_ SG_ 836 StatusCPDData4FBD_MM_CIRData115 "contains CPD data to tap 29 - imaginary part LSB";
CM_ SG_ 836 StatusCPDData4FBD_MM_CIRData116 "contains CPD data to tap 30 - real part MSB";
CM_ SG_ 836 StatusCPDData4FBD_MM_CIRData117 "contains CPD data to tap 30 - real part LSB";
CM_ SG_ 836 StatusCPDData4FBD_MM_CIRData118 "contains CPD data to tap 30 - imaginary part MSB";
CM_ SG_ 836 StatusCPDData4FBD_MM_CIRData119 "contains CPD data to tap 30 - imaginary part LSB";
CM_ SG_ 363 StatusCPDData4FBD_Trunk_MsgCount "contains counter";
CM_ SG_ 363 StatusCPDData4FBD_Trunk_LinkID "contains link ID";
CM_ SG_ 363 StatusCPDData4FBD_Trunk_Collisio "contains collision counter";
CM_ SG_ 363 StatusCPDData4FBD_Trunk_CIRSetti "contains CIR Settings";
CM_ SG_ 363 StatusCPDData4FBD_Trunk_CIRData6 "contains CPD data to tap 16 - real part MSB";
CM_ SG_ 363 StatusCPDData4FBD_Trunk_CIRDat_2 "contains CPD data to tap 16 - real part LSB";
CM_ SG_ 363 StatusCPDData4FBD_Trunk_CIRDat_3 "contains CPD data to tap 16 - imaginary part MSB";
CM_ SG_ 363 StatusCPDData4FBD_Trunk_CIRDat_4 "contains CPD data to tap 16 - imaginary part LSB";
CM_ SG_ 363 StatusCPDData4FBD_Trunk_CIRDat_5 "contains CPD data to tap 17 - real part MSB";
CM_ SG_ 363 StatusCPDData4FBD_Trunk_CIRDat_6 "contains CPD data to tap 17 - real part LSB";
CM_ SG_ 363 StatusCPDData4FBD_Trunk_CIRDat_7 "contains CPD data to tap 17 - imaginary part MSB";
CM_ SG_ 363 StatusCPDData4FBD_Trunk_CIRDat_8 "contains CPD data to tap 17 - imaginary part LSB";
CM_ SG_ 363 StatusCPDData4FBD_Trunk_CIRDat_9 "contains CPD data to tap 18 - real part MSB";
CM_ SG_ 363 StatusCPDData4FBD_Trunk_CIRDa_10 "contains CPD data to tap 18 - real part LSB";
CM_ SG_ 363 StatusCPDData4FBD_Trunk_CIRData7 "contains CPD data to tap 18 - imaginary part MSB";
CM_ SG_ 363 StatusCPDData4FBD_Trunk_CIRDa_11 "contains CPD data to tap 18 - imaginary part LSB";
CM_ SG_ 363 StatusCPDData4FBD_Trunk_CIRDa_12 "contains CPD data to tap 19 - real part MSB";
CM_ SG_ 363 StatusCPDData4FBD_Trunk_CIRDa_13 "contains CPD data to tap 19 - real part LSB";
CM_ SG_ 363 StatusCPDData4FBD_Trunk_CIRDa_14 "contains CPD data to tap 19 - imaginary part MSB";
CM_ SG_ 363 StatusCPDData4FBD_Trunk_CIRDa_15 "contains CPD data to tap 19 - imaginary part LSB";
CM_ SG_ 363 StatusCPDData4FBD_Trunk_CIRDa_16 "contains CPD data to tap 20 - real part MSB";
CM_ SG_ 363 StatusCPDData4FBD_Trunk_CIRDa_17 "contains CPD data to tap 20 - real part LSB";
CM_ SG_ 363 StatusCPDData4FBD_Trunk_CIRDa_18 "contains CPD data to tap 20 - imaginary part MSB";
CM_ SG_ 363 StatusCPDData4FBD_Trunk_CIRDa_19 "contains CPD data to tap 20 - imaginary part LSB";
CM_ SG_ 363 StatusCPDData4FBD_Trunk_CIRData8 "contains CPD data to tap 21 - real part MSB";
CM_ SG_ 363 StatusCPDData4FBD_Trunk_CIRDa_20 "contains CPD data to tap 21 - real part LSB";
CM_ SG_ 363 StatusCPDData4FBD_Trunk_CIRDa_21 "contains CPD data to tap 21 - imaginary part MSB";
CM_ SG_ 363 StatusCPDData4FBD_Trunk_CIRDa_22 "contains CPD data to tap 21 - imaginary part LSB";
CM_ SG_ 363 StatusCPDData4FBD_Trunk_CIRDa_23 "contains CPD data to tap 22 - real part MSB";
CM_ SG_ 363 StatusCPDData4FBD_Trunk_CIRDa_24 "contains CPD data to tap 22 - real part LSB";
CM_ SG_ 363 StatusCPDData4FBD_Trunk_CIRDa_25 "contains CPD data to tap 22 - imaginary part MSB";
CM_ SG_ 363 StatusCPDData4FBD_Trunk_CIRDa_26 "contains CPD data to tap 22 - imaginary part LSB";
CM_ SG_ 363 StatusCPDData4FBD_Trunk_CIRDa_27 "contains CPD data to tap 23 - real part MSB";
CM_ SG_ 363 StatusCPDData4FBD_Trunk_CIRDa_28 "contains CPD data to tap 23 - real part LSB";
CM_ SG_ 363 StatusCPDData4FBD_Trunk_CIRData9 "contains CPD data to tap 23 - imaginary part MSB";
CM_ SG_ 363 StatusCPDData4FBD_Trunk_CIRDa_29 "contains CPD data to tap 23 - imaginary part LSB";
CM_ SG_ 363 StatusCPDData4FBD_Trunk_CIRDa_30 "contains CPD data to tap 24 - real part MSB";
CM_ SG_ 363 StatusCPDData4FBD_Trunk_CIRDa_31 "contains CPD data to tap 24 - real part LSB";
CM_ SG_ 363 StatusCPDData4FBD_Trunk_CIRDa_32 "contains CPD data to tap 24 - imaginary part MSB";
CM_ SG_ 363 StatusCPDData4FBD_Trunk_CIRDa_33 "contains CPD data to tap 24 - imaginary part LSB";
CM_ SG_ 363 StatusCPDData4FBD_Trunk_CIRDa_34 "contains CPD data to tap 25 - real part MSB";
CM_ SG_ 363 StatusCPDData4FBD_Trunk_CIRDa_35 "contains CPD data to tap 25 - real part LSB";
CM_ SG_ 363 StatusCPDData4FBD_Trunk_CIRDa_36 "contains CPD data to tap 25 - imaginary part MSB";
CM_ SG_ 363 StatusCPDData4FBD_Trunk_CIRDa_37 "contains CPD data to tap 25 - imaginary part LSB";
CM_ SG_ 363 StatusCPDData4FBD_Trunk_CIRData1 "contains CPD data to tap 26 - real part MSB";
CM_ SG_ 363 StatusCPDData4FBD_Trunk_CIRDa_38 "contains CPD data to tap 26 - real part LSB";
CM_ SG_ 363 StatusCPDData4FBD_Trunk_CIRDa_39 "contains CPD data to tap 26 - imaginary part MSB";
CM_ SG_ 363 StatusCPDData4FBD_Trunk_CIRDa_40 "contains CPD data to tap 26 - imaginary part LSB";
CM_ SG_ 363 StatusCPDData4FBD_Trunk_CIRDa_41 "contains CPD data to tap 27 - real part MSB";
CM_ SG_ 363 StatusCPDData4FBD_Trunk_CIRDa_42 "contains CPD data to tap 27 - real part LSB";
CM_ SG_ 363 StatusCPDData4FBD_Trunk_CIRDa_43 "contains CPD data to tap 27 - imaginary part MSB";
CM_ SG_ 363 StatusCPDData4FBD_Trunk_CIRDa_44 "contains CPD data to tap 27 - imaginary part LSB";
CM_ SG_ 363 StatusCPDData4FBD_Trunk_CIRDa_45 "contains CPD data to tap 28 - real part MSB";
CM_ SG_ 363 StatusCPDData4FBD_Trunk_CIRDa_46 "contains CPD data to tap 28 - real part LSB";
CM_ SG_ 363 StatusCPDData4FBD_Trunk_CIRDa_47 "contains CPD data to tap 28 - imaginary part MSB";
CM_ SG_ 363 StatusCPDData4FBD_Trunk_CIRDa_48 "contains CPD data to tap 28 - imaginary part LSB";
CM_ SG_ 363 StatusCPDData4FBD_Trunk_CIRDa_49 "contains CPD data to tap 29 - real part MSB";
CM_ SG_ 363 StatusCPDData4FBD_Trunk_CIRDa_50 "contains CPD data to tap 29 - real part LSB";
CM_ SG_ 363 StatusCPDData4FBD_Trunk_CIRDa_51 "contains CPD data to tap 29 - imaginary part MSB";
CM_ SG_ 363 StatusCPDData4FBD_Trunk_CIRDa_52 "contains CPD data to tap 29 - imaginary part LSB";
CM_ SG_ 363 StatusCPDData4FBD_Trunk_CIRDa_53 "contains CPD data to tap 30 - real part MSB";
CM_ SG_ 363 StatusCPDData4FBD_Trunk_CIRDa_54 "contains CPD data to tap 30 - real part LSB";
CM_ SG_ 363 StatusCPDData4FBD_Trunk_CIRDa_55 "contains CPD data to tap 30 - imaginary part MSB";
CM_ SG_ 363 StatusCPDData4FBD_Trunk_CIRDa_56 "contains CPD data to tap 30 - imaginary part LSB";
CM_ SG_ 364 StatusCPDData4FBD_VL_MsgCounter "contains counter";
CM_ SG_ 364 StatusCPDData4FBD_VL_LinkID "contains link ID";
CM_ SG_ 364 StatusCPDData4FBD_VL_CollisionCo "contains collision counter";
CM_ SG_ 364 StatusCPDData4FBD_VL_CIRSetting "contains CIR Settings";
CM_ SG_ 364 StatusCPDData4FBD_VL_CIRData60 "contains CPD data to tap 16 - real part MSB";
CM_ SG_ 364 StatusCPDData4FBD_VL_CIRData61 "contains CPD data to tap 16 - real part LSB";
CM_ SG_ 364 StatusCPDData4FBD_VL_CIRData62 "contains CPD data to tap 16 - imaginary part MSB";
CM_ SG_ 364 StatusCPDData4FBD_VL_CIRData63 "contains CPD data to tap 16 - imaginary part LSB";
CM_ SG_ 364 StatusCPDData4FBD_VL_CIRData64 "contains CPD data to tap 17 - real part MSB";
CM_ SG_ 364 StatusCPDData4FBD_VL_CIRData65 "contains CPD data to tap 17 - real part LSB";
CM_ SG_ 364 StatusCPDData4FBD_VL_CIRData66 "contains CPD data to tap 17 - imaginary part MSB";
CM_ SG_ 364 StatusCPDData4FBD_VL_CIRData67 "contains CPD data to tap 17 - imaginary part LSB";
CM_ SG_ 364 StatusCPDData4FBD_VL_CIRData68 "contains CPD data to tap 18 - real part MSB";
CM_ SG_ 364 StatusCPDData4FBD_VL_CIRData69 "contains CPD data to tap 18 - real part LSB";
CM_ SG_ 364 StatusCPDData4FBD_VL_CIRData70 "contains CPD data to tap 18 - imaginary part MSB";
CM_ SG_ 364 StatusCPDData4FBD_VL_CIRData71 "contains CPD data to tap 18 - imaginary part LSB";
CM_ SG_ 364 StatusCPDData4FBD_VL_CIRData72 "contains CPD data to tap 19 - real part MSB";
CM_ SG_ 364 StatusCPDData4FBD_VL_CIRData73 "contains CPD data to tap 19 - real part LSB";
CM_ SG_ 364 StatusCPDData4FBD_VL_CIRData74 "contains CPD data to tap 19 - imaginary part MSB";
CM_ SG_ 364 StatusCPDData4FBD_VL_CIRData75 "contains CPD data to tap 19 - imaginary part LSB";
CM_ SG_ 364 StatusCPDData4FBD_VL_CIRData76 "contains CPD data to tap 20 - real part MSB";
CM_ SG_ 364 StatusCPDData4FBD_VL_CIRData77 "contains CPD data to tap 20 - real part LSB";
CM_ SG_ 364 StatusCPDData4FBD_VL_CIRData78 "contains CPD data to tap 20 - imaginary part MSB";
CM_ SG_ 364 StatusCPDData4FBD_VL_CIRData79 "contains CPD data to tap 20 - imaginary part LSB";
CM_ SG_ 364 StatusCPDData4FBD_VL_CIRData80 "contains CPD data to tap 21 - real part MSB";
CM_ SG_ 364 StatusCPDData4FBD_VL_CIRData81 "contains CPD data to tap 21 - real part LSB";
CM_ SG_ 364 StatusCPDData4FBD_VL_CIRData82 "contains CPD data to tap 21 - imaginary part MSB";
CM_ SG_ 364 StatusCPDData4FBD_VL_CIRData83 "contains CPD data to tap 21 - imaginary part LSB";
CM_ SG_ 364 StatusCPDData4FBD_VL_CIRData84 "contains CPD data to tap 22 - real part MSB";
CM_ SG_ 364 StatusCPDData4FBD_VL_CIRData85 "contains CPD data to tap 22 - real part LSB";
CM_ SG_ 364 StatusCPDData4FBD_VL_CIRData86 "contains CPD data to tap 22 - imaginary part MSB";
CM_ SG_ 364 StatusCPDData4FBD_VL_CIRData87 "contains CPD data to tap 22 - imaginary part LSB";
CM_ SG_ 364 StatusCPDData4FBD_VL_CIRData88 "contains CPD data to tap 23 - real part MSB";
CM_ SG_ 364 StatusCPDData4FBD_VL_CIRData89 "contains CPD data to tap 23 - real part LSB";
CM_ SG_ 364 StatusCPDData4FBD_VL_CIRData90 "contains CPD data to tap 23 - imaginary part MSB";
CM_ SG_ 364 StatusCPDData4FBD_VL_CIRData91 "contains CPD data to tap 23 - imaginary part LSB";
CM_ SG_ 364 StatusCPDData4FBD_VL_CIRData92 "contains CPD data to tap 24 - real part MSB";
CM_ SG_ 364 StatusCPDData4FBD_VL_CIRData93 "contains CPD data to tap 24 - real part LSB";
CM_ SG_ 364 StatusCPDData4FBD_VL_CIRData94 "contains CPD data to tap 24 - imaginary part MSB";
CM_ SG_ 364 StatusCPDData4FBD_VL_CIRData95 "contains CPD data to tap 24 - imaginary part LSB";
CM_ SG_ 364 StatusCPDData4FBD_VL_CIRData96 "contains CPD data to tap 25 - real part MSB";
CM_ SG_ 364 StatusCPDData4FBD_VL_CIRData97 "contains CPD data to tap 25 - real part LSB";
CM_ SG_ 364 StatusCPDData4FBD_VL_CIRData98 "contains CPD data to tap 25 - imaginary part MSB";
CM_ SG_ 364 StatusCPDData4FBD_VL_CIRData99 "contains CPD data to tap 25 - imaginary part LSB";
CM_ SG_ 364 StatusCPDData4FBD_VL_CIRData100 "contains CPD data to tap 26 - real part MSB";
CM_ SG_ 364 StatusCPDData4FBD_VL_CIRData101 "contains CPD data to tap 26 - real part LSB";
CM_ SG_ 364 StatusCPDData4FBD_VL_CIRData102 "contains CPD data to tap 26 - imaginary part MSB";
CM_ SG_ 364 StatusCPDData4FBD_VL_CIRData103 "contains CPD data to tap 26 - imaginary part LSB";
CM_ SG_ 364 StatusCPDData4FBD_VL_CIRData104 "contains CPD data to tap 27 - real part MSB";
CM_ SG_ 364 StatusCPDData4FBD_VL_CIRData105 "contains CPD data to tap 27 - real part LSB";
CM_ SG_ 364 StatusCPDData4FBD_VL_CIRData106 "contains CPD data to tap 27 - imaginary part MSB";
CM_ SG_ 364 StatusCPDData4FBD_VL_CIRData107 "contains CPD data to tap 27 - imaginary part LSB";
CM_ SG_ 364 StatusCPDData4FBD_VL_CIRData108 "contains CPD data to tap 28 - real part MSB";
CM_ SG_ 364 StatusCPDData4FBD_VL_CIRData109 "contains CPD data to tap 28 - real part LSB";
CM_ SG_ 364 StatusCPDData4FBD_VL_CIRData110 "contains CPD data to tap 28 - imaginary part MSB";
CM_ SG_ 364 StatusCPDData4FBD_VL_CIRData111 "contains CPD data to tap 28 - imaginary part LSB";
CM_ SG_ 364 StatusCPDData4FBD_VL_CIRData112 "contains CPD data to tap 29 - real part MSB";
CM_ SG_ 364 StatusCPDData4FBD_VL_CIRData113 "contains CPD data to tap 29 - real part LSB";
CM_ SG_ 364 StatusCPDData4FBD_VL_CIRData114 "contains CPD data to tap 29 - imaginary part MSB";
CM_ SG_ 364 StatusCPDData4FBD_VL_CIRData115 "contains CPD data to tap 29 - imaginary part LSB";
CM_ SG_ 364 StatusCPDData4FBD_VL_CIRData116 "contains CPD data to tap 30 - real part MSB";
CM_ SG_ 364 StatusCPDData4FBD_VL_CIRData117 "contains CPD data to tap 30 - real part LSB";
CM_ SG_ 364 StatusCPDData4FBD_VL_CIRData118 "contains CPD data to tap 30 - imaginary part MSB";
CM_ SG_ 364 StatusCPDData4FBD_VL_CIRData119 "contains CPD data to tap 30 - imaginary part LSB";
CM_ SG_ 360 StatusCPDData4FBD_VM_MsgCounter "contains counter";
CM_ SG_ 360 StatusCPDData4FBD_VM_LinkID "contains link ID";
CM_ SG_ 360 StatusCPDData4FBD_VM_CollisionCo "contains collision counter";
CM_ SG_ 360 StatusCPDData4FBD_VM_CIRSetting "contains CIR Settings";
CM_ SG_ 360 StatusCPDData4FBD_VM_CIRData60 "contains CPD data to tap 16 - real part MSB";
CM_ SG_ 360 StatusCPDData4FBD_VM_CIRData61 "contains CPD data to tap 16 - real part LSB";
CM_ SG_ 360 StatusCPDData4FBD_VM_CIRData62 "contains CPD data to tap 16 - imaginary part MSB";
CM_ SG_ 360 StatusCPDData4FBD_VM_CIRData63 "contains CPD data to tap 16 - imaginary part LSB";
CM_ SG_ 360 StatusCPDData4FBD_VM_CIRData64 "contains CPD data to tap 17 - real part MSB";
CM_ SG_ 360 StatusCPDData4FBD_VM_CIRData65 "contains CPD data to tap 17 - real part LSB";
CM_ SG_ 360 StatusCPDData4FBD_VM_CIRData66 "contains CPD data to tap 17 - imaginary part MSB";
CM_ SG_ 360 StatusCPDData4FBD_VM_CIRData67 "contains CPD data to tap 17 - imaginary part LSB";
CM_ SG_ 360 StatusCPDData4FBD_VM_CIRData68 "contains CPD data to tap 18 - real part MSB";
CM_ SG_ 360 StatusCPDData4FBD_VM_CIRData69 "contains CPD data to tap 18 - real part LSB";
CM_ SG_ 360 StatusCPDData4FBD_VM_CIRData70 "contains CPD data to tap 18 - imaginary part MSB";
CM_ SG_ 360 StatusCPDData4FBD_VM_CIRData71 "contains CPD data to tap 18 - imaginary part LSB";
CM_ SG_ 360 StatusCPDData4FBD_VM_CIRData72 "contains CPD data to tap 19 - real part MSB";
CM_ SG_ 360 StatusCPDData4FBD_VM_CIRData73 "contains CPD data to tap 19 - real part LSB";
CM_ SG_ 360 StatusCPDData4FBD_VM_CIRData74 "contains CPD data to tap 19 - imaginary part MSB";
CM_ SG_ 360 StatusCPDData4FBD_VM_CIRData75 "contains CPD data to tap 19 - imaginary part LSB";
CM_ SG_ 360 StatusCPDData4FBD_VM_CIRData76 "contains CPD data to tap 20 - real part MSB";
CM_ SG_ 360 StatusCPDData4FBD_VM_CIRData77 "contains CPD data to tap 20 - real part LSB";
CM_ SG_ 360 StatusCPDData4FBD_VM_CIRData78 "contains CPD data to tap 20 - imaginary part MSB";
CM_ SG_ 360 StatusCPDData4FBD_VM_CIRData79 "contains CPD data to tap 20 - imaginary part LSB";
CM_ SG_ 360 StatusCPDData4FBD_VM_CIRData80 "contains CPD data to tap 21 - real part MSB";
CM_ SG_ 360 StatusCPDData4FBD_VM_CIRData81 "contains CPD data to tap 21 - real part LSB";
CM_ SG_ 360 StatusCPDData4FBD_VM_CIRData82 "contains CPD data to tap 21 - imaginary part MSB";
CM_ SG_ 360 StatusCPDData4FBD_VM_CIRData83 "contains CPD data to tap 21 - imaginary part LSB";
CM_ SG_ 360 StatusCPDData4FBD_VM_CIRData84 "contains CPD data to tap 22 - real part MSB";
CM_ SG_ 360 StatusCPDData4FBD_VM_CIRData85 "contains CPD data to tap 22 - real part LSB";
CM_ SG_ 360 StatusCPDData4FBD_VM_CIRData86 "contains CPD data to tap 22 - imaginary part MSB";
CM_ SG_ 360 StatusCPDData4FBD_VM_CIRData87 "contains CPD data to tap 22 - imaginary part LSB";
CM_ SG_ 360 StatusCPDData4FBD_VM_CIRData88 "contains CPD data to tap 23 - real part MSB";
CM_ SG_ 360 StatusCPDData4FBD_VM_CIRData89 "contains CPD data to tap 23 - real part LSB";
CM_ SG_ 360 StatusCPDData4FBD_VM_CIRData90 "contains CPD data to tap 23 - imaginary part MSB";
CM_ SG_ 360 StatusCPDData4FBD_VM_CIRData91 "contains CPD data to tap 23 - imaginary part LSB";
CM_ SG_ 360 StatusCPDData4FBD_VM_CIRData92 "contains CPD data to tap 24 - real part MSB";
CM_ SG_ 360 StatusCPDData4FBD_VM_CIRData93 "contains CPD data to tap 24 - real part LSB";
CM_ SG_ 360 StatusCPDData4FBD_VM_CIRData94 "contains CPD data to tap 24 - imaginary part MSB";
CM_ SG_ 360 StatusCPDData4FBD_VM_CIRData95 "contains CPD data to tap 24 - imaginary part LSB";
CM_ SG_ 360 StatusCPDData4FBD_VM_CIRData96 "contains CPD data to tap 25 - real part MSB";
CM_ SG_ 360 StatusCPDData4FBD_VM_CIRData97 "contains CPD data to tap 25 - real part LSB";
CM_ SG_ 360 StatusCPDData4FBD_VM_CIRData98 "contains CPD data to tap 25 - imaginary part MSB";
CM_ SG_ 360 StatusCPDData4FBD_VM_CIRData99 "contains CPD data to tap 25 - imaginary part LSB";
CM_ SG_ 360 StatusCPDData4FBD_VM_CIRData100 "contains CPD data to tap 26 - real part MSB";
CM_ SG_ 360 StatusCPDData4FBD_VM_CIRData101 "contains CPD data to tap 26 - real part LSB";
CM_ SG_ 360 StatusCPDData4FBD_VM_CIRData102 "contains CPD data to tap 26 - imaginary part MSB";
CM_ SG_ 360 StatusCPDData4FBD_VM_CIRData103 "contains CPD data to tap 26 - imaginary part LSB";
CM_ SG_ 360 StatusCPDData4FBD_VM_CIRData104 "contains CPD data to tap 27 - real part MSB";
CM_ SG_ 360 StatusCPDData4FBD_VM_CIRData105 "contains CPD data to tap 27 - real part LSB";
CM_ SG_ 360 StatusCPDData4FBD_VM_CIRData106 "contains CPD data to tap 27 - imaginary part MSB";
CM_ SG_ 360 StatusCPDData4FBD_VM_CIRData107 "contains CPD data to tap 27 - imaginary part LSB";
CM_ SG_ 360 StatusCPDData4FBD_VM_CIRData108 "contains CPD data to tap 28 - real part MSB";
CM_ SG_ 360 StatusCPDData4FBD_VM_CIRData109 "contains CPD data to tap 28 - real part LSB";
CM_ SG_ 360 StatusCPDData4FBD_VM_CIRData110 "contains CPD data to tap 28 - imaginary part MSB";
CM_ SG_ 360 StatusCPDData4FBD_VM_CIRData111 "contains CPD data to tap 28 - imaginary part LSB";
CM_ SG_ 360 StatusCPDData4FBD_VM_CIRData112 "contains CPD data to tap 29 - real part MSB";
CM_ SG_ 360 StatusCPDData4FBD_VM_CIRData113 "contains CPD data to tap 29 - real part LSB";
CM_ SG_ 360 StatusCPDData4FBD_VM_CIRData114 "contains CPD data to tap 29 - imaginary part MSB";
CM_ SG_ 360 StatusCPDData4FBD_VM_CIRData115 "contains CPD data to tap 29 - imaginary part LSB";
CM_ SG_ 360 StatusCPDData4FBD_VM_CIRData116 "contains CPD data to tap 30 - real part MSB";
CM_ SG_ 360 StatusCPDData4FBD_VM_CIRData117 "contains CPD data to tap 30 - real part LSB";
CM_ SG_ 360 StatusCPDData4FBD_VM_CIRData118 "contains CPD data to tap 30 - imaginary part MSB";
CM_ SG_ 360 StatusCPDData4FBD_VM_CIRData119 "contains CPD data to tap 30 - imaginary part LSB";
CM_ SG_ 365 StatusCPDData4FBD_VR_MsgCounter "contains counter";
CM_ SG_ 365 StatusCPDData4FBD_VR_LinkID "contains link ID";
CM_ SG_ 365 StatusCPDData4FBD_VR_CollisionCo "contains collision counter";
CM_ SG_ 365 StatusCPDData4FBD_VR_CIRSetting "contains CIR Settings";
CM_ SG_ 365 StatusCPDData4FBD_VR_CIRData60 "contains CPD data to tap 16 - real part MSB";
CM_ SG_ 365 StatusCPDData4FBD_VR_CIRData61 "contains CPD data to tap 16 - real part LSB";
CM_ SG_ 365 StatusCPDData4FBD_VR_CIRData62 "contains CPD data to tap 16 - imaginary part MSB";
CM_ SG_ 365 StatusCPDData4FBD_VR_CIRData63 "contains CPD data to tap 16 - imaginary part LSB";
CM_ SG_ 365 StatusCPDData4FBD_VR_CIRData64 "contains CPD data to tap 17 - real part MSB";
CM_ SG_ 365 StatusCPDData4FBD_VR_CIRData65 "contains CPD data to tap 17 - real part LSB";
CM_ SG_ 365 StatusCPDData4FBD_VR_CIRData66 "contains CPD data to tap 17 - imaginary part MSB";
CM_ SG_ 365 StatusCPDData4FBD_VR_CIRData67 "contains CPD data to tap 17 - imaginary part LSB";
CM_ SG_ 365 StatusCPDData4FBD_VR_CIRData68 "contains CPD data to tap 18 - real part MSB";
CM_ SG_ 365 StatusCPDData4FBD_VR_CIRData69 "contains CPD data to tap 18 - real part LSB";
CM_ SG_ 365 StatusCPDData4FBD_VR_CIRData70 "contains CPD data to tap 18 - imaginary part MSB";
CM_ SG_ 365 StatusCPDData4FBD_VR_CIRData71 "contains CPD data to tap 18 - imaginary part LSB";
CM_ SG_ 365 StatusCPDData4FBD_VR_CIRData72 "contains CPD data to tap 19 - real part MSB";
CM_ SG_ 365 StatusCPDData4FBD_VR_CIRData73 "contains CPD data to tap 19 - real part LSB";
CM_ SG_ 365 StatusCPDData4FBD_VR_CIRData74 "contains CPD data to tap 19 - imaginary part MSB";
CM_ SG_ 365 StatusCPDData4FBD_VR_CIRData75 "contains CPD data to tap 19 - imaginary part LSB";
CM_ SG_ 365 StatusCPDData4FBD_VR_CIRData76 "contains CPD data to tap 20 - real part MSB";
CM_ SG_ 365 StatusCPDData4FBD_VR_CIRData77 "contains CPD data to tap 20 - real part LSB";
CM_ SG_ 365 StatusCPDData4FBD_VR_CIRData78 "contains CPD data to tap 20 - imaginary part MSB";
CM_ SG_ 365 StatusCPDData4FBD_VR_CIRData79 "contains CPD data to tap 20 - imaginary part LSB";
CM_ SG_ 365 StatusCPDData4FBD_VR_CIRData80 "contains CPD data to tap 21 - real part MSB";
CM_ SG_ 365 StatusCPDData4FBD_VR_CIRData81 "contains CPD data to tap 21 - real part LSB";
CM_ SG_ 365 StatusCPDData4FBD_VR_CIRData82 "contains CPD data to tap 21 - imaginary part MSB";
CM_ SG_ 365 StatusCPDData4FBD_VR_CIRData83 "contains CPD data to tap 21 - imaginary part LSB";
CM_ SG_ 365 StatusCPDData4FBD_VR_CIRData84 "contains CPD data to tap 22 - real part MSB";
CM_ SG_ 365 StatusCPDData4FBD_VR_CIRData85 "contains CPD data to tap 22 - real part LSB";
CM_ SG_ 365 StatusCPDData4FBD_VR_CIRData86 "contains CPD data to tap 22 - imaginary part MSB";
CM_ SG_ 365 StatusCPDData4FBD_VR_CIRData87 "contains CPD data to tap 22 - imaginary part LSB";
CM_ SG_ 365 StatusCPDData4FBD_VR_CIRData88 "contains CPD data to tap 23 - real part MSB";
CM_ SG_ 365 StatusCPDData4FBD_VR_CIRData89 "contains CPD data to tap 23 - real part LSB";
CM_ SG_ 365 StatusCPDData4FBD_VR_CIRData90 "contains CPD data to tap 23 - imaginary part MSB";
CM_ SG_ 365 StatusCPDData4FBD_VR_CIRData91 "contains CPD data to tap 23 - imaginary part LSB";
CM_ SG_ 365 StatusCPDData4FBD_VR_CIRData92 "contains CPD data to tap 24 - real part MSB";
CM_ SG_ 365 StatusCPDData4FBD_VR_CIRData93 "contains CPD data to tap 24 - real part LSB";
CM_ SG_ 365 StatusCPDData4FBD_VR_CIRData94 "contains CPD data to tap 24 - imaginary part MSB";
CM_ SG_ 365 StatusCPDData4FBD_VR_CIRData95 "contains CPD data to tap 24 - imaginary part LSB";
CM_ SG_ 365 StatusCPDData4FBD_VR_CIRData96 "contains CPD data to tap 25 - real part MSB";
CM_ SG_ 365 StatusCPDData4FBD_VR_CIRData97 "contains CPD data to tap 25 - real part LSB";
CM_ SG_ 365 StatusCPDData4FBD_VR_CIRData98 "contains CPD data to tap 25 - imaginary part MSB";
CM_ SG_ 365 StatusCPDData4FBD_VR_CIRData99 "contains CPD data to tap 25 - imaginary part LSB";
CM_ SG_ 365 StatusCPDData4FBD_VR_CIRData100 "contains CPD data to tap 26 - real part MSB";
CM_ SG_ 365 StatusCPDData4FBD_VR_CIRData101 "contains CPD data to tap 26 - real part LSB";
CM_ SG_ 365 StatusCPDData4FBD_VR_CIRData102 "contains CPD data to tap 26 - imaginary part MSB";
CM_ SG_ 365 StatusCPDData4FBD_VR_CIRData103 "contains CPD data to tap 26 - imaginary part LSB";
CM_ SG_ 365 StatusCPDData4FBD_VR_CIRData104 "contains CPD data to tap 27 - real part MSB";
CM_ SG_ 365 StatusCPDData4FBD_VR_CIRData105 "contains CPD data to tap 27 - real part LSB";
CM_ SG_ 365 StatusCPDData4FBD_VR_CIRData106 "contains CPD data to tap 27 - imaginary part MSB";
CM_ SG_ 365 StatusCPDData4FBD_VR_CIRData107 "contains CPD data to tap 27 - imaginary part LSB";
CM_ SG_ 365 StatusCPDData4FBD_VR_CIRData108 "contains CPD data to tap 28 - real part MSB";
CM_ SG_ 365 StatusCPDData4FBD_VR_CIRData109 "contains CPD data to tap 28 - real part LSB";
CM_ SG_ 365 StatusCPDData4FBD_VR_CIRData110 "contains CPD data to tap 28 - imaginary part MSB";
CM_ SG_ 365 StatusCPDData4FBD_VR_CIRData111 "contains CPD data to tap 28 - imaginary part LSB";
CM_ SG_ 365 StatusCPDData4FBD_VR_CIRData112 "contains CPD data to tap 29 - real part MSB";
CM_ SG_ 365 StatusCPDData4FBD_VR_CIRData113 "contains CPD data to tap 29 - real part LSB";
CM_ SG_ 365 StatusCPDData4FBD_VR_CIRData114 "contains CPD data to tap 29 - imaginary part MSB";
CM_ SG_ 365 StatusCPDData4FBD_VR_CIRData115 "contains CPD data to tap 29 - imaginary part LSB";
CM_ SG_ 365 StatusCPDData4FBD_VR_CIRData116 "contains CPD data to tap 30 - real part MSB";
CM_ SG_ 365 StatusCPDData4FBD_VR_CIRData117 "contains CPD data to tap 30 - real part LSB";
CM_ SG_ 365 StatusCPDData4FBD_VR_CIRData118 "contains CPD data to tap 30 - imaginary part MSB";
CM_ SG_ 365 StatusCPDData4FBD_VR_CIRData119 "contains CPD data to tap 30 - imaginary part LSB";
CM_ SG_ 196 StatusCSRangingFBD_HL_SessionID "contains the channel sounding session ID within the active connection";
CM_ SG_ 196 StatusCSRangingFBD_HL_IRKListInd "contains the connected BLE device";
CM_ SG_ 196 StatusCSRangingFBD_HL_Distance "contains the measured distance in cm";
CM_ SG_ 196 StatusCSRangingFBD_HL_ProcedureC "contains the procedure count";
CM_ SG_ 196 StatusCSRangingFBD_HL_Quality "contains the measurement quality based on the chip manufacturer implementation";
CM_ SG_ 196 StatusCSRangingFBD_HL_RoundTripT "defines the measured distance in cm based on RTT (RoundTripTime)";
CM_ SG_ 196 StatusCSRangingFBD_HL_IV00 "contains signature";
CM_ SG_ 196 StatusCSRangingFBD_HL_IV01 "contains signature";
CM_ SG_ 196 StatusCSRangingFBD_HL_IV02 "contains signature";
CM_ SG_ 196 StatusCSRangingFBD_HL_IV03 "contains signature";
CM_ SG_ 196 StatusCSRangingFBD_HL_Sign00 "contains signature";
CM_ SG_ 196 StatusCSRangingFBD_HL_Sign01 "contains signature";
CM_ SG_ 196 StatusCSRangingFBD_HL_Sign02 "contains signature";
CM_ SG_ 196 StatusCSRangingFBD_HL_Sign03 "contains signature";
CM_ SG_ 196 StatusCSRangingFBD_HL_Sign04 "contains signature";
CM_ SG_ 196 StatusCSRangingFBD_HL_Sign05 "contains signature";
CM_ SG_ 196 StatusCSRangingFBD_HL_Sign06 "contains signature";
CM_ SG_ 196 StatusCSRangingFBD_HL_Sign07 "contains signature";
CM_ SG_ 196 StatusCSRangingFBD_HL_Status1 "contains status";
CM_ SG_ 196 StatusCSRangingFBD_HL_Status2 "contains status";
CM_ SG_ 196 StatusCSRangingFBD_HL_NADM "contains Normalized Attack Detector Metric (NADM)";
CM_ SG_ 191 StatusCSRangingFBD_HM_SessionID "contains the channel sounding session ID within the active connection";
CM_ SG_ 191 StatusCSRangingFBD_HM_IRKListInd "contains the connected BLE device";
CM_ SG_ 191 StatusCSRangingFBD_HM_Distance "contains the measured distance in cm";
CM_ SG_ 191 StatusCSRangingFBD_HM_ProcedureC "contains the procedure count";
CM_ SG_ 191 StatusCSRangingFBD_HM_Quality "contains the measurement quality based on the chip manufacturer implementation";
CM_ SG_ 191 StatusCSRangingFBD_HM_RoundTripT "defines the measured distance in cm based on RTT (RoundTripTime)";
CM_ SG_ 191 StatusCSRangingFBD_HM_IV00 "contains signature";
CM_ SG_ 191 StatusCSRangingFBD_HM_IV01 "contains signature";
CM_ SG_ 191 StatusCSRangingFBD_HM_IV02 "contains signature";
CM_ SG_ 191 StatusCSRangingFBD_HM_IV03 "contains signature";
CM_ SG_ 191 StatusCSRangingFBD_HM_Sign00 "contains signature";
CM_ SG_ 191 StatusCSRangingFBD_HM_Sign01 "contains signature";
CM_ SG_ 191 StatusCSRangingFBD_HM_Sign02 "contains signature";
CM_ SG_ 191 StatusCSRangingFBD_HM_Sign03 "contains signature";
CM_ SG_ 191 StatusCSRangingFBD_HM_Sign04 "contains signature";
CM_ SG_ 191 StatusCSRangingFBD_HM_Sign05 "contains signature";
CM_ SG_ 191 StatusCSRangingFBD_HM_Sign06 "contains signature";
CM_ SG_ 191 StatusCSRangingFBD_HM_Sign07 "contains signature";
CM_ SG_ 191 StatusCSRangingFBD_HM_Status1 "contains status";
CM_ SG_ 191 StatusCSRangingFBD_HM_Status2 "contains status";
CM_ SG_ 191 StatusCSRangingFBD_HM_NADM "contains Normalized Attack Detector Metric (NADM)";
CM_ SG_ 197 StatusCSRangingFBD_HR_SessionID "contains the channel sounding session ID within the active connection";
CM_ SG_ 197 StatusCSRangingFBD_HR_IRKListInd "contains the connected BLE device";
CM_ SG_ 197 StatusCSRangingFBD_HR_Distance "contains the measured distance in cm";
CM_ SG_ 197 StatusCSRangingFBD_HR_ProcedureC "contains the procedure count";
CM_ SG_ 197 StatusCSRangingFBD_HR_Quality "contains the measurement quality based on the chip manufacturer implementation";
CM_ SG_ 197 StatusCSRangingFBD_HR_RoundTripT "defines the measured distance in cm based on RTT (RoundTripTime)";
CM_ SG_ 197 StatusCSRangingFBD_HR_IV00 "contains signature";
CM_ SG_ 197 StatusCSRangingFBD_HR_IV01 "contains signature";
CM_ SG_ 197 StatusCSRangingFBD_HR_IV02 "contains signature";
CM_ SG_ 197 StatusCSRangingFBD_HR_IV03 "contains signature";
CM_ SG_ 197 StatusCSRangingFBD_HR_Sign00 "contains signature";
CM_ SG_ 197 StatusCSRangingFBD_HR_Sign01 "contains signature";
CM_ SG_ 197 StatusCSRangingFBD_HR_Sign02 "contains signature";
CM_ SG_ 197 StatusCSRangingFBD_HR_Sign03 "contains signature";
CM_ SG_ 197 StatusCSRangingFBD_HR_Sign04 "contains signature";
CM_ SG_ 197 StatusCSRangingFBD_HR_Sign05 "contains signature";
CM_ SG_ 197 StatusCSRangingFBD_HR_Sign06 "contains signature";
CM_ SG_ 197 StatusCSRangingFBD_HR_Sign07 "contains signature";
CM_ SG_ 197 StatusCSRangingFBD_HR_Status1 "contains status";
CM_ SG_ 197 StatusCSRangingFBD_HR_Status2 "contains status";
CM_ SG_ 197 StatusCSRangingFBD_HR_NADM "contains Normalized Attack Detector Metric (NADM)";
CM_ SG_ 192 StatusCSRangingFBD_Miko_SessionI "contains the channel sounding session ID within the active connection";
CM_ SG_ 192 StatusCSRangingFBD_Miko_IRKListI "contains the connected BLE device";
CM_ SG_ 192 StatusCSRangingFBD_Miko_Distance "contains the measured distance in cm";
CM_ SG_ 192 StatusCSRangingFBD_Miko_Procedur "contains the procedure count";
CM_ SG_ 192 StatusCSRangingFBD_Miko_Quality "contains the measurement quality based on the chip manufacturer implementation";
CM_ SG_ 192 StatusCSRangingFBD_Miko_RoundTri "defines the measured distance in cm based on RTT (RoundTripTime)";
CM_ SG_ 192 StatusCSRangingFBD_Miko_IV00 "contains signature";
CM_ SG_ 192 StatusCSRangingFBD_Miko_IV01 "contains signature";
CM_ SG_ 192 StatusCSRangingFBD_Miko_IV02 "contains signature";
CM_ SG_ 192 StatusCSRangingFBD_Miko_IV03 "contains signature";
CM_ SG_ 192 StatusCSRangingFBD_Miko_Sign00 "contains signature";
CM_ SG_ 192 StatusCSRangingFBD_Miko_Sign01 "contains signature";
CM_ SG_ 192 StatusCSRangingFBD_Miko_Sign02 "contains signature";
CM_ SG_ 192 StatusCSRangingFBD_Miko_Sign03 "contains signature";
CM_ SG_ 192 StatusCSRangingFBD_Miko_Sign04 "contains signature";
CM_ SG_ 192 StatusCSRangingFBD_Miko_Sign05 "contains signature";
CM_ SG_ 192 StatusCSRangingFBD_Miko_Sign06 "contains signature";
CM_ SG_ 192 StatusCSRangingFBD_Miko_Sign07 "contains signature";
CM_ SG_ 192 StatusCSRangingFBD_Miko_Status1 "contains status";
CM_ SG_ 192 StatusCSRangingFBD_Miko_Status2 "contains status";
CM_ SG_ 192 StatusCSRangingFBD_Miko_NADM "contains Normalized Attack Detector Metric (NADM)";
CM_ SG_ 198 StatusCSRangingFBD_MM_SessionID "contains the channel sounding session ID within the active connection";
CM_ SG_ 198 StatusCSRangingFBD_MM_IRKListInd "contains the connected BLE device";
CM_ SG_ 198 StatusCSRangingFBD_MM_Distance "contains the measured distance in cm";
CM_ SG_ 198 StatusCSRangingFBD_MM_ProcedureC "contains the procedure count";
CM_ SG_ 198 StatusCSRangingFBD_MM_Quality "contains the measurement quality based on the chip manufacturer implementation";
CM_ SG_ 198 StatusCSRangingFBD_MM_RoundTripT "defines the measured distance in cm based on RTT (RoundTripTime)";
CM_ SG_ 198 StatusCSRangingFBD_MM_IV00 "contains signature";
CM_ SG_ 198 StatusCSRangingFBD_MM_IV01 "contains signature";
CM_ SG_ 198 StatusCSRangingFBD_MM_IV02 "contains signature";
CM_ SG_ 198 StatusCSRangingFBD_MM_IV03 "contains signature";
CM_ SG_ 198 StatusCSRangingFBD_MM_Sign00 "contains signature";
CM_ SG_ 198 StatusCSRangingFBD_MM_Sign01 "contains signature";
CM_ SG_ 198 StatusCSRangingFBD_MM_Sign02 "contains signature";
CM_ SG_ 198 StatusCSRangingFBD_MM_Sign03 "contains signature";
CM_ SG_ 198 StatusCSRangingFBD_MM_Sign04 "contains signature";
CM_ SG_ 198 StatusCSRangingFBD_MM_Sign05 "contains signature";
CM_ SG_ 198 StatusCSRangingFBD_MM_Sign06 "contains signature";
CM_ SG_ 198 StatusCSRangingFBD_MM_Sign07 "contains signature";
CM_ SG_ 198 StatusCSRangingFBD_MM_Status1 "contains status";
CM_ SG_ 198 StatusCSRangingFBD_MM_Status2 "contains status";
CM_ SG_ 198 StatusCSRangingFBD_MM_NADM "contains Normalized Attack Detector Metric (NADM)";
CM_ SG_ 193 StatusCSRangingFBD_Trunk_Session "contains the channel sounding session ID within the active connection";
CM_ SG_ 193 StatusCSRangingFBD_Trunk_IRKList "contains the connected BLE device";
CM_ SG_ 193 StatusCSRangingFBD_Trunk_Distanc "contains the measured distance in cm";
CM_ SG_ 193 StatusCSRangingFBD_Trunk_Procedu "contains the procedure count";
CM_ SG_ 193 StatusCSRangingFBD_Trunk_Quality "contains the measurement quality based on the chip manufacturer implementation";
CM_ SG_ 193 StatusCSRangingFBD_Trunk_RoundTr "defines the measured distance in cm based on RTT (RoundTripTime)";
CM_ SG_ 193 StatusCSRangingFBD_Trunk_IV00 "contains signature";
CM_ SG_ 193 StatusCSRangingFBD_Trunk_IV01 "contains signature";
CM_ SG_ 193 StatusCSRangingFBD_Trunk_IV02 "contains signature";
CM_ SG_ 193 StatusCSRangingFBD_Trunk_IV03 "contains signature";
CM_ SG_ 193 StatusCSRangingFBD_Trunk_Sign00 "contains signature";
CM_ SG_ 193 StatusCSRangingFBD_Trunk_Sign01 "contains signature";
CM_ SG_ 193 StatusCSRangingFBD_Trunk_Sign02 "contains signature";
CM_ SG_ 193 StatusCSRangingFBD_Trunk_Sign03 "contains signature";
CM_ SG_ 193 StatusCSRangingFBD_Trunk_Sign04 "contains signature";
CM_ SG_ 193 StatusCSRangingFBD_Trunk_Sign05 "contains signature";
CM_ SG_ 193 StatusCSRangingFBD_Trunk_Sign06 "contains signature";
CM_ SG_ 193 StatusCSRangingFBD_Trunk_Sign07 "contains signature";
CM_ SG_ 193 StatusCSRangingFBD_Trunk_Status1 "contains status";
CM_ SG_ 193 StatusCSRangingFBD_Trunk_Status2 "contains status";
CM_ SG_ 193 StatusCSRangingFBD_Trunk_NADM "contains Normalized Attack Detector Metric (NADM)";
CM_ SG_ 194 StatusCSRangingFBD_VL_SessionID "contains the channel sounding session ID within the active connection";
CM_ SG_ 194 StatusCSRangingFBD_VL_IRKListInd "contains the connected BLE device";
CM_ SG_ 194 StatusCSRangingFBD_VL_Distance "contains the measured distance in cm";
CM_ SG_ 194 StatusCSRangingFBD_VL_ProcedureC "contains the procedure count";
CM_ SG_ 194 StatusCSRangingFBD_VL_Quality "contains the measurement quality based on the chip manufacturer implementation";
CM_ SG_ 194 StatusCSRangingFBD_VL_RoundTripT "defines the measured distance in cm based on RTT (RoundTripTime)";
CM_ SG_ 194 StatusCSRangingFBD_VL_IV00 "contains signature";
CM_ SG_ 194 StatusCSRangingFBD_VL_IV01 "contains signature";
CM_ SG_ 194 StatusCSRangingFBD_VL_IV02 "contains signature";
CM_ SG_ 194 StatusCSRangingFBD_VL_IV03 "contains signature";
CM_ SG_ 194 StatusCSRangingFBD_VL_Sign00 "contains signature";
CM_ SG_ 194 StatusCSRangingFBD_VL_Sign01 "contains signature";
CM_ SG_ 194 StatusCSRangingFBD_VL_Sign02 "contains signature";
CM_ SG_ 194 StatusCSRangingFBD_VL_Sign03 "contains signature";
CM_ SG_ 194 StatusCSRangingFBD_VL_Sign04 "contains signature";
CM_ SG_ 194 StatusCSRangingFBD_VL_Sign05 "contains signature";
CM_ SG_ 194 StatusCSRangingFBD_VL_Sign06 "contains signature";
CM_ SG_ 194 StatusCSRangingFBD_VL_Sign07 "contains signature";
CM_ SG_ 194 StatusCSRangingFBD_VL_Status1 "contains status";
CM_ SG_ 194 StatusCSRangingFBD_VL_Status2 "contains status";
CM_ SG_ 194 StatusCSRangingFBD_VL_NADM "contains Normalized Attack Detector Metric (NADM)";
CM_ SG_ 190 StatusCSRangingFBD_VM_SessionID "contains the channel sounding session ID within the active connection";
CM_ SG_ 190 StatusCSRangingFBD_VM_IRKListInd "contains the connected BLE device";
CM_ SG_ 190 StatusCSRangingFBD_VM_Distance "contains the measured distance in cm";
CM_ SG_ 190 StatusCSRangingFBD_VM_ProcedureC "contains the procedure count";
CM_ SG_ 190 StatusCSRangingFBD_VM_Quality "contains the measurement quality based on the chip manufacturer implementation";
CM_ SG_ 190 StatusCSRangingFBD_VM_RoundTripT "defines the measured distance in cm based on RTT (RoundTripTime)";
CM_ SG_ 190 StatusCSRangingFBD_VM_IV00 "contains signature";
CM_ SG_ 190 StatusCSRangingFBD_VM_IV01 "contains signature";
CM_ SG_ 190 StatusCSRangingFBD_VM_IV02 "contains signature";
CM_ SG_ 190 StatusCSRangingFBD_VM_IV03 "contains signature";
CM_ SG_ 190 StatusCSRangingFBD_VM_Sign00 "contains signature";
CM_ SG_ 190 StatusCSRangingFBD_VM_Sign01 "contains signature";
CM_ SG_ 190 StatusCSRangingFBD_VM_Sign02 "contains signature";
CM_ SG_ 190 StatusCSRangingFBD_VM_Sign03 "contains signature";
CM_ SG_ 190 StatusCSRangingFBD_VM_Sign04 "contains signature";
CM_ SG_ 190 StatusCSRangingFBD_VM_Sign05 "contains signature";
CM_ SG_ 190 StatusCSRangingFBD_VM_Sign06 "contains signature";
CM_ SG_ 190 StatusCSRangingFBD_VM_Sign07 "contains signature";
CM_ SG_ 190 StatusCSRangingFBD_VM_Status1 "contains status";
CM_ SG_ 190 StatusCSRangingFBD_VM_Status2 "contains status";
CM_ SG_ 190 StatusCSRangingFBD_VM_NADM "contains Normalized Attack Detector Metric (NADM)";
CM_ SG_ 195 StatusCSRangingFBD_VR_SessionID "contains the channel sounding session ID within the active connection";
CM_ SG_ 195 StatusCSRangingFBD_VR_IRKListInd "contains the connected BLE device";
CM_ SG_ 195 StatusCSRangingFBD_VR_Distance "contains the measured distance in cm";
CM_ SG_ 195 StatusCSRangingFBD_VR_ProcedureC "contains the procedure count";
CM_ SG_ 195 StatusCSRangingFBD_VR_Quality "contains the measurement quality based on the chip manufacturer implementation";
CM_ SG_ 195 StatusCSRangingFBD_VR_RoundTripT "defines the measured distance in cm based on RTT (RoundTripTime)";
CM_ SG_ 195 StatusCSRangingFBD_VR_IV00 "contains signature";
CM_ SG_ 195 StatusCSRangingFBD_VR_IV01 "contains signature";
CM_ SG_ 195 StatusCSRangingFBD_VR_IV02 "contains signature";
CM_ SG_ 195 StatusCSRangingFBD_VR_IV03 "contains signature";
CM_ SG_ 195 StatusCSRangingFBD_VR_Sign00 "contains signature";
CM_ SG_ 195 StatusCSRangingFBD_VR_Sign01 "contains signature";
CM_ SG_ 195 StatusCSRangingFBD_VR_Sign02 "contains signature";
CM_ SG_ 195 StatusCSRangingFBD_VR_Sign03 "contains signature";
CM_ SG_ 195 StatusCSRangingFBD_VR_Sign04 "contains signature";
CM_ SG_ 195 StatusCSRangingFBD_VR_Sign05 "contains signature";
CM_ SG_ 195 StatusCSRangingFBD_VR_Sign06 "contains signature";
CM_ SG_ 195 StatusCSRangingFBD_VR_Sign07 "contains signature";
CM_ SG_ 195 StatusCSRangingFBD_VR_Status1 "contains status";
CM_ SG_ 195 StatusCSRangingFBD_VR_Status2 "contains status";
CM_ SG_ 195 StatusCSRangingFBD_VR_NADM "contains Normalized Attack Detector Metric (NADM)";
CM_ SG_ 596 StatusCSReportingFBD_HL_Error "contains CS error code";
CM_ SG_ 596 StatusCSReportingFBD_HL_Diagnosi "contains diagnostic information";
CM_ SG_ 596 StatusCSReportingFBD_HL_Status1 "contains status information";
CM_ SG_ 596 StatusCSReportingFBD_HL_Status2 "contains status information";
CM_ SG_ 591 StatusCSReportingFBD_HM_Error "contains CS error code";
CM_ SG_ 591 StatusCSReportingFBD_HM_Diagnosi "contains diagnostic information";
CM_ SG_ 591 StatusCSReportingFBD_HM_Status1 "contains status information";
CM_ SG_ 591 StatusCSReportingFBD_HM_Status2 "contains status information";
CM_ SG_ 597 StatusCSReportingFBD_HR_Error "contains CS error code";
CM_ SG_ 597 StatusCSReportingFBD_HR_Diagnosi "contains diagnostic information";
CM_ SG_ 597 StatusCSReportingFBD_HR_Status1 "contains status information";
CM_ SG_ 597 StatusCSReportingFBD_HR_Status2 "contains status information";
CM_ SG_ 592 StatusCSReportingFBD_Miko_Error "contains CS error code";
CM_ SG_ 592 StatusCSReportingFBD_Miko_Diagno "contains diagnostic information";
CM_ SG_ 592 StatusCSReportingFBD_Miko_Status "contains status information";
CM_ SG_ 592 StatusCSReportingFBD_Miko_Stat_2 "contains status information";
CM_ SG_ 598 StatusCSReportingFBD_MM_Error "contains CS error code";
CM_ SG_ 598 StatusCSReportingFBD_MM_Diagnosi "contains diagnostic information";
CM_ SG_ 598 StatusCSReportingFBD_MM_Status1 "contains status information";
CM_ SG_ 598 StatusCSReportingFBD_MM_Status2 "contains status information";
CM_ SG_ 593 StatusCSReportingFBD_Trunk_Error "contains CS error code";
CM_ SG_ 593 StatusCSReportingFBD_Trunk_Diagn "contains diagnostic information";
CM_ SG_ 593 StatusCSReportingFBD_Trunk_Statu "contains status information";
CM_ SG_ 593 StatusCSReportingFBD_Trunk_Sta_2 "contains status information";
CM_ SG_ 594 StatusCSReportingFBD_VL_Error "contains CS error code";
CM_ SG_ 594 StatusCSReportingFBD_VL_Diagnosi "contains diagnostic information";
CM_ SG_ 594 StatusCSReportingFBD_VL_Status1 "contains status information";
CM_ SG_ 594 StatusCSReportingFBD_VL_Status2 "contains status information";

BA_DEF_ BO_ "VFrameFormat" ENUM "StandardCAN","ExtendedCAN","reserved","J1939PG","reserved","reserved","reserved","reserved","reserved","reserved","reserved","reserved","reserved","reserved","StandardCAN_FD","ExtendedCAN_FD";
BA_DEF_DEF_ "VFrameFormat" "StandardCAN";
BA_ "VFrameFormat" BO_ 352 14;
BA_ "VFrameFormat" BO_ 835 14;
BA_ "VFrameFormat" BO_ 353 14;
BA_ "VFrameFormat" BO_ 354 14;
BA_ "VFrameFormat" BO_ 350 14;
BA_ "VFrameFormat" BO_ 355 14;
BA_ "VFrameFormat" BO_ 366 14;
BA_ "VFrameFormat" BO_ 361 14;
BA_ "VFrameFormat" BO_ 367 14;
BA_ "VFrameFormat" BO_ 362 14;
BA_ "VFrameFormat" BO_ 836 14;
BA_ "VFrameFormat" BO_ 363 14;
BA_ "VFrameFormat" BO_ 364 14;
BA_ "VFrameFormat" BO_ 360 14;
BA_ "VFrameFormat" BO_ 365 14;
BA_ "VFrameFormat" BO_ 196 14;
BA_ "VFrameFormat" BO_ 191 14;
BA_ "VFrameFormat" BO_ 197 14;
BA_ "VFrameFormat" BO_ 192 14;
BA_ "VFrameFormat" BO_ 198 14;
BA_ "VFrameFormat" BO_ 193 14;
BA_ "VFrameFormat" BO_ 194 14;
BA_ "VFrameFormat" BO_ 190 14;
BA_ "VFrameFormat" BO_ 195 14;
